VERSION ""

NS_ :

BS_:

BU_: ETH

BO_ 1339 VCBATT1_alertLog: 8 Vector__XXX
 SG_ VCBATT1_alertID M : 0|10@1+ (1,0) [0|0] "" Vector__XXX
 SG_ VCBATT1_alertState : 15|1@1+ (1,0) [0|0] "" Vector__XXX
 SG_ VCBATT1_a001_InternalWatchdog m1 : 16|1@1+ (1,0) [0|0] "" Vector__XXX
 SG_ VCBATT1_a002_CPUUndervoltage m2 : 16|1@1+ (1,0) [0|0] "" Vector__XXX
 SG_ VCBATT1_a003_AssertID m3 : 16|16@1+ (1,0) [0|0] "" Vector__XXX
 SG_ VCBATT1_a005_busID0 m5 : 16|4@1+ (1,0) [0|0] "" Vector__XXX
 SG_ VCBATT1_a006_busID m6 : 16|4@1+ (1,0) [0|0] "" Vector__XXX
 SG_ VCBATT1_a012_ClockError m12 : 16|1@1+ (1,0) [0|0] "" Vector__XXX
 SG_ VCBATT1_a013_LogQueueFull m13 : 16|1@1+ (1,0) [0|0] "" Vector__XXX
 SG_ VCBATT1_a015_NVMMMemOverflow m15 : 16|1@1+ (1,0) [0|0] "" Vector__XXX
 SG_ VCBATT1_a016_NVMMRecordID m16 : 16|16@1+ (1,0) [0|0] "" Vector__XXX
 SG_ VCBATT1_a017_NVMMLifetimeEraseCycles m17 : 16|32@1+ (1,0) [0|0] "" Vector__XXX
 SG_ VCBATT1_a018_DEBUGEVT m18 : 16|1@1+ (1,0) [0|0] "" Vector__XXX
 SG_ VCBATT1_a019_BFARVALID m19 : 16|1@1+ (1,0) [0|0] "" Vector__XXX
 SG_ VCBATT1_a021_Task1msLate m21 : 16|1@1+ (1,0) [0|0] "" Vector__XXX
 SG_ VCBATT1_a022_TaskInitErrorCount m22 : 16|8@1+ (1,0) [0|0] "" Vector__XXX
 SG_ VCBATT1_a028_DivideByZero m28 : 16|1@1+ (1,0) [0|0] "" Vector__XXX
 SG_ VCBATT1_a030_logId m30 : 16|4@1+ (1,0) [0|0] "" Vector__XXX
 SG_ VCBATT1_a031_uds_bytes_0 m31 : 16|8@1+ (1,0) [0|0] "" Vector__XXX
 SG_ VCBATT1_a036_ipsr m36 : 16|8@1+ (1,0) [0|0] "" Vector__XXX
 SG_ VCBATT1_a037_MMFARVALID m37 : 16|1@1+ (1,0) [0|0] "" Vector__XXX
 SG_ VCBATT1_a038_faultType m38 : 16|2@1+ (1,0) [0|0] "" Vector__XXX
 SG_ VCBATT1_a039_faultType m39 : 16|2@1+ (1,0) [0|0] "" Vector__XXX
 SG_ VCBATT1_a040_depth m40 : 16|4@1+ (1,0) [0|0] "" Vector__XXX
 SG_ VCBATT1_a041_CPULoadTotal m41 : 16|8@1+ (1,0) [0|0] "" Vector__XXX
 SG_ VCBATT1_a042_Usage1msTask m42 : 16|8@1+ (1,0) [0|0] "" Vector__XXX
 SG_ VCBATT1_a043_CallTrace0 m43 : 16|24@1+ (1,0) [0|0] "" Vector__XXX
 SG_ VCBATT1_a044_CallTrace0 m44 : 16|24@1+ (1,0) [0|0] "" Vector__XXX
 SG_ VCBATT1_a045_CallTrace0 m45 : 16|24@1+ (1,0) [0|0] "" Vector__XXX
 SG_ VCBATT1_a046_CallTrace0 m46 : 16|24@1+ (1,0) [0|0] "" Vector__XXX
 SG_ VCBATT1_a058_voltageDrop m58 : 16|12@1+ (0.005443676098,0) [0|0] "" Vector__XXX
 SG_ VCBATT1_a059_voltageDrop m59 : 16|12@1+ (0.005443676098,0) [0|0] "" Vector__XXX
 SG_ VCBATT1_a060_lockoutDisabled m60 : 16|1@1+ (1,0) [0|0] "" Vector__XXX
 SG_ VCBATT1_a063_switchChannel m63 : 16|8@1+ (1,0) [0|0] "" Vector__XXX
 SG_ VCBATT1_a064_busBitField m64 : 16|8@1+ (1,0) [0|0] "" Vector__XXX
 SG_ VCBATT1_a077_BATTIPC_battIpcData0 m77 : 16|1@1+ (1,0) [0|0] "" Vector__XXX
 SG_ VCBATT1_a078_FRONTIPC_frontprivData0 m78 : 16|1@1+ (1,0) [0|0] "" Vector__XXX
 SG_ VCBATT1_a079_FRONTIPC_frontprivData0 m79 : 16|1@1+ (1,0) [0|0] "" Vector__XXX
 SG_ VCBATT1_a080_FRONTIPC_frontIpcData0 m80 : 16|1@1+ (1,0) [0|0] "" Vector__XXX
 SG_ VCBATT1_a081_FRONTIPC_vehNm m81 : 16|1@1+ (1,0) [0|0] "" Vector__XXX
 SG_ VCBATT1_a082_FRONTIPC_frontprivData0 m82 : 16|1@1+ (1,0) [0|0] "" Vector__XXX
 SG_ VCBATT1_a086_FRONTIPC_vehNm m86 : 16|1@1+ (1,0) [0|0] "" Vector__XXX
 SG_ VCBATT1_a090_FRONTIPC_chNm m90 : 16|1@1+ (1,0) [0|0] "" Vector__XXX
 SG_ VCBATT1_a091_FRONTIPC_faultsAndExtras m91 : 16|1@1+ (1,0) [0|0] "" Vector__XXX
 SG_ VCBATT1_a096_FRONTIPC_status m96 : 16|1@1+ (1,0) [0|0] "" Vector__XXX
 SG_ VCBATT1_a098_FRONTIPC_temperature m98 : 16|1@1+ (1,0) [0|0] "" Vector__XXX
 SG_ VCBATT1_a100_BATTIPC m100 : 16|1@1+ (1,0) [0|0] "" Vector__XXX
 SG_ VCBATT1_a103_FRONTIPC_hvsNm m103 : 16|1@1+ (1,0) [0|0] "" Vector__XXX
 SG_ VCBATT1_a104_FRONTIPC_chNm m104 : 16|1@1+ (1,0) [0|0] "" Vector__XXX
 SG_ VCBATT1_a105_FRONTIPC_chNm m105 : 16|1@1+ (1,0) [0|0] "" Vector__XXX
 SG_ VCBATT1_a106_BATTIPC_dcdcRailStatus m106 : 16|1@1+ (1,0) [0|0] "" Vector__XXX
 SG_ VCBATT1_a107_FRONTIPC_vehNm m107 : 16|1@1+ (1,0) [0|0] "" Vector__XXX
 SG_ VCBATT1_a108_FRONTIPC_status m108 : 16|1@1+ (1,0) [0|0] "" Vector__XXX
 SG_ VCBATT1_a110_BATTIPC_carConfig m110 : 16|1@1+ (1,0) [0|0] "" Vector__XXX
 SG_ VCBATT1_a111_FRONTIPC_vehNm m111 : 16|1@1+ (1,0) [0|0] "" Vector__XXX
 SG_ VCBATT1_a112_FRONTIPC_vehNm m112 : 16|1@1+ (1,0) [0|0] "" Vector__XXX
 SG_ VCBATT1_a113_FRONTIPC_ethNm m113 : 16|1@1+ (1,0) [0|0] "" Vector__XXX
 SG_ VCBATT1_a114_BATTIPC_wheelRotation m114 : 16|1@1+ (1,0) [0|0] "" Vector__XXX
 SG_ VCBATT1_a115_FRONTIPC_vehNm m115 : 16|1@1+ (1,0) [0|0] "" Vector__XXX
 SG_ VCBATT1_a116_FRONTIPC_vehNm m116 : 16|1@1+ (1,0) [0|0] "" Vector__XXX
 SG_ VCBATT1_a117_FRONTIPC_vehNm m117 : 16|1@1+ (1,0) [0|0] "" Vector__XXX
 SG_ VCBATT1_a118_FRONTIPC_vehNm m118 : 16|1@1+ (1,0) [0|0] "" Vector__XXX
 SG_ VCBATT1_a119_FRONTIPC_leftStalk m119 : 16|1@1+ (1,0) [0|0] "" Vector__XXX
 SG_ VCBATT1_a120_BATTIPC_speed m120 : 16|1@1+ (1,0) [0|0] "" Vector__XXX
 SG_ VCBATT1_a122_FRONTIPC_status m122 : 16|1@1+ (1,0) [0|0] "" Vector__XXX
 SG_ VCBATT1_a124_FRONTIPC_status m124 : 16|1@1+ (1,0) [0|0] "" Vector__XXX
 SG_ VCBATT1_a125_FRONTIPC_leftStalk m125 : 16|1@1+ (1,0) [0|0] "" Vector__XXX
 SG_ VCBATT1_a126_FRONTIPC_sysStatus m126 : 16|1@1+ (1,0) [0|0] "" Vector__XXX
 SG_ VCBATT1_a127_vcleftEFuseCurrent m127 : 16|16@1+ (0.1,0) [0|0] "" Vector__XXX
 SG_ VCBATT1_a129_epas1EFuseCurrent m129 : 16|16@1+ (0.1,0) [0|0] "" Vector__XXX
 SG_ VCBATT1_a130_autopilot1EFuseCurrent m130 : 16|16@1+ (0.1,0) [0|0] "" Vector__XXX
 SG_ VCBATT1_a131_FRONTIPC_power m131 : 16|1@1+ (1,0) [0|0] "" Vector__XXX
 SG_ VCBATT1_a132_iBoosterCurrent m132 : 16|16@1+ (0.1,0) [0|0] "" Vector__XXX
 SG_ VCBATT1_a133_BATTIPC_primaryActuator m133 : 16|1@1+ (1,0) [0|0] "" Vector__XXX
 SG_ VCBATT1_a134_hvContactorsEFuseCurrent m134 : 16|16@1+ (0.1,0) [0|0] "" Vector__XXX
 SG_ VCBATT1_a144_FRONTIPC_status m144 : 16|1@1+ (1,0) [0|0] "" Vector__XXX
 SG_ VCBATT1_a164_lockoutVoltage m164 : 16|16@1+ (0.1,0) [0|0] "" Vector__XXX
 SG_ VCBATT1_a165_lockoutVoltage m165 : 16|16@1+ (0.1,0) [0|0] "" Vector__XXX
 SG_ VCBATT1_a180_vehiclePowerState m180 : 16|2@1+ (1,0) [0|0] "" Vector__XXX
 SG_ VCBATT1_a182_deadLV m182 : 16|1@1+ (1,0) [0|0] "" Vector__XXX
 SG_ VCBATT1_a183_deadLV m183 : 16|1@1+ (1,0) [0|0] "" Vector__XXX
 SG_ VCBATT1_a188_sleepBypassCurrent m188 : 16|8@1+ (0.2,0) [0|0] "" Vector__XXX
 SG_ VCBATT1_a191_vehiclePowerState m191 : 16|2@1+ (1,0) [0|0] "" Vector__XXX
 SG_ VCBATT1_a196_factoryMode m196 : 16|1@1+ (1,0) [0|0] "" Vector__XXX
 SG_ VCBATT1_a204_vbusVoltage m204 : 16|10@1+ (0.025,0) [0|0] "" Vector__XXX
 SG_ VCBATT1_a205_busVoltage m205 : 16|10@1+ (0.025,0) [0|0] "" Vector__XXX
 SG_ VCBATT1_a212_IBSTemp m212 : 16|16@1- (0.01,0) [0|0] "" Vector__XXX
 SG_ VCBATT1_a213_IBSVolts m213 : 16|12@1+ (0.005443676098,0) [0|0] "" Vector__XXX
 SG_ VCBATT1_a215_startReason m215 : 16|3@1+ (1,0) [0|0] "" Vector__XXX
 SG_ VCBATT1_a216_inDrive m216 : 16|1@1+ (1,0) [0|0] "" Vector__XXX
 SG_ VCBATT1_a217_startReason m217 : 16|3@1+ (1,0) [0|0] "" Vector__XXX
 SG_ VCBATT1_a219_IBSVolts m219 : 16|12@1+ (0.005443676098,0) [0|0] "" Vector__XXX
 SG_ VCBATT1_a220_DI_gear m220 : 16|3@1+ (1,0) [0|0] "" Vector__XXX
 SG_ VCBATT1_a221_IBSCurrent m221 : 16|16@1- (0.005,0) [0|0] "" Vector__XXX
 SG_ VCBATT1_a223_failedArmingSetup m223 : 16|1@1+ (1,0) [0|0] "" Vector__XXX
 SG_ VCBATT1_a224_ocSenseAmpCurrent m224 : 16|12@1+ (0.1,0) [0|0] "" Vector__XXX
 SG_ VCBATT1_a225_ocSelfTestFailureReason m225 : 16|7@1+ (1,0) [0|0] "" Vector__XXX
 SG_ VCBATT1_a226_channelFailureReason m226 : 16|7@1+ (1,0) [0|0] "" Vector__XXX
 SG_ VCBATT1_a227_channelFailureReason m227 : 16|7@1+ (1,0) [0|0] "" Vector__XXX
 SG_ VCBATT1_a228_channelFailureReason m228 : 16|7@1+ (1,0) [0|0] "" Vector__XXX
 SG_ VCBATT1_a229_bridgeOpened m229 : 16|1@1+ (1,0) [0|0] "" Vector__XXX
 SG_ VCBATT1_a230_channelFailureReason m230 : 16|7@1+ (1,0) [0|0] "" Vector__XXX
 SG_ VCBATT1_a235_hvcRightDomainFailureReason m235 : 16|3@1+ (1,0) [0|0] "" Vector__XXX
 SG_ VCBATT1_a236_checkPowerFromRightDomain m236 : 16|1@1+ (1,0) [0|0] "" Vector__XXX
 SG_ VCBATT1_a243_IBSVolts m243 : 16|12@1+ (0.005443676098,0) [0|0] "" Vector__XXX
 SG_ VCBATT1_a244_brakeValveECUEFuseCurrent m244 : 16|16@1+ (0.1,0) [0|0] "" Vector__XXX
 SG_ VCBATT1_a245_current m245 : 16|16@1+ (0.1,0) [0|0] "" Vector__XXX
 SG_ VCBATT1_a252_IBSVoltage m252 : 16|12@1+ (0.005443676098,0) [0|0] "" Vector__XXX
 SG_ VCBATT1_a253_currentNotTapered m253 : 16|1@1+ (1,0) [0|0] "" Vector__XXX
 SG_ VCBATT1_a258_minVoltageReached m258 : 16|12@1+ (0.005443676098,0) [0|0] "" Vector__XXX
 SG_ VCBATT1_a259_serviceMode m259 : 16|1@1+ (1,0) [0|0] "" Vector__XXX
 SG_ VCBATT1_a260_IBSVolts m260 : 16|12@1+ (0.005443676098,0) [0|0] "" Vector__XXX
 SG_ VCBATT1_a275_breakLocationA m275 : 16|5@1+ (1,0) [0|0] "" Vector__XXX
 SG_ VCBATT1_a276_breakLocationA m276 : 16|5@1+ (1,0) [0|0] "" Vector__XXX
 SG_ VCBATT1_a277_bmbDeviceMask m277 : 16|16@1+ (1,0) [0|0] "" Vector__XXX
 SG_ VCBATT1_a297_bmbDeviceId m297 : 16|4@1+ (1,1) [0|0] "" Vector__XXX
 SG_ VCBATT1_a359_IBSVolts m359 : 16|12@1+ (0.005443676098,0) [0|0] "" Vector__XXX
 SG_ VCBATT1_a363_minBleedCharge m363 : 16|15@1+ (0.001,0) [0|0] "" Vector__XXX
 SG_ VCBATT1_a370_IBSVolts m370 : 16|12@1+ (0.005443676098,0) [0|0] "" Vector__XXX
 SG_ VCBATT1_a371_shortedCellTestTrigger m371 : 16|1@1+ (1,0) [0|0] "" Vector__XXX
 SG_ VCBATT1_a372_bmbDeviceId m372 : 16|4@1+ (1,1) [0|0] "" Vector__XXX
 SG_ VCBATT1_a376_IBSCurrentSampleCount m376 : 16|16@1+ (1,0) [0|0] "" Vector__XXX
 SG_ VCBATT1_a379_minVoltageReached m379 : 16|12@1+ (0.005443676098,0) [0|0] "" Vector__XXX
 SG_ VCBATT1_a387_shortedCellFaultCounter m387 : 16|3@1+ (1,0) [0|0] "" Vector__XXX
 SG_ VCBATT1_a388_shortedCellFaultCounter m388 : 16|3@1+ (1,0) [0|0] "" Vector__XXX
 SG_ VCBATT1_a392_bmbDeviceId m392 : 16|4@1+ (1,1) [0|0] "" Vector__XXX
 SG_ VCBATT1_a400_VrefSample m400 : 16|16@1+ (0.0001,0) [0|0] "" Vector__XXX
 SG_ VCBATT1_a401_LVBatteryTemp m401 : 16|7@1+ (1,-40) [0|0] "" Vector__XXX
 SG_ VCBATT1_a402_LVBatteryTemp m402 : 16|7@1+ (1,-40) [0|0] "" Vector__XXX
 SG_ VCBATT1_a403_IBSCurrent m403 : 16|15@1- (0.005,0) [0|0] "" Vector__XXX
 SG_ VCBATT1_a404_minVoltageReached m404 : 16|12@1+ (0.005443676098,0) [0|0] "" Vector__XXX
 SG_ VCBATT1_a405_dcrMilliOhms m405 : 16|8@1+ (0.2,0) [0|0] "" Vector__XXX
 SG_ VCBATT1_a406_pulseVoltage1 m406 : 16|8@1+ (0.02,9) [0|0] "" Vector__XXX
 SG_ VCBATT1_a407_dcrMilliOhms m407 : 16|8@1+ (0.2,0) [0|0] "" Vector__XXX
 SG_ VCBATT1_a408_IBSCurrent m408 : 16|16@1- (0.005,0) [0|0] "" Vector__XXX
 SG_ VCBATT1_a410_LVBatteryTemp m410 : 16|7@1+ (1,-40) [0|0] "" Vector__XXX
 SG_ VCBATT1_a411_LVBatteryTemp m411 : 16|7@1+ (1,-40) [0|0] "" Vector__XXX
 SG_ VCBATT1_a412_dcrMilliOhmsShifted m412 : 16|8@1+ (0.2,0) [0|0] "" Vector__XXX
 SG_ VCBATT1_a413_VrefSample m413 : 16|16@1+ (0.0001,0) [0|0] "" Vector__XXX
 SG_ VCBATT1_a414_failureReason m414 : 16|6@1+ (1,0) [0|0] "" Vector__XXX
 SG_ VCBATT1_a415_upstreamEFuseStuckOff m415 : 16|1@1+ (1,0) [0|0] "" Vector__XXX
 SG_ VCBATT1_a416_brickVoltageMin m416 : 16|10@1+ (0.005,0) [0|0] "" Vector__XXX
 SG_ VCBATT1_a417_brickVoltageMin m417 : 16|10@1+ (0.005,0) [0|0] "" Vector__XXX
 SG_ VCBATT1_a418_brickVoltageMin m418 : 16|10@1+ (0.005,0) [0|0] "" Vector__XXX
 SG_ VCBATT1_a419_brickVoltageMin m419 : 16|10@1+ (0.005,0) [0|0] "" Vector__XXX
 SG_ VCBATT1_a420_retryResult m420 : 16|3@1+ (1,0) [0|0] "" Vector__XXX
 SG_ VCBATT1_a422_allBusesSleeping m422 : 16|1@1+ (1,0) [0|0] "" Vector__XXX
 SG_ VCBATT1_a423_brickVoltageMin m423 : 16|10@1+ (0.005,0) [0|0] "" Vector__XXX
 SG_ VCBATT1_a424_brickVoltageMin m424 : 16|10@1+ (0.005,0) [0|0] "" Vector__XXX
 SG_ VCBATT1_a425_busVoltage m425 : 16|16@1+ (0.002,0) [0|0] "" Vector__XXX
 SG_ VCBATT1_a426_busVoltage m426 : 16|16@1+ (0.002,0) [0|0] "" Vector__XXX
 SG_ VCBATT1_a427_initialSoc m427 : 16|9@1+ (0.2,0) [0|0] "" Vector__XXX
 SG_ VCBATT1_a428_minBrickCacId m428 : 16|7@1+ (1,1) [0|0] "" Vector__XXX
 SG_ VCBATT1_a429_sohTestEndMode m429 : 16|4@1+ (1,0) [0|0] "" Vector__XXX
 SG_ VCBATT1_a430_netPackCurrent m430 : 16|16@1- (0.1,0) [0|0] "" Vector__XXX
 SG_ VCBATT1_a431_netPackCurrent m431 : 16|16@1- (0.1,0) [0|0] "" Vector__XXX
 SG_ VCBATT1_a432_targetCurrent m432 : 16|16@1- (0.1,0) [0|0] "" Vector__XXX
 SG_ VCBATT1_a433_bmbModuleId m433 : 16|16@1+ (1,0) [0|0] "" Vector__XXX
 SG_ VCBATT1_a434_bmbModuleId m434 : 16|16@1+ (1,0) [0|0] "" Vector__XXX
 SG_ VCBATT1_a435_netPackCurrent m435 : 16|16@1- (0.1,0) [0|0] "" Vector__XXX
 SG_ VCBATT1_a436_netPackCurrent m436 : 16|16@1- (0.1,0) [0|0] "" Vector__XXX
 SG_ VCBATT1_a437_nvmDataMissingA m437 : 16|1@1+ (1,0) [0|0] "" Vector__XXX
 SG_ VCBATT1_a438_temperature m438 : 16|16@1+ (0.01,0) [0|0] "" Vector__XXX
 SG_ VCBATT1_a439_temperature m439 : 16|16@1+ (0.01,0) [0|0] "" Vector__XXX
 SG_ VCBATT1_a441_bmbModuleId m441 : 16|16@1+ (1,0) [0|0] "" Vector__XXX
 SG_ VCBATT1_a442_maxSocChange m442 : 16|11@1- (0.1,0) [0|0] "" Vector__XXX
 SG_ VCBATT1_a443_bmbDeviceId m443 : 16|4@1+ (1,1) [0|0] "" Vector__XXX
 SG_ VCBATT1_a446_cell1Voltage m446 : 16|9@1+ (0.01,0) [0|0] "" Vector__XXX
 SG_ VCBATT1_a461_socByAhRaw m461 : 16|11@1+ (0.1,0) [0|0] "" Vector__XXX
 SG_ VCBATT1_a462_CellOVLevel1 m462 : 16|1@1+ (1,0) [0|0] "" Vector__XXX
 SG_ VCBATT1_a475_channel m475 : 16|3@1+ (1,0) [0|0] "" Vector__XXX
 SG_ VCBATT1_a476_FRM1_timedOut m476 : 16|1@1+ (1,0) [0|0] "" Vector__XXX
 SG_ VCBATT1_a477_cell1Voltage m477 : 16|9@1+ (0.01,0) [0|0] "" Vector__XXX
 SG_ VCBATT1_a478_battFaultPackOverVoltage m478 : 16|1@1+ (1,0) [0|0] "" Vector__XXX
 SG_ VCBATT1_a479_FRM3_timedOut m479 : 16|1@1+ (1,0) [0|0] "" Vector__XXX
 SG_ VCBATT1_a481_success m481 : 16|1@1+ (1,0) [0|0] "" Vector__XXX
 SG_ VCBATT1_a482_lvBridgeEFuseCurrent m482 : 16|16@1+ (0.1,0) [0|0] "" Vector__XXX
 SG_ VCBATT1_a484_upstreamEFuseStuckOn m484 : 16|1@1+ (1,0) [0|0] "" Vector__XXX
 SG_ VCBATT1_a485_upstreamEfuseUnattemptedOn m485 : 16|1@1+ (1,0) [0|0] "" Vector__XXX
 SG_ VCBATT1_a486_bridgeFailedArmingSetup m486 : 16|1@1+ (1,0) [0|0] "" Vector__XXX
 SG_ VCBATT1_a489_channel m489 : 16|3@1+ (1,0) [0|0] "" Vector__XXX
 SG_ VCBATT1_a490_channel m490 : 16|3@1+ (1,0) [0|0] "" Vector__XXX
 SG_ VCBATT1_a491_channel m491 : 16|3@1+ (1,0) [0|0] "" Vector__XXX
 SG_ VCBATT1_a492_minBrickSocId m492 : 16|7@1+ (1,1) [0|0] "" Vector__XXX
 SG_ VCBATT1_a493_minBrickSocId m493 : 16|7@1+ (1,1) [0|0] "" Vector__XXX
 SG_ VCBATT1_a495_SoCUnrecoverable m495 : 16|1@1+ (1,0) [0|0] "" Vector__XXX
 SG_ VCBATT1_a496_reverseBatteryEFuseFault m496 : 16|1@1+ (1,0) [0|0] "" Vector__XXX
 SG_ VCBATT1_a497_serviceMode m497 : 16|1@1+ (1,0) [0|0] "" Vector__XXX
 SG_ VCBATT1_a498_packTemp m498 : 16|8@1+ (0.5,-20) [0|0] "" Vector__XXX
 SG_ VCBATT1_a502_worstBrickId m502 : 16|7@1+ (1,1) [0|0] "" Vector__XXX
 SG_ VCBATT1_a503_brickVoltageMin m503 : 16|10@1+ (0.005,0) [0|0] "" Vector__XXX
 SG_ VCBATT1_a508_brickImpedance m508 : 16|14@1+ (2.5e-05,0) [0|0] "" Vector__XXX
 SG_ VCBATT1_a509_channel m509 : 16|3@1+ (1,0) [0|0] "" Vector__XXX
 SG_ VCBATT1_a510_sumCellVoltage m510 : 16|8@1+ (0.1,0) [0|0] "" Vector__XXX
 SG_ VCBATT1_a512_packVoltageIntervalMin m512 : 16|8@1+ (0.1,0) [0|0] "" Vector__XXX
 SG_ VCBATT1_a513_packCurrent m513 : 16|12@1+ (0.2,-600) [0|0] "" Vector__XXX
 SG_ VCBATT1_a514_cell1Voltage m514 : 16|7@1+ (0.08,0) [0|0] "" Vector__XXX
 SG_ VCBATT1_a515_cell1Voltage m515 : 16|7@1+ (0.08,0) [0|0] "" Vector__XXX
 SG_ VCBATT1_a518_packVoltage m518 : 16|8@1+ (0.1,0) [0|0] "" Vector__XXX
 SG_ VCBATT1_a521_vcleftEFuseCurrent m521 : 16|16@1- (0.1,0) [0|0] "" Vector__XXX
 SG_ VCBATT1_a525_GTW_twelveVBatteryType m525 : 16|3@1+ (1,0) [0|0] "" Vector__XXX
 SG_ VCBATT1_a527_cell1Voltage m527 : 16|10@1+ (0.01,0) [0|0] "" Vector__XXX
 SG_ VCBATT1_a528_ECPAStateSNA m528 : 16|1@1+ (1,0) [0|0] "" Vector__XXX
 SG_ VCBATT1_a529_sumCellVoltage m529 : 16|8@1+ (0.1,0) [0|0] "" Vector__XXX
 SG_ VCBATT1_a533_temperature m533 : 16|16@1+ (0.01,0) [0|0] "" Vector__XXX
 SG_ VCBATT1_a541_PackTemperature m541 : 16|9@1+ (0.5,-50) [0|0] "" Vector__XXX
 SG_ VCBATT1_a544_serviceMode m544 : 16|1@1+ (1,0) [0|0] "" Vector__XXX
 SG_ VCBATT1_a545_GTW_twelveVBatteryType m545 : 16|3@1+ (1,0) [0|0] "" Vector__XXX
 SG_ VCBATT1_a548_vehiclePowerState m548 : 16|2@1+ (1,0) [0|0] "" Vector__XXX
 SG_ VCBATT1_a555_cell1Voltage m555 : 16|10@1+ (0.01,0) [0|0] "" Vector__XXX
 SG_ VCBATT1_a556_factoryMode m556 : 16|1@1+ (1,0) [0|0] "" Vector__XXX
 SG_ VCBATT1_a559_SOC m559 : 16|7@1+ (1,0) [0|0] "" Vector__XXX
 SG_ VCBATT1_a561_efuseTemperature m561 : 16|5@1+ (4,0) [0|0] "" Vector__XXX
 SG_ VCBATT1_a562_efuseTemperature m562 : 16|5@1+ (4,0) [0|0] "" Vector__XXX
 SG_ VCBATT1_a573_radarCurrent m573 : 16|16@1+ (0.1,0) [0|0] "" Vector__XXX
 SG_ VCBATT1_a575_vbatFusedLoadShedCurrent m575 : 16|16@1+ (0.1,0) [0|0] "" Vector__XXX
 SG_ VCBATT1_a576_mcuLogicCurrent m576 : 16|16@1+ (0.1,0) [0|0] "" Vector__XXX
 SG_ VCBATT1_a580_rightHeadlightCurrent m580 : 16|16@1+ (0.1,0) [0|0] "" Vector__XXX
 SG_ VCBATT1_a581_channel m581 : 16|3@1+ (1,0) [0|0] "" Vector__XXX
 SG_ VCBATT1_a582_batterySMState m582 : 16|4@1+ (1,0) [0|0] "" Vector__XXX
 SG_ VCBATT1_a587_factoryMode m587 : 16|1@1+ (1,0) [0|0] "" Vector__XXX
 SG_ VCBATT1_a588_vcleftEFuseCurveType m588 : 16|1@1+ (1,0) [0|0] "" Vector__XXX
 SG_ VCBATT1_a589_vcleftEFuseFastBlowType m589 : 16|1@1+ (1,0) [0|0] "" Vector__XXX
 SG_ VCBATT1_a592_vcleftCutoffEFuseCurveType m592 : 16|1@1+ (1,0) [0|0] "" Vector__XXX
 SG_ VCBATT1_a593_vcleftCutoffEFuseFastBlowType m593 : 16|1@1+ (1,0) [0|0] "" Vector__XXX
 SG_ VCBATT1_a595_factoryMode m595 : 16|1@1+ (1,0) [0|0] "" Vector__XXX
 SG_ VCBATT1_a599_GTW_twelveVBatteryType m599 : 16|3@1+ (1,0) [0|0] "" Vector__XXX
 SG_ VCBATT1_a600_factoryMode m600 : 16|1@1+ (1,0) [0|0] "" Vector__XXX
 SG_ VCBATT1_a601_subUsageId m601 : 16|16@1+ (1,0) [0|0] "" Vector__XXX
 SG_ VCBATT1_a608_deltaV m608 : 16|16@1+ (0.0001,0) [0|0] "" Vector__XXX
 SG_ VCBATT1_a615_heaterCurrent m615 : 16|9@1- (0.25,0) [0|0] "" Vector__XXX
 SG_ VCBATT1_a617_FRONTIPC_APP_VC_infoMessage m617 : 16|1@1+ (1,0) [0|0] "" Vector__XXX
 SG_ VCBATT1_a628_thermistorId m628 : 16|3@1+ (1,1) [0|0] "" Vector__XXX
 SG_ VCBATT1_a670_packVoltage m670 : 16|10@1+ (0.05,0) [0|0] "" Vector__XXX
 SG_ VCBATT1_a002_PowerOnReset m2 : 17|1@1+ (1,0) [0|0] "" Vector__XXX
 SG_ VCBATT1_a012_FlashError m12 : 17|1@1+ (1,0) [0|0] "" Vector__XXX
 SG_ VCBATT1_a013_ClearQueueFull m13 : 17|1@1+ (1,0) [0|0] "" Vector__XXX
 SG_ VCBATT1_a015_NVMMFilesystemError m15 : 17|1@1+ (1,0) [0|0] "" Vector__XXX
 SG_ VCBATT1_a018_FORCED m18 : 17|1@1+ (1,0) [0|0] "" Vector__XXX
 SG_ VCBATT1_a019_LazyFPStateError m19 : 17|1@1+ (1,0) [0|0] "" Vector__XXX
 SG_ VCBATT1_a021_Task1msStarved m21 : 17|1@1+ (1,0) [0|0] "" Vector__XXX
 SG_ VCBATT1_a028_UnalignedAccess m28 : 17|1@1+ (1,0) [0|0] "" Vector__XXX
 SG_ VCBATT1_a037_LazyFPStateError m37 : 17|1@1+ (1,0) [0|0] "" Vector__XXX
 SG_ VCBATT1_a060_resetUnlocked m60 : 17|1@1+ (1,0) [0|0] "" Vector__XXX
 SG_ VCBATT1_a077_FRONTIPC_frontprivData0 m77 : 17|1@1+ (1,0) [0|0] "" Vector__XXX
 SG_ VCBATT1_a078_BATTIPC_frontprivData0 m78 : 17|1@1+ (1,0) [0|0] "" Vector__XXX
 SG_ VCBATT1_a079_BATTIPC_battIpcData0 m79 : 17|1@1+ (1,0) [0|0] "" Vector__XXX
 SG_ VCBATT1_a081_FRONTIPC_frontprivData0 m81 : 17|1@1+ (1,0) [0|0] "" Vector__XXX
 SG_ VCBATT1_a082_FRONTIPC_frontIpcData0 m82 : 17|1@1+ (1,0) [0|0] "" Vector__XXX
 SG_ VCBATT1_a086_BATTIPC_vehNm m86 : 17|1@1+ (1,0) [0|0] "" Vector__XXX
 SG_ VCBATT1_a090_FRONTIPC_state m90 : 17|1@1+ (1,0) [0|0] "" Vector__XXX
 SG_ VCBATT1_a091_FRONTIPC_state m91 : 17|1@1+ (1,0) [0|0] "" Vector__XXX
 SG_ VCBATT1_a098_FRONTIPC_thermalControl m98 : 17|1@1+ (1,0) [0|0] "" Vector__XXX
 SG_ VCBATT1_a100_FRONTIPC m100 : 17|1@1+ (1,0) [0|0] "" Vector__XXX
 SG_ VCBATT1_a103_FRONTIPC_status m103 : 17|1@1+ (1,0) [0|0] "" Vector__XXX
 SG_ VCBATT1_a104_FRONTIPC_autonomyControl m104 : 17|1@1+ (1,0) [0|0] "" Vector__XXX
 SG_ VCBATT1_a106_BATTIPC_dcdcStatus m106 : 17|1@1+ (1,0) [0|0] "" Vector__XXX
 SG_ VCBATT1_a107_FRONTIPC_status m107 : 17|1@1+ (1,0) [0|0] "" Vector__XXX
 SG_ VCBATT1_a108_FRONTIPC_temperature m108 : 17|1@1+ (1,0) [0|0] "" Vector__XXX
 SG_ VCBATT1_a110_BATTIPC_carState m110 : 17|1@1+ (1,0) [0|0] "" Vector__XXX
 SG_ VCBATT1_a111_FRONTIPC_status m111 : 17|1@1+ (1,0) [0|0] "" Vector__XXX
 SG_ VCBATT1_a112_FRONTIPC_status m112 : 17|1@1+ (1,0) [0|0] "" Vector__XXX
 SG_ VCBATT1_a113_FRONTIPC_powerRationalityConfig m113 : 17|1@1+ (1,0) [0|0] "" Vector__XXX
 SG_ VCBATT1_a114_FRONTIPC_wheelRotation m114 : 17|1@1+ (1,0) [0|0] "" Vector__XXX
 SG_ VCBATT1_a115_BATTIPC_requests m115 : 17|1@1+ (1,0) [0|0] "" Vector__XXX
 SG_ VCBATT1_a116_FRONTIPC_hvacRequest m116 : 17|1@1+ (1,0) [0|0] "" Vector__XXX
 SG_ VCBATT1_a117_FRONTIPC_switchStatus m117 : 17|1@1+ (1,0) [0|0] "" Vector__XXX
 SG_ VCBATT1_a118_BATTIPC_vehNm m118 : 17|1@1+ (1,0) [0|0] "" Vector__XXX
 SG_ VCBATT1_a120_FRONTIPC_speed m120 : 17|1@1+ (1,0) [0|0] "" Vector__XXX
 SG_ VCBATT1_a122_FRONTIPC_nonLocalizedOccupancy m122 : 17|1@1+ (1,0) [0|0] "" Vector__XXX
 SG_ VCBATT1_a124_BATTIPC_status m124 : 17|1@1+ (1,0) [0|0] "" Vector__XXX
 SG_ VCBATT1_a125_FRONTIPC_steerAngle m125 : 17|1@1+ (1,0) [0|0] "" Vector__XXX
 SG_ VCBATT1_a126_BATTIPC_sysStatus m126 : 17|1@1+ (1,0) [0|0] "" Vector__XXX
 SG_ VCBATT1_a131_BATTIPC_power m131 : 17|1@1+ (1,0) [0|0] "" Vector__XXX
 SG_ VCBATT1_a133_FRONTIPC_secondaryActuator m133 : 17|1@1+ (1,0) [0|0] "" Vector__XXX
 SG_ VCBATT1_a144_BATTIPC_status m144 : 17|1@1+ (1,0) [0|0] "" Vector__XXX
 SG_ VCBATT1_a182_voltageDrop m182 : 17|1@1+ (1,0) [0|0] "" Vector__XXX
 SG_ VCBATT1_a183_voltageDrop m183 : 17|1@1+ (1,0) [0|0] "" Vector__XXX
 SG_ VCBATT1_a196_serviceMode m196 : 17|1@1+ (1,0) [0|0] "" Vector__XXX
 SG_ VCBATT1_a216_hvState m216 : 17|3@1+ (1,0) [0|0] "" Vector__XXX
 SG_ VCBATT1_a223_failedFaultInject m223 : 17|1@1+ (1,0) [0|0] "" Vector__XXX
 SG_ VCBATT1_a229_lvBatteryElecDisc m229 : 17|1@1+ (1,0) [0|0] "" Vector__XXX
 SG_ VCBATT1_a236_checkPowerFromLeftDomain m236 : 17|1@1+ (1,0) [0|0] "" Vector__XXX
 SG_ VCBATT1_a253_ampHourTargetNotReached m253 : 17|1@1+ (1,0) [0|0] "" Vector__XXX
 SG_ VCBATT1_a259_voltageDropCounter m259 : 17|3@1+ (2,0) [0|0] "" Vector__XXX
 SG_ VCBATT1_a371_voltDropOnHighCurrentTrigger m371 : 17|1@1+ (1,0) [0|0] "" Vector__XXX
 SG_ VCBATT1_a422_vehBusAwake m422 : 17|1@1+ (1,0) [0|0] "" Vector__XXX
 SG_ VCBATT1_a437_nvmDataMissingB m437 : 17|1@1+ (1,0) [0|0] "" Vector__XXX
 SG_ VCBATT1_a462_CellOVLevel2 m462 : 17|1@1+ (1,0) [0|0] "" Vector__XXX
 SG_ VCBATT1_a476_FRM2_timedOut m476 : 17|1@1+ (1,0) [0|0] "" Vector__XXX
 SG_ VCBATT1_a478_battFaultHardwareOverCurrent m478 : 17|1@1+ (1,0) [0|0] "" Vector__XXX
 SG_ VCBATT1_a479_ECPAState m479 : 17|2@1+ (1,0) [0|0] "" Vector__XXX
 SG_ VCBATT1_a481_timeToCloseMs m481 : 17|7@1+ (20,0) [0|0] "" Vector__XXX
 SG_ VCBATT1_a484_upstreamEFuseVoltage m484 : 17|6@1+ (1,0) [0|0] "" Vector__XXX
 SG_ VCBATT1_a486_bridgeFailedSyncCheck m486 : 17|1@1+ (1,0) [0|0] "" Vector__XXX
 SG_ VCBATT1_a495_SocTooLow m495 : 17|1@1+ (1,0) [0|0] "" Vector__XXX
 SG_ VCBATT1_a496_vehicleLoadShedActive m496 : 17|1@1+ (1,0) [0|0] "" Vector__XXX
 SG_ VCBATT1_a497_FactoryMode m497 : 17|1@1+ (1,0) [0|0] "" Vector__XXX
 SG_ VCBATT1_a528_ECPAFrameTimeout m528 : 17|1@1+ (1,0) [0|0] "" Vector__XXX
 SG_ VCBATT1_a544_frunkOpen m544 : 17|1@1+ (1,0) [0|0] "" Vector__XXX
 SG_ VCBATT1_a556_serviceMode m556 : 17|1@1+ (1,0) [0|0] "" Vector__XXX
 SG_ VCBATT1_a587_serviceMode m587 : 17|1@1+ (1,0) [0|0] "" Vector__XXX
 SG_ VCBATT1_a588_vcleftCurveOffsetChannel m588 : 17|3@1+ (1,0) [0|0] "" Vector__XXX
 SG_ VCBATT1_a589_vcleftCurrentThreshold m589 : 17|12@1+ (0.1,0) [0|0] "" Vector__XXX
 SG_ VCBATT1_a592_vcleftCutoffCurveOffsetChannel m592 : 17|3@1+ (1,0) [0|0] "" Vector__XXX
 SG_ VCBATT1_a593_vcleftCutoffCurrentThreshold m593 : 17|12@1+ (0.1,0) [0|0] "" Vector__XXX
 SG_ VCBATT1_a595_serviceMode m595 : 17|1@1+ (1,0) [0|0] "" Vector__XXX
 SG_ VCBATT1_a600_serviceMode m600 : 17|1@1+ (1,0) [0|0] "" Vector__XXX
 SG_ VCBATT1_a617_FRONTIPC_VC_infoMessage m617 : 17|1@1+ (1,0) [0|0] "" Vector__XXX
 SG_ VCBATT1_a012_SoftwareReset m12 : 18|1@1+ (1,0) [0|0] "" Vector__XXX
 SG_ VCBATT1_a015_NVMMRecordIDError m15 : 18|1@1+ (1,0) [0|0] "" Vector__XXX
 SG_ VCBATT1_a018_VECTTBL m18 : 18|1@1+ (1,0) [0|0] "" Vector__XXX
 SG_ VCBATT1_a019_ImpreciseBusErr m19 : 18|1@1+ (1,0) [0|0] "" Vector__XXX
 SG_ VCBATT1_a021_Task1msMissed m21 : 18|1@1+ (1,0) [0|0] "" Vector__XXX
 SG_ VCBATT1_a028_NoCoprocessor m28 : 18|1@1+ (1,0) [0|0] "" Vector__XXX
 SG_ VCBATT1_a037_InstrAccessViolation m37 : 18|1@1+ (1,0) [0|0] "" Vector__XXX
 SG_ VCBATT1_a038_userRead m38 : 18|1@1+ (1,0) [0|0] "" Vector__XXX
 SG_ VCBATT1_a078_BATTIPC_battIpcData0 m78 : 18|1@1+ (1,0) [0|0] "" Vector__XXX
 SG_ VCBATT1_a079_BATTIPC_frontprivData0 m79 : 18|1@1+ (1,0) [0|0] "" Vector__XXX
 SG_ VCBATT1_a081_FRONTIPC_frontIpcData0 m81 : 18|1@1+ (1,0) [0|0] "" Vector__XXX
 SG_ VCBATT1_a082_FRONTIPC_frontIpcData4 m82 : 18|1@1+ (1,0) [0|0] "" Vector__XXX
 SG_ VCBATT1_a086_BATTIPC_battIpcData0 m86 : 18|1@1+ (1,0) [0|0] "" Vector__XXX
 SG_ VCBATT1_a090_FRONTIPC_status m90 : 18|1@1+ (1,0) [0|0] "" Vector__XXX
 SG_ VCBATT1_a103_FRONTIPC_evseStatus m103 : 18|1@1+ (1,0) [0|0] "" Vector__XXX
 SG_ VCBATT1_a104_FRONTIPC_bodyControls m104 : 18|1@1+ (1,0) [0|0] "" Vector__XXX
 SG_ VCBATT1_a106_VEH_dcdcStatus m106 : 18|1@1+ (1,0) [0|0] "" Vector__XXX
 SG_ VCBATT1_a107_BATTIPC_socStatus m107 : 18|1@1+ (1,0) [0|0] "" Vector__XXX
 SG_ VCBATT1_a108_FRONTIPC_thermalControl m108 : 18|1@1+ (1,0) [0|0] "" Vector__XXX
 SG_ VCBATT1_a110_BATTIPC_mismatchFault m110 : 18|1@1+ (1,0) [0|0] "" Vector__XXX
 SG_ VCBATT1_a111_BATTIPC_status m111 : 18|1@1+ (1,0) [0|0] "" Vector__XXX
 SG_ VCBATT1_a112_BATTIPC_status m112 : 18|1@1+ (1,0) [0|0] "" Vector__XXX
 SG_ VCBATT1_a113_FRONTIPC_vehicleControl2 m113 : 18|1@1+ (1,0) [0|0] "" Vector__XXX
 SG_ VCBATT1_a115_BATTIPC_authentication m115 : 18|1@1+ (1,0) [0|0] "" Vector__XXX
 SG_ VCBATT1_a116_FRONTIPC_doorStatus m116 : 18|1@1+ (1,0) [0|0] "" Vector__XXX
 SG_ VCBATT1_a117_FRONTIPC_doorStatus m117 : 18|1@1+ (1,0) [0|0] "" Vector__XXX
 SG_ VCBATT1_a118_FRONTIPC_frontprivData0 m118 : 18|1@1+ (1,0) [0|0] "" Vector__XXX
 SG_ VCBATT1_a120_FRONTIPC_systemStatus m120 : 18|1@1+ (1,0) [0|0] "" Vector__XXX
 SG_ VCBATT1_a122_FRONTIPC_occupancy m122 : 18|1@1+ (1,0) [0|0] "" Vector__XXX
 SG_ VCBATT1_a125_FRONTIPC_info m125 : 18|1@1+ (1,0) [0|0] "" Vector__XXX
 SG_ VCBATT1_a126_FRONTIPC_status m126 : 18|1@1+ (1,0) [0|0] "" Vector__XXX
 SG_ VCBATT1_a180_hvState m180 : 18|3@1+ (1,0) [0|0] "" Vector__XXX
 SG_ VCBATT1_a182_overcharge m182 : 18|1@1+ (1,0) [0|0] "" Vector__XXX
 SG_ VCBATT1_a183_overcharge m183 : 18|1@1+ (1,0) [0|0] "" Vector__XXX
 SG_ VCBATT1_a191_hvState m191 : 18|3@1+ (1,0) [0|0] "" Vector__XXX
 SG_ VCBATT1_a196_transportMode m196 : 18|1@1+ (1,0) [0|0] "" Vector__XXX
 SG_ VCBATT1_a223_overvoltageFaultActive m223 : 18|1@1+ (1,0) [0|0] "" Vector__XXX
 SG_ VCBATT1_a229_lvBatteryEFuseOff m229 : 18|1@1+ (1,0) [0|0] "" Vector__XXX
 SG_ VCBATT1_a236_hvcLeftDomainPowerFeedVoltage m236 : 18|12@1+ (0.005443676098,0) [0|0] "" Vector__XXX
 SG_ VCBATT1_a253_IBSCurrent m253 : 18|16@1- (0.005,0) [0|0] "" Vector__XXX
 SG_ VCBATT1_a371_deadLVMinimalAhDischargedTrigger m371 : 18|1@1+ (1,0) [0|0] "" Vector__XXX
 SG_ VCBATT1_a422_frontPrivBusAwake m422 : 18|1@1+ (1,0) [0|0] "" Vector__XXX
 SG_ VCBATT1_a462_CellOVLevel3 m462 : 18|1@1+ (1,0) [0|0] "" Vector__XXX
 SG_ VCBATT1_a476_FRM3_timedOut m476 : 18|1@1+ (1,0) [0|0] "" Vector__XXX
 SG_ VCBATT1_a478_battFaultChargeOverCurrent m478 : 18|1@1+ (1,0) [0|0] "" Vector__XXX
 SG_ VCBATT1_a486_localBridgeOutputOn m486 : 18|1@1+ (1,0) [0|0] "" Vector__XXX
 SG_ VCBATT1_a495_retryExpended m495 : 18|1@1+ (1,0) [0|0] "" Vector__XXX
 SG_ VCBATT1_a496_MOSState m496 : 18|2@1+ (1,0) [0|0] "" Vector__XXX
 SG_ VCBATT1_a528_currentSenseFaulted m528 : 18|1@1+ (1,0) [0|0] "" Vector__XXX
 SG_ VCBATT1_a544_LVBMSSOC m544 : 18|5@1+ (3,0) [0|0] "" Vector__XXX
 SG_ VCBATT1_a548_notEnoughPowerForSupport m548 : 18|1@1+ (1,0) [0|0] "" Vector__XXX
 SG_ VCBATT1_a556_transportMode m556 : 18|1@1+ (1,0) [0|0] "" Vector__XXX
 SG_ VCBATT1_a587_transportMode m587 : 18|1@1+ (1,0) [0|0] "" Vector__XXX
 SG_ VCBATT1_a595_transportMode m595 : 18|1@1+ (1,0) [0|0] "" Vector__XXX
 SG_ VCBATT1_a600_transportMode m600 : 18|1@1+ (1,0) [0|0] "" Vector__XXX
 SG_ VCBATT1_a617_FRONTIPC_status m617 : 18|1@1+ (1,0) [0|0] "" Vector__XXX
 SG_ VCBATT1_a012_CheckstopReset m12 : 19|1@1+ (1,0) [0|0] "" Vector__XXX
 SG_ VCBATT1_a018_MMFARVALID m18 : 19|1@1+ (1,0) [0|0] "" Vector__XXX
 SG_ VCBATT1_a019_PreciseBusErr m19 : 19|1@1+ (1,0) [0|0] "" Vector__XXX
 SG_ VCBATT1_a021_Task10msLate m21 : 19|1@1+ (1,0) [0|0] "" Vector__XXX
 SG_ VCBATT1_a028_InvalidPCLoad m28 : 19|1@1+ (1,0) [0|0] "" Vector__XXX
 SG_ VCBATT1_a037_DataAccessViolation m37 : 19|1@1+ (1,0) [0|0] "" Vector__XXX
 SG_ VCBATT1_a038_userWrite m38 : 19|1@1+ (1,0) [0|0] "" Vector__XXX
 SG_ VCBATT1_a078_FRONTIPC_12VBatteryStatus m78 : 19|1@1+ (1,0) [0|0] "" Vector__XXX
 SG_ VCBATT1_a079_FRONTIPC_frontprivData1 m79 : 19|1@1+ (1,0) [0|0] "" Vector__XXX
 SG_ VCBATT1_a081_BATTIPC_frontprivData0 m81 : 19|1@1+ (1,0) [0|0] "" Vector__XXX
 SG_ VCBATT1_a082_FRONTIPC_frontIpcData1 m82 : 19|1@1+ (1,0) [0|0] "" Vector__XXX
 SG_ VCBATT1_a086_FRONTIPC_frontprivData0 m86 : 19|1@1+ (1,0) [0|0] "" Vector__XXX
 SG_ VCBATT1_a090_BATTIPC_state m90 : 19|1@1+ (1,0) [0|0] "" Vector__XXX
 SG_ VCBATT1_a104_FRONTIPC_evseStatus m104 : 19|1@1+ (1,0) [0|0] "" Vector__XXX
 SG_ VCBATT1_a106_VEH_thermalControl m106 : 19|1@1+ (1,0) [0|0] "" Vector__XXX
 SG_ VCBATT1_a107_BATTIPC_status m107 : 19|1@1+ (1,0) [0|0] "" Vector__XXX
 SG_ VCBATT1_a108_FRONTIPC_motorStatus m108 : 19|1@1+ (1,0) [0|0] "" Vector__XXX
 SG_ VCBATT1_a110_BATTIPC_time m110 : 19|1@1+ (1,0) [0|0] "" Vector__XXX
 SG_ VCBATT1_a113_BATTIPC_powerRationalityConfig m113 : 19|1@1+ (1,0) [0|0] "" Vector__XXX
 SG_ VCBATT1_a115_FRONTIPC_authentication m115 : 19|1@1+ (1,0) [0|0] "" Vector__XXX
 SG_ VCBATT1_a116_FRONTIPC_LVPowerState m116 : 19|1@1+ (1,0) [0|0] "" Vector__XXX
 SG_ VCBATT1_a117_FRONTIPC_LVPowerState m117 : 19|1@1+ (1,0) [0|0] "" Vector__XXX
 SG_ VCBATT1_a118_FRONTIPC_frontIpcData0 m118 : 19|1@1+ (1,0) [0|0] "" Vector__XXX
 SG_ VCBATT1_a120_BATTIPC_systemStatus m120 : 19|1@1+ (1,0) [0|0] "" Vector__XXX
 SG_ VCBATT1_a122_FRONTIPC_occupancy2 m122 : 19|1@1+ (1,0) [0|0] "" Vector__XXX
 SG_ VCBATT1_a126_BATTIPC_status m126 : 19|1@1+ (1,0) [0|0] "" Vector__XXX
 SG_ VCBATT1_a182_LVFloorReached m182 : 19|1@1+ (1,0) [0|0] "" Vector__XXX
 SG_ VCBATT1_a183_LVFloorReached m183 : 19|1@1+ (1,0) [0|0] "" Vector__XXX
 SG_ VCBATT1_a196_frunkOpen m196 : 19|1@1+ (1,0) [0|0] "" Vector__XXX
 SG_ VCBATT1_a215_timeToCompleteSeconds m215 : 19|13@1+ (0.01,0) [0|0] "" Vector__XXX
 SG_ VCBATT1_a217_factoryGated m217 : 19|1@1+ (1,0) [0|0] "" Vector__XXX
 SG_ VCBATT1_a220_inDriverlessMode m220 : 19|1@1+ (1,0) [0|0] "" Vector__XXX
 SG_ VCBATT1_a223_sharedBridgeShutdownActive m223 : 19|1@1+ (1,0) [0|0] "" Vector__XXX
 SG_ VCBATT1_a229_lvBatteryActiveDecelEnergy m229 : 19|1@1+ (1,0) [0|0] "" Vector__XXX
 SG_ VCBATT1_a235_hvcLeftDomainFailureReason m235 : 19|3@1+ (1,0) [0|0] "" Vector__XXX
 SG_ VCBATT1_a371_resistanceEstimationHardFailTrigger m371 : 19|1@1+ (1,0) [0|0] "" Vector__XXX
 SG_ VCBATT1_a387_minVoltageReached m387 : 19|12@1+ (0.005443676098,0) [0|0] "" Vector__XXX
 SG_ VCBATT1_a388_minVoltageReached m388 : 19|12@1+ (0.005443676098,0) [0|0] "" Vector__XXX
 SG_ VCBATT1_a422_sleepShutdownComplete m422 : 19|1@1+ (1,0) [0|0] "" Vector__XXX
 SG_ VCBATT1_a462_CellUVLevel1 m462 : 19|1@1+ (1,0) [0|0] "" Vector__XXX
 SG_ VCBATT1_a475_reset m475 : 19|1@1+ (1,0) [0|0] "" Vector__XXX
 SG_ VCBATT1_a476_FRM4_timedOut m476 : 19|1@1+ (1,0) [0|0] "" Vector__XXX
 SG_ VCBATT1_a478_battFaultCellUnderVoltage m478 : 19|1@1+ (1,0) [0|0] "" Vector__XXX
 SG_ VCBATT1_a479_factoryMode m479 : 19|1@1+ (1,0) [0|0] "" Vector__XXX
 SG_ VCBATT1_a486_localBridgeSyncArmed m486 : 19|1@1+ (1,0) [0|0] "" Vector__XXX
 SG_ VCBATT1_a490_timeout m490 : 19|1@1+ (1,0) [0|0] "" Vector__XXX
 SG_ VCBATT1_a491_lockedModeEnable m491 : 19|1@1+ (1,0) [0|0] "" Vector__XXX
 SG_ VCBATT1_a495_LVBMSMIA m495 : 19|1@1+ (1,0) [0|0] "" Vector__XXX
 SG_ VCBATT1_a509_state m509 : 19|3@1+ (1,0) [0|0] "" Vector__XXX
 SG_ VCBATT1_a525_newLVBatteryType m525 : 19|3@1+ (1,0) [0|0] "" Vector__XXX
 SG_ VCBATT1_a528_serviceMode m528 : 19|1@1+ (1,0) [0|0] "" Vector__XXX
 SG_ VCBATT1_a545_newLVBatteryType m545 : 19|3@1+ (1,0) [0|0] "" Vector__XXX
 SG_ VCBATT1_a548_HVBlockingMismatch m548 : 19|1@1+ (1,0) [0|0] "" Vector__XXX
 SG_ VCBATT1_a556_frunkOpen m556 : 19|1@1+ (1,0) [0|0] "" Vector__XXX
 SG_ VCBATT1_a581_resistance m581 : 19|10@1+ (0.0005,0) [0|0] "" Vector__XXX
 SG_ VCBATT1_a587_frunkOpen m587 : 19|1@1+ (1,0) [0|0] "" Vector__XXX
 SG_ VCBATT1_a595_frunkOpen m595 : 19|1@1+ (1,0) [0|0] "" Vector__XXX
 SG_ VCBATT1_a599_newLVBatteryType m599 : 19|3@1+ (1,0) [0|0] "" Vector__XXX
 SG_ VCBATT1_a600_frunkOpen m600 : 19|1@1+ (1,0) [0|0] "" Vector__XXX
 SG_ VCBATT1_a617_BATTIPC_status m617 : 19|1@1+ (1,0) [0|0] "" Vector__XXX
 SG_ VCBATT1_a628_thermistorFailureReason m628 : 19|3@1+ (1,0) [0|0] "" Vector__XXX
 SG_ VCBATT1_a005_faults0 m5 : 20|12@1+ (1,0) [0|0] "" Vector__XXX
 SG_ VCBATT1_a006_fault m6 : 20|4@1+ (1,0) [0|0] "" Vector__XXX
 SG_ VCBATT1_a012_DebugReset m12 : 20|1@1+ (1,0) [0|0] "" Vector__XXX
 SG_ VCBATT1_a018_BFARVALID m18 : 20|1@1+ (1,0) [0|0] "" Vector__XXX
 SG_ VCBATT1_a019_InstrBusErr m19 : 20|1@1+ (1,0) [0|0] "" Vector__XXX
 SG_ VCBATT1_a021_Task10msStarved m21 : 20|1@1+ (1,0) [0|0] "" Vector__XXX
 SG_ VCBATT1_a028_InvalidState m28 : 20|1@1+ (1,0) [0|0] "" Vector__XXX
 SG_ VCBATT1_a038_userExecute m38 : 20|1@1+ (1,0) [0|0] "" Vector__XXX
 SG_ VCBATT1_a078_FRONTIPC_LVHealth m78 : 20|1@1+ (1,0) [0|0] "" Vector__XXX
 SG_ VCBATT1_a079_BATTIPC_frontprivData2 m79 : 20|1@1+ (1,0) [0|0] "" Vector__XXX
 SG_ VCBATT1_a081_BATTIPC_LVHealth m81 : 20|1@1+ (1,0) [0|0] "" Vector__XXX
 SG_ VCBATT1_a082_BATTIPC_frontprivData0 m82 : 20|1@1+ (1,0) [0|0] "" Vector__XXX
 SG_ VCBATT1_a090_BATTIPC_vbatVoltage m90 : 20|1@1+ (1,0) [0|0] "" Vector__XXX
 SG_ VCBATT1_a104_FRONTIPC_thermalStatus m104 : 20|1@1+ (1,0) [0|0] "" Vector__XXX
 SG_ VCBATT1_a106_VEH_dcdcRailStatus m106 : 20|1@1+ (1,0) [0|0] "" Vector__XXX
 SG_ VCBATT1_a107_BATTIPC_energyStatus m107 : 20|1@1+ (1,0) [0|0] "" Vector__XXX
 SG_ VCBATT1_a110_BATTIPC_updateStatus m110 : 20|1@1+ (1,0) [0|0] "" Vector__XXX
 SG_ VCBATT1_a113_BATTIPC_status m113 : 20|1@1+ (1,0) [0|0] "" Vector__XXX
 SG_ VCBATT1_a115_FRONTIPC_requests m115 : 20|1@1+ (1,0) [0|0] "" Vector__XXX
 SG_ VCBATT1_a116_FRONTIPC_thsStatus m116 : 20|1@1+ (1,0) [0|0] "" Vector__XXX
 SG_ VCBATT1_a117_FRONTIPC_bmbMinMax m117 : 20|1@1+ (1,0) [0|0] "" Vector__XXX
 SG_ VCBATT1_a118_BATTIPC_LVHealth m118 : 20|1@1+ (1,0) [0|0] "" Vector__XXX
 SG_ VCBATT1_a120_FRONTIPC_systemPower m120 : 20|1@1+ (1,0) [0|0] "" Vector__XXX
 SG_ VCBATT1_a182_shortedCell m182 : 20|1@1+ (1,0) [0|0] "" Vector__XXX
 SG_ VCBATT1_a183_shortedCell m183 : 20|1@1+ (1,0) [0|0] "" Vector__XXX
 SG_ VCBATT1_a196_vehiclePowerState m196 : 20|2@1+ (1,0) [0|0] "" Vector__XXX
 SG_ VCBATT1_a216_vcleftFastBlowImminent m216 : 20|1@1+ (1,0) [0|0] "" Vector__XXX
 SG_ VCBATT1_a217_battDomainOvercurrentResult m217 : 20|2@1+ (1,0) [0|0] "" Vector__XXX
 SG_ VCBATT1_a220_vehicleSpeed m220 : 20|12@1+ (0.08,-40) [0|0] "" Vector__XXX
 SG_ VCBATT1_a223_timedOut m223 : 20|1@1+ (1,0) [0|0] "" Vector__XXX
 SG_ VCBATT1_a229_lvBatteryRevEfuseOff m229 : 20|1@1+ (1,0) [0|0] "" Vector__XXX
 SG_ VCBATT1_a259_minVoltageReached m259 : 20|12@1+ (0.005443676098,0) [0|0] "" Vector__XXX
 SG_ VCBATT1_a371_dcrMilliOhmsAboveThresholdTrigger m371 : 20|1@1+ (1,0) [0|0] "" Vector__XXX
 SG_ VCBATT1_a422_sleepRequest m422 : 20|1@1+ (1,0) [0|0] "" Vector__XXX
 SG_ VCBATT1_a429_depthOfDischarge m429 : 20|10@1+ (0.1,-0.1) [0|0] "" Vector__XXX
 SG_ VCBATT1_a443_maxDieTemp m443 : 20|10@1+ (0.2,-20) [0|0] "" Vector__XXX
 SG_ VCBATT1_a462_CellUVLevel2 m462 : 20|1@1+ (1,0) [0|0] "" Vector__XXX
 SG_ VCBATT1_a475_spiError m475 : 20|1@1+ (1,0) [0|0] "" Vector__XXX
 SG_ VCBATT1_a476_FRM5_timedOut m476 : 20|1@1+ (1,0) [0|0] "" Vector__XXX
 SG_ VCBATT1_a478_battFaultCellOverVoltage m478 : 20|1@1+ (1,0) [0|0] "" Vector__XXX
 SG_ VCBATT1_a479_serviceMode m479 : 20|1@1+ (1,0) [0|0] "" Vector__XXX
 SG_ VCBATT1_a486_localBridgeDinState m486 : 20|1@1+ (1,0) [0|0] "" Vector__XXX
 SG_ VCBATT1_a490_outputOn m490 : 20|1@1+ (1,0) [0|0] "" Vector__XXX
 SG_ VCBATT1_a491_nvmDefCfgEn m491 : 20|1@1+ (1,0) [0|0] "" Vector__XXX
 SG_ VCBATT1_a495_reverseBatteryEFuseFault m495 : 20|1@1+ (1,0) [0|0] "" Vector__XXX
 SG_ VCBATT1_a496_serviceMode m496 : 20|1@1+ (1,0) [0|0] "" Vector__XXX
 SG_ VCBATT1_a528_frunkOpen m528 : 20|1@1+ (1,0) [0|0] "" Vector__XXX
 SG_ VCBATT1_a548_LVBatteryCannotSupportVehicle m548 : 20|1@1+ (1,0) [0|0] "" Vector__XXX
 SG_ VCBATT1_a556_vehiclePowerState m556 : 20|2@1+ (1,0) [0|0] "" Vector__XXX
 SG_ VCBATT1_a587_LVBMS_packCurrent_valid m587 : 20|1@1+ (1,0) [0|0] "" Vector__XXX
 SG_ VCBATT1_a595_vehiclePowerState m595 : 20|2@1+ (1,0) [0|0] "" Vector__XXX
 SG_ VCBATT1_a600_vehiclePowerState m600 : 20|2@1+ (1,0) [0|0] "" Vector__XXX
 SG_ VCBATT1_a617_FRONTIPC_defogInfoMessage m617 : 20|1@1+ (1,0) [0|0] "" Vector__XXX
 SG_ VCBATT1_a012_ExternalReset m12 : 21|1@1+ (1,0) [0|0] "" Vector__XXX
 SG_ VCBATT1_a021_Task10msMissed m21 : 21|1@1+ (1,0) [0|0] "" Vector__XXX
 SG_ VCBATT1_a028_UndefInstr m28 : 21|1@1+ (1,0) [0|0] "" Vector__XXX
 SG_ VCBATT1_a038_privilegedRead m38 : 21|1@1+ (1,0) [0|0] "" Vector__XXX
 SG_ VCBATT1_a078_FRONTIPC_LVSelfTests m78 : 21|1@1+ (1,0) [0|0] "" Vector__XXX
 SG_ VCBATT1_a079_FRONTIPC_frontprivData2 m79 : 21|1@1+ (1,0) [0|0] "" Vector__XXX
 SG_ VCBATT1_a081_BATTIPC_LVSelfTests m81 : 21|1@1+ (1,0) [0|0] "" Vector__XXX
 SG_ VCBATT1_a090_FRONTIPC_vbatVoltage m90 : 21|1@1+ (1,0) [0|0] "" Vector__XXX
 SG_ VCBATT1_a104_FRONTIPC_status m104 : 21|1@1+ (1,0) [0|0] "" Vector__XXX
 SG_ VCBATT1_a106_CH_dcdcRailStatus m106 : 21|1@1+ (1,0) [0|0] "" Vector__XXX
 SG_ VCBATT1_a107_FRONTIPC_bmbMinMax m107 : 21|1@1+ (1,0) [0|0] "" Vector__XXX
 SG_ VCBATT1_a110_FRONTIPC_vehNm m110 : 21|1@1+ (1,0) [0|0] "" Vector__XXX
 SG_ VCBATT1_a113_BATTIPC_vehicleControl m113 : 21|1@1+ (1,0) [0|0] "" Vector__XXX
 SG_ VCBATT1_a115_FRONTIPC_thsStatus m115 : 21|1@1+ (1,0) [0|0] "" Vector__XXX
 SG_ VCBATT1_a116_FRONTIPC_status m116 : 21|1@1+ (1,0) [0|0] "" Vector__XXX
 SG_ VCBATT1_a117_FRONTIPC_chargeInfo m117 : 21|1@1+ (1,0) [0|0] "" Vector__XXX
 SG_ VCBATT1_a118_BATTIPC_LVPowerState m118 : 21|1@1+ (1,0) [0|0] "" Vector__XXX
 SG_ VCBATT1_a120_FRONTIPC_autonomyHealth m120 : 21|1@1+ (1,0) [0|0] "" Vector__XXX
 SG_ VCBATT1_a182_postPORExcessiveAh m182 : 21|1@1+ (1,0) [0|0] "" Vector__XXX
 SG_ VCBATT1_a183_postPORExcessiveAh m183 : 21|1@1+ (1,0) [0|0] "" Vector__XXX
 SG_ VCBATT1_a191_reverseBatteryEFuseFault m191 : 21|1@1+ (1,0) [0|0] "" Vector__XXX
 SG_ VCBATT1_a216_vcleftFastBlowDebounceImminent m216 : 21|1@1+ (1,0) [0|0] "" Vector__XXX
 SG_ VCBATT1_a229_lvBatteryComms m229 : 21|1@1+ (1,0) [0|0] "" Vector__XXX
 SG_ VCBATT1_a275_bmbCommStatusTypeA m275 : 21|2@1+ (1,0) [0|0] "" Vector__XXX
 SG_ VCBATT1_a276_bmbCommStatusTypeA m276 : 21|2@1+ (1,0) [0|0] "" Vector__XXX
 SG_ VCBATT1_a371_prechargeLVLoadReductionTrigger m371 : 21|1@1+ (1,0) [0|0] "" Vector__XXX
 SG_ VCBATT1_a422_readyToSleepFailed m422 : 21|1@1+ (1,0) [0|0] "" Vector__XXX
 SG_ VCBATT1_a462_ModuleOTLevel1 m462 : 21|1@1+ (1,0) [0|0] "" Vector__XXX
 SG_ VCBATT1_a475_autoOn m475 : 21|1@1+ (1,0) [0|0] "" Vector__XXX
 SG_ VCBATT1_a476_FRM6_timedOut m476 : 21|1@1+ (1,0) [0|0] "" Vector__XXX
 SG_ VCBATT1_a478_vehiclePowerState m478 : 21|2@1+ (1,0) [0|0] "" Vector__XXX
 SG_ VCBATT1_a479_transportMode m479 : 21|1@1+ (1,0) [0|0] "" Vector__XXX
 SG_ VCBATT1_a486_remoteBridgeOutputOn m486 : 21|1@1+ (1,0) [0|0] "" Vector__XXX
 SG_ VCBATT1_a491_fsMode m491 : 21|2@1+ (1,0) [0|0] "" Vector__XXX
 SG_ VCBATT1_a495_DCDCOff m495 : 21|1@1+ (1,0) [0|0] "" Vector__XXX
 SG_ VCBATT1_a496_frunkOpen m496 : 21|1@1+ (1,0) [0|0] "" Vector__XXX
 SG_ VCBATT1_a548_DI_gear m548 : 21|3@1+ (1,0) [0|0] "" Vector__XXX
 SG_ VCBATT1_a561_packTemperature m561 : 21|5@1+ (4,0) [0|0] "" Vector__XXX
 SG_ VCBATT1_a562_packTemperature m562 : 21|5@1+ (4,0) [0|0] "" Vector__XXX
 SG_ VCBATT1_a587_vehiclePowerState m587 : 21|2@1+ (1,0) [0|0] "" Vector__XXX
 SG_ VCBATT1_a021_Task100msLate m21 : 22|1@1+ (1,0) [0|0] "" Vector__XXX
 SG_ VCBATT1_a038_privilegedWrite m38 : 22|1@1+ (1,0) [0|0] "" Vector__XXX
 SG_ VCBATT1_a078_BATTIPC_12VBatteryStatus m78 : 22|1@1+ (1,0) [0|0] "" Vector__XXX
 SG_ VCBATT1_a079_BATTIPC_systemStatus m79 : 22|1@1+ (1,0) [0|0] "" Vector__XXX
 SG_ VCBATT1_a104_BATTIPC_bodyControls m104 : 22|1@1+ (1,0) [0|0] "" Vector__XXX
 SG_ VCBATT1_a106_CH_alertMatrix m106 : 22|1@1+ (1,0) [0|0] "" Vector__XXX
 SG_ VCBATT1_a107_FRONTIPC_chargeInfo m107 : 22|1@1+ (1,0) [0|0] "" Vector__XXX
 SG_ VCBATT1_a110_FRONTIPC_carConfig m110 : 22|1@1+ (1,0) [0|0] "" Vector__XXX
 SG_ VCBATT1_a113_BATTIPC_vehicleControl2 m113 : 22|1@1+ (1,0) [0|0] "" Vector__XXX
 SG_ VCBATT1_a115_FRONTIPC_ChildSeatStatus m115 : 22|1@1+ (1,0) [0|0] "" Vector__XXX
 SG_ VCBATT1_a116_FRONTIPC_hvacStatus m116 : 22|1@1+ (1,0) [0|0] "" Vector__XXX
 SG_ VCBATT1_a117_FRONTIPC_energyStatus m117 : 22|1@1+ (1,0) [0|0] "" Vector__XXX
 SG_ VCBATT1_a118_BATTIPC_coolant m118 : 22|1@1+ (1,0) [0|0] "" Vector__XXX
 SG_ VCBATT1_a120_FRONTIPC_odometerStatus m120 : 22|1@1+ (1,0) [0|0] "" Vector__XXX
 SG_ VCBATT1_a182_resistanceEstimationHardFailure m182 : 22|1@1+ (1,0) [0|0] "" Vector__XXX
 SG_ VCBATT1_a183_resistanceEstimationHardFailure m183 : 22|1@1+ (1,0) [0|0] "" Vector__XXX
 SG_ VCBATT1_a191_vehicleLoadShedActive m191 : 22|1@1+ (1,0) [0|0] "" Vector__XXX
 SG_ VCBATT1_a216_vcleftStaticImminent m216 : 22|1@1+ (1,0) [0|0] "" Vector__XXX
 SG_ VCBATT1_a217_battDomainOvervoltageResult m217 : 22|2@1+ (1,0) [0|0] "" Vector__XXX
 SG_ VCBATT1_a235_timedOut m235 : 22|1@1+ (1,0) [0|0] "" Vector__XXX
 SG_ VCBATT1_a371_instantPrechargeDCRTooHighTrigger m371 : 22|1@1+ (1,0) [0|0] "" Vector__XXX
 SG_ VCBATT1_a414_loadUnattemptedOnFailure m414 : 22|1@1+ (1,0) [0|0] "" Vector__XXX
 SG_ VCBATT1_a422_requestSleepFailed m422 : 22|1@1+ (1,0) [0|0] "" Vector__XXX
 SG_ VCBATT1_a462_PackOVLevel1 m462 : 22|1@1+ (1,0) [0|0] "" Vector__XXX
 SG_ VCBATT1_a475_diagnosticBit m475 : 22|1@1+ (1,0) [0|0] "" Vector__XXX
 SG_ VCBATT1_a476_FRM7_timedOut m476 : 22|1@1+ (1,0) [0|0] "" Vector__XXX
 SG_ VCBATT1_a486_remoteBridgeOutputOnValid m486 : 22|1@1+ (1,0) [0|0] "" Vector__XXX
 SG_ VCBATT1_a495_HVOff m495 : 22|1@1+ (1,0) [0|0] "" Vector__XXX
 SG_ VCBATT1_a496_PCS_MIA m496 : 22|1@1+ (1,0) [0|0] "" Vector__XXX
 SG_ VCBATT1_a545_serviceMode m545 : 22|1@1+ (1,0) [0|0] "" Vector__XXX
 SG_ VCBATT1_a021_Task100msStarved m21 : 23|1@1+ (1,0) [0|0] "" Vector__XXX
 SG_ VCBATT1_a038_privilegedExecute m38 : 23|1@1+ (1,0) [0|0] "" Vector__XXX
 SG_ VCBATT1_a078_BATTIPC_pcsInterface m78 : 23|1@1+ (1,0) [0|0] "" Vector__XXX
 SG_ VCBATT1_a079_FRONTIPC_systemStatus m79 : 23|1@1+ (1,0) [0|0] "" Vector__XXX
 SG_ VCBATT1_a104_FRONTIPC_matrixHighBeamRequest m104 : 23|1@1+ (1,0) [0|0] "" Vector__XXX
 SG_ VCBATT1_a106_FRONTIPC_thermalControl m106 : 23|1@1+ (1,0) [0|0] "" Vector__XXX
 SG_ VCBATT1_a107_FRONTIPC_energyStatus m107 : 23|1@1+ (1,0) [0|0] "" Vector__XXX
 SG_ VCBATT1_a110_FRONTIPC_carState m110 : 23|1@1+ (1,0) [0|0] "" Vector__XXX
 SG_ VCBATT1_a113_BATTIPC_vehicleControl3 m113 : 23|1@1+ (1,0) [0|0] "" Vector__XXX
 SG_ VCBATT1_a115_FRONTIPC_TPMSData m115 : 23|1@1+ (1,0) [0|0] "" Vector__XXX
 SG_ VCBATT1_a116_FRONTIPC_restraintStatus m116 : 23|1@1+ (1,0) [0|0] "" Vector__XXX
 SG_ VCBATT1_a117_FRONTIPC_packConfig m117 : 23|1@1+ (1,0) [0|0] "" Vector__XXX
 SG_ VCBATT1_a118_BATTIPC_lighting m118 : 23|1@1+ (1,0) [0|0] "" Vector__XXX
 SG_ VCBATT1_a182_dcrMilliOhmsAboveThreshold m182 : 23|1@1+ (1,0) [0|0] "" Vector__XXX
 SG_ VCBATT1_a183_dcrMilliOhmsAboveThreshold m183 : 23|1@1+ (1,0) [0|0] "" Vector__XXX
 SG_ VCBATT1_a191_vehicleLoadShedHvFaultActive m191 : 23|1@1+ (1,0) [0|0] "" Vector__XXX
 SG_ VCBATT1_a216_vcleftDynamicImminent m216 : 23|1@1+ (1,0) [0|0] "" Vector__XXX
 SG_ VCBATT1_a414_deviceStuckOnFailure m414 : 23|1@1+ (1,0) [0|0] "" Vector__XXX
 SG_ VCBATT1_a462_PackOVLevel2 m462 : 23|1@1+ (1,0) [0|0] "" Vector__XXX
 SG_ VCBATT1_a475_deviceError m475 : 23|1@1+ (1,0) [0|0] "" Vector__XXX
 SG_ VCBATT1_a476_FRM8_timedOut m476 : 23|1@1+ (1,0) [0|0] "" Vector__XXX
 SG_ VCBATT1_a486_remoteBridgeSyncArmed m486 : 23|1@1+ (1,0) [0|0] "" Vector__XXX
 SG_ VCBATT1_a491_dinCtrlOpt m491 : 23|1@1+ (1,0) [0|0] "" Vector__XXX
 SG_ VCBATT1_a495_externalInteraction m495 : 23|1@1+ (1,0) [0|0] "" Vector__XXX
 SG_ VCBATT1_a496_NotEnoughPowerForSupport m496 : 23|1@1+ (1,0) [0|0] "" Vector__XXX
 SG_ VCBATT1_a514_cell2Voltage m514 : 23|7@1+ (0.08,0) [0|0] "" Vector__XXX
 SG_ VCBATT1_a515_cell2Voltage m515 : 23|7@1+ (0.08,0) [0|0] "" Vector__XXX
 SG_ VCBATT1_a545_factoryGated m545 : 23|1@1+ (1,0) [0|0] "" Vector__XXX
 SG_ VCBATT1_a006_mailboxID m6 : 24|8@1+ (1,0) [0|0] "" Vector__XXX
 SG_ VCBATT1_a018_faultAddress m18 : 24|32@1+ (1,0) [0|0] "" Vector__XXX
 SG_ VCBATT1_a019_faultAddress m19 : 24|32@1+ (1,0) [0|0] "" Vector__XXX
 SG_ VCBATT1_a021_Task100msMissed m21 : 24|1@1+ (1,0) [0|0] "" Vector__XXX
 SG_ VCBATT1_a022_TaskInitError0 m22 : 24|8@1+ (1,0) [0|0] "" Vector__XXX
 SG_ VCBATT1_a031_uds_bytes_1 m31 : 24|8@1+ (1,0) [0|0] "" Vector__XXX
 SG_ VCBATT1_a036_intIdx m36 : 24|10@1+ (1,0) [0|0] "" Vector__XXX
 SG_ VCBATT1_a037_faultAddress m37 : 24|32@1+ (1,0) [0|0] "" Vector__XXX
 SG_ VCBATT1_a038_nonSecure m38 : 24|1@1+ (1,0) [0|0] "" Vector__XXX
 SG_ VCBATT1_a039_faultAddress m39 : 24|32@1+ (1,0) [0|0] "" Vector__XXX
 SG_ VCBATT1_a040_programCounter m40 : 24|32@1+ (1,0) [0|0] "" Vector__XXX
 SG_ VCBATT1_a041_CPULoad1msTask m41 : 24|8@1+ (1,0) [0|0] "" Vector__XXX
 SG_ VCBATT1_a042_Usage10msTask m42 : 24|8@1+ (1,0) [0|0] "" Vector__XXX
 SG_ VCBATT1_a063_switchType m63 : 24|8@1+ (1,0) [0|0] "" Vector__XXX
 SG_ VCBATT1_a078_BATTIPC_LVSelfTests m78 : 24|1@1+ (1,0) [0|0] "" Vector__XXX
 SG_ VCBATT1_a104_FRONTIPC_matrixBendAngleRequest m104 : 24|1@1+ (1,0) [0|0] "" Vector__XXX
 SG_ VCBATT1_a106_FRONTIPC_dcdcRailStatus m106 : 24|1@1+ (1,0) [0|0] "" Vector__XXX
 SG_ VCBATT1_a107_FRONTIPC_packConfig m107 : 24|1@1+ (1,0) [0|0] "" Vector__XXX
 SG_ VCBATT1_a110_FRONTIPC_updateStatus m110 : 24|1@1+ (1,0) [0|0] "" Vector__XXX
 SG_ VCBATT1_a113_BATTIPC_vehicleModes m113 : 24|1@1+ (1,0) [0|0] "" Vector__XXX
 SG_ VCBATT1_a116_FRONTIPC_switchStatus m116 : 24|1@1+ (1,0) [0|0] "" Vector__XXX
 SG_ VCBATT1_a117_FRONTIPC_powerAvailable m117 : 24|1@1+ (1,0) [0|0] "" Vector__XXX
 SG_ VCBATT1_a118_BATTIPC_sensors m118 : 24|1@1+ (1,0) [0|0] "" Vector__XXX
 SG_ VCBATT1_a180_bmsState m180 : 24|4@1+ (1,0) [0|0] "" Vector__XXX
 SG_ VCBATT1_a182_prechargeLVLoadReduction m182 : 24|1@1+ (1,0) [0|0] "" Vector__XXX
 SG_ VCBATT1_a183_prechargeLVLoadReduction m183 : 24|1@1+ (1,0) [0|0] "" Vector__XXX
 SG_ VCBATT1_a188_IBSCurrent m188 : 24|10@1- (0.08,0) [0|0] "" Vector__XXX
 SG_ VCBATT1_a191_vehicleLoadShedPostCrashActive m191 : 24|1@1+ (1,0) [0|0] "" Vector__XXX
 SG_ VCBATT1_a196_batterySMState m196 : 24|4@1+ (1,0) [0|0] "" Vector__XXX
 SG_ VCBATT1_a217_battDomainUndervoltageResult m217 : 24|2@1+ (1,0) [0|0] "" Vector__XXX
 SG_ VCBATT1_a226_channelSelfTestState m226 : 24|3@1+ (1,0) [0|0] "" Vector__XXX
 SG_ VCBATT1_a227_channelSelfTestState m227 : 24|3@1+ (1,0) [0|0] "" Vector__XXX
 SG_ VCBATT1_a228_channelSelfTestState m228 : 24|3@1+ (1,0) [0|0] "" Vector__XXX
 SG_ VCBATT1_a230_channelSelfTestState m230 : 24|3@1+ (1,0) [0|0] "" Vector__XXX
 SG_ VCBATT1_a275_breakLocationB m275 : 24|5@1+ (1,0) [0|0] "" Vector__XXX
 SG_ VCBATT1_a276_breakLocationB m276 : 24|5@1+ (1,0) [0|0] "" Vector__XXX
 SG_ VCBATT1_a297_bmbDeviceFaultTempMask m297 : 24|8@1+ (1,0) [0|0] "" Vector__XXX
 SG_ VCBATT1_a372_bmbDeviceFaultBrickMask m372 : 24|16@1+ (1,0) [0|0] "" Vector__XXX
 SG_ VCBATT1_a392_bmbDeviceFaultBrickMask m392 : 24|16@1+ (1,0) [0|0] "" Vector__XXX
 SG_ VCBATT1_a401_IBSCurrent m401 : 24|12@1- (0.1,0) [0|0] "" Vector__XXX
 SG_ VCBATT1_a402_batterySMState m402 : 24|4@1+ (1,0) [0|0] "" Vector__XXX
 SG_ VCBATT1_a405_intervalVoltage1 m405 : 24|8@1+ (0.02,9) [0|0] "" Vector__XXX
 SG_ VCBATT1_a406_pulseVoltage2 m406 : 24|8@1+ (0.02,9) [0|0] "" Vector__XXX
 SG_ VCBATT1_a407_dcr12VThreshold m407 : 24|4@1+ (1,0) [0|0] "" Vector__XXX
 SG_ VCBATT1_a410_IBSCurrent m410 : 24|12@1- (0.1,0) [0|0] "" Vector__XXX
 SG_ VCBATT1_a411_IBSCurrent m411 : 24|12@1- (0.1,0) [0|0] "" Vector__XXX
 SG_ VCBATT1_a412_pulseVoltage1Shifted m412 : 24|8@1+ (0.02,9) [0|0] "" Vector__XXX
 SG_ VCBATT1_a414_followerVCLeftSelfTestFailure m414 : 24|1@1+ (1,0) [0|0] "" Vector__XXX
 SG_ VCBATT1_a420_retryDurationMs m420 : 24|16@1+ (1,0) [0|0] "" Vector__XXX
 SG_ VCBATT1_a422_requestSleepFailedBitmask m422 : 24|16@1+ (1,0) [0|0] "" Vector__XXX
 SG_ VCBATT1_a428_minBrickCac m428 : 24|13@1+ (0.1,0) [0|0] "" Vector__XXX
 SG_ VCBATT1_a462_DischrgOCLevel1 m462 : 24|1@1+ (1,0) [0|0] "" Vector__XXX
 SG_ VCBATT1_a475_unexpectedLock m475 : 24|1@1+ (1,0) [0|0] "" Vector__XXX
 SG_ VCBATT1_a476_FRM9_timedOut m476 : 24|1@1+ (1,0) [0|0] "" Vector__XXX
 SG_ VCBATT1_a478_batterySMState m478 : 24|4@1+ (1,0) [0|0] "" Vector__XXX
 SG_ VCBATT1_a479_frunkLatchStatus m479 : 24|4@1+ (1,0) [0|0] "" Vector__XXX
 SG_ VCBATT1_a481_bridgeState1 m481 : 24|4@1+ (1,0) [0|0] "" Vector__XXX
 SG_ VCBATT1_a484_vbusVoltage m484 : 24|6@1+ (1,0) [0|0] "" Vector__XXX
 SG_ VCBATT1_a486_remoteBridgeSyncArmedValid m486 : 24|1@1+ (1,0) [0|0] "" Vector__XXX
 SG_ VCBATT1_a489_VDSDiff m489 : 24|8@1+ (1,0) [0|0] "" Vector__XXX
 SG_ VCBATT1_a490_VDSDiff m490 : 24|8@1+ (1,0) [0|0] "" Vector__XXX
 SG_ VCBATT1_a491_dinCtrlEn m491 : 24|1@1+ (1,0) [0|0] "" Vector__XXX
 SG_ VCBATT1_a492_minBrickSoc m492 : 24|8@1+ (0.5,0) [0|0] "" Vector__XXX
 SG_ VCBATT1_a493_minBrickSocByOcvMax m493 : 24|8@1+ (0.5,0) [0|0] "" Vector__XXX
 SG_ VCBATT1_a495_serviceMode m495 : 24|1@1+ (1,0) [0|0] "" Vector__XXX
 SG_ VCBATT1_a496_bmsState m496 : 24|4@1+ (1,0) [0|0] "" Vector__XXX
 SG_ VCBATT1_a497_SOC m497 : 24|7@1+ (1,0) [0|0] "" Vector__XXX
 SG_ VCBATT1_a498_brickImpedanceNormalized m498 : 24|7@1+ (0.01,0.5) [0|0] "" Vector__XXX
 SG_ VCBATT1_a502_minBrickVDelta m502 : 24|15@1- (0.0005,0) [0|0] "" Vector__XXX
 SG_ VCBATT1_a509_expectedState m509 : 24|3@1+ (1,0) [0|0] "" Vector__XXX
 SG_ VCBATT1_a510_packVoltage m510 : 24|8@1+ (0.1,0) [0|0] "" Vector__XXX
 SG_ VCBATT1_a512_packVoltageIntervalMax m512 : 24|8@1+ (0.1,0) [0|0] "" Vector__XXX
 SG_ VCBATT1_a518_IBSVoltage m518 : 24|9@1+ (0.05,0) [0|0] "" Vector__XXX
 SG_ VCBATT1_a525_initialLVBatteryType m525 : 24|3@1+ (1,0) [0|0] "" Vector__XXX
 SG_ VCBATT1_a529_rerunDisconnectedBattery m529 : 24|1@1+ (1,0) [0|0] "" Vector__XXX
 SG_ VCBATT1_a545_frunkOpen m545 : 24|1@1+ (1,0) [0|0] "" Vector__XXX
 SG_ VCBATT1_a548_backstopBucketCount m548 : 24|5@1+ (0.035,0) [0|0] "" Vector__XXX
 SG_ VCBATT1_a556_disconnectedBatteryTestCurrent m556 : 24|12@1+ (0.004884004884004884,-10) [0|0] "" Vector__XXX
 SG_ VCBATT1_a559_PackCurrent m559 : 24|12@1+ (0.2,-600) [0|0] "" Vector__XXX
 SG_ VCBATT1_a582_PCSCurrent m582 : 24|8@1+ (0.5,-127) [0|0] "" Vector__XXX
 SG_ VCBATT1_a587_batterySMState m587 : 24|4@1+ (1,0) [0|0] "" Vector__XXX
 SG_ VCBATT1_a588_vcleftATerm m588 : 24|16@1+ (50,0) [0|0] "" Vector__XXX
 SG_ VCBATT1_a592_vcleftCutoffATerm m592 : 24|16@1+ (50,0) [0|0] "" Vector__XXX
 SG_ VCBATT1_a595_batterySMState m595 : 24|4@1+ (1,0) [0|0] "" Vector__XXX
 SG_ VCBATT1_a599_initialLVBatteryType m599 : 24|3@1+ (1,0) [0|0] "" Vector__XXX
 SG_ VCBATT1_a600_batterySMState m600 : 24|4@1+ (1,0) [0|0] "" Vector__XXX
 SG_ VCBATT1_a628_lastNominalTemp m628 : 24|8@1+ (0.5,-20) [0|0] "" Vector__XXX
 SG_ VCBATT1_a021_Task1000msLate m21 : 25|1@1+ (1,0) [0|0] "" Vector__XXX
 SG_ VCBATT1_a038_busMaster m38 : 25|4@1+ (1,0) [0|0] "" Vector__XXX
 SG_ VCBATT1_a078_FRONTIPC_LVBMS_statusLow m78 : 25|1@1+ (1,0) [0|0] "" Vector__XXX
 SG_ VCBATT1_a104_BATTIPC_matrixBendAngleRequest m104 : 25|1@1+ (1,0) [0|0] "" Vector__XXX
 SG_ VCBATT1_a106_FRONTIPC_dcdcStatus m106 : 25|1@1+ (1,0) [0|0] "" Vector__XXX
 SG_ VCBATT1_a107_FRONTIPC_powerAvailable m107 : 25|1@1+ (1,0) [0|0] "" Vector__XXX
 SG_ VCBATT1_a110_FRONTIPC_time m110 : 25|1@1+ (1,0) [0|0] "" Vector__XXX
 SG_ VCBATT1_a113_FRONTIPC_vehicleControl m113 : 25|1@1+ (1,0) [0|0] "" Vector__XXX
 SG_ VCBATT1_a116_FRONTIPC_lightStatus m116 : 25|1@1+ (1,0) [0|0] "" Vector__XXX
 SG_ VCBATT1_a117_FRONTIPC_socStatus m117 : 25|1@1+ (1,0) [0|0] "" Vector__XXX
 SG_ VCBATT1_a118_BATTIPC_status m118 : 25|1@1+ (1,0) [0|0] "" Vector__XXX
 SG_ VCBATT1_a182_factoryMode m182 : 25|1@1+ (1,0) [0|0] "" Vector__XXX
 SG_ VCBATT1_a183_factoryMode m183 : 25|1@1+ (1,0) [0|0] "" Vector__XXX
 SG_ VCBATT1_a191_IBSVoltage m191 : 25|8@1+ (0.08741903380905883,0) [0|0] "" Vector__XXX
 SG_ VCBATT1_a414_bridgeFailedToOpen m414 : 25|1@1+ (1,0) [0|0] "" Vector__XXX
 SG_ VCBATT1_a427_endingSoc m427 : 25|9@1+ (0.2,0) [0|0] "" Vector__XXX
 SG_ VCBATT1_a446_cell2Voltage m446 : 25|9@1+ (0.01,0) [0|0] "" Vector__XXX
 SG_ VCBATT1_a462_HardwareOCLevel2 m462 : 25|1@1+ (1,0) [0|0] "" Vector__XXX
 SG_ VCBATT1_a475_unexpectedFailSafe m475 : 25|1@1+ (1,0) [0|0] "" Vector__XXX
 SG_ VCBATT1_a476_FRM10_timedOut m476 : 25|1@1+ (1,0) [0|0] "" Vector__XXX
 SG_ VCBATT1_a477_cell2Voltage m477 : 25|9@1+ (0.01,0) [0|0] "" Vector__XXX
 SG_ VCBATT1_a486_remoteBridgeDinState m486 : 25|1@1+ (1,0) [0|0] "" Vector__XXX
 SG_ VCBATT1_a491_tNom m491 : 25|8@1+ (1,0) [0|0] "" Vector__XXX
 SG_ VCBATT1_a495_frunkOpen m495 : 25|1@1+ (1,0) [0|0] "" Vector__XXX
 SG_ VCBATT1_a529_disconnectedBatteryRunExpended m529 : 25|1@1+ (1,0) [0|0] "" Vector__XXX
 SG_ VCBATT1_a541_ChargeCurrentLimit m541 : 25|10@1+ (0.05,0) [0|0] "" Vector__XXX
 SG_ VCBATT1_a021_Task1000msStarved m21 : 26|1@1+ (1,0) [0|0] "" Vector__XXX
 SG_ VCBATT1_a078_FRONTIPC_LVBMS_statusHigh m78 : 26|1@1+ (1,0) [0|0] "" Vector__XXX
 SG_ VCBATT1_a104_BATTIPC_matrixHighBeamRequest m104 : 26|1@1+ (1,0) [0|0] "" Vector__XXX
 SG_ VCBATT1_a107_FRONTIPC_socStatus m107 : 26|1@1+ (1,0) [0|0] "" Vector__XXX
 SG_ VCBATT1_a110_BATTIPC_canLogAvailability m110 : 26|1@1+ (1,0) [0|0] "" Vector__XXX
 SG_ VCBATT1_a113_FRONTIPC_chargeRequest m113 : 26|1@1+ (1,0) [0|0] "" Vector__XXX
 SG_ VCBATT1_a116_BATTIPC_hvacStatus m116 : 26|1@1+ (1,0) [0|0] "" Vector__XXX
 SG_ VCBATT1_a117_FRONTIPC_thermalStatus m117 : 26|1@1+ (1,0) [0|0] "" Vector__XXX
 SG_ VCBATT1_a118_FRONTIPC_systemStatus m118 : 26|1@1+ (1,0) [0|0] "" Vector__XXX
 SG_ VCBATT1_a182_serviceMode m182 : 26|1@1+ (1,0) [0|0] "" Vector__XXX
 SG_ VCBATT1_a183_serviceMode m183 : 26|1@1+ (1,0) [0|0] "" Vector__XXX
 SG_ VCBATT1_a204_ARailLocked m204 : 26|1@1+ (1,0) [0|0] "" Vector__XXX
 SG_ VCBATT1_a205_ARailLocked m205 : 26|1@1+ (1,0) [0|0] "" Vector__XXX
 SG_ VCBATT1_a217_battDomainOvercurrentVCLeftResult m217 : 26|2@1+ (1,0) [0|0] "" Vector__XXX
 SG_ VCBATT1_a414_uvLoadshedVsenseDigIn m414 : 26|1@1+ (1,0) [0|0] "" Vector__XXX
 SG_ VCBATT1_a416_brickVoltageMax m416 : 26|10@1+ (0.005,0) [0|0] "" Vector__XXX
 SG_ VCBATT1_a417_brickVoltageMax m417 : 26|10@1+ (0.005,0) [0|0] "" Vector__XXX
 SG_ VCBATT1_a418_brickVoltageMax m418 : 26|10@1+ (0.005,0) [0|0] "" Vector__XXX
 SG_ VCBATT1_a419_brickVoltageMax m419 : 26|10@1+ (0.005,0) [0|0] "" Vector__XXX
 SG_ VCBATT1_a423_brickVoltageMax m423 : 26|10@1+ (0.005,0) [0|0] "" Vector__XXX
 SG_ VCBATT1_a424_brickVoltageMax m424 : 26|10@1+ (0.005,0) [0|0] "" Vector__XXX
 SG_ VCBATT1_a462_ChrgOCLevel1 m462 : 26|1@1+ (1,0) [0|0] "" Vector__XXX
 SG_ VCBATT1_a475_disableOutputFault m475 : 26|1@1+ (1,0) [0|0] "" Vector__XXX
 SG_ VCBATT1_a476_FRM11_timedOut m476 : 26|1@1+ (1,0) [0|0] "" Vector__XXX
 SG_ VCBATT1_a486_remoteBridgeDinStateValid m486 : 26|1@1+ (1,0) [0|0] "" Vector__XXX
 SG_ VCBATT1_a495_externalPowerSupply m495 : 26|1@1+ (1,0) [0|0] "" Vector__XXX
 SG_ VCBATT1_a503_brickVoltageMax m503 : 26|10@1+ (0.005,0) [0|0] "" Vector__XXX
 SG_ VCBATT1_a527_cell2Voltage m527 : 26|10@1+ (0.01,0) [0|0] "" Vector__XXX
 SG_ VCBATT1_a555_cell2Voltage m555 : 26|10@1+ (0.01,0) [0|0] "" Vector__XXX
 SG_ VCBATT1_a561_ambientTemperature m561 : 26|6@1+ (4,0) [0|0] "" Vector__XXX
 SG_ VCBATT1_a562_ambientTemperature m562 : 26|6@1+ (4,0) [0|0] "" Vector__XXX
 SG_ VCBATT1_a670_mosfetFeedbackVoltage m670 : 26|10@1+ (0.05,0) [0|0] "" Vector__XXX
 SG_ VCBATT1_a021_Task1000msMissed m21 : 27|1@1+ (1,0) [0|0] "" Vector__XXX
 SG_ VCBATT1_a078_BATTIPC_LVBMS_statusLow m78 : 27|1@1+ (1,0) [0|0] "" Vector__XXX
 SG_ VCBATT1_a104_BATTIPC_status m104 : 27|1@1+ (1,0) [0|0] "" Vector__XXX
 SG_ VCBATT1_a107_FRONTIPC_vehicleNotifications m107 : 27|1@1+ (1,0) [0|0] "" Vector__XXX
 SG_ VCBATT1_a110_FRONTIPC_canLogAvailability m110 : 27|1@1+ (1,0) [0|0] "" Vector__XXX
 SG_ VCBATT1_a113_FRONTIPC_vehicleModes m113 : 27|1@1+ (1,0) [0|0] "" Vector__XXX
 SG_ VCBATT1_a116_BATTIPC_LVPowerState m116 : 27|1@1+ (1,0) [0|0] "" Vector__XXX
 SG_ VCBATT1_a117_FRONTIPC_thermalStatus2 m117 : 27|1@1+ (1,0) [0|0] "" Vector__XXX
 SG_ VCBATT1_a118_BATTIPC_systemStatus m118 : 27|1@1+ (1,0) [0|0] "" Vector__XXX
 SG_ VCBATT1_a182_transportMode m182 : 27|1@1+ (1,0) [0|0] "" Vector__XXX
 SG_ VCBATT1_a183_transportMode m183 : 27|1@1+ (1,0) [0|0] "" Vector__XXX
 SG_ VCBATT1_a204_uvLoadshedFaultInject m204 : 27|1@1+ (1,0) [0|0] "" Vector__XXX
 SG_ VCBATT1_a205_ovLoadshedFaultInject m205 : 27|1@1+ (1,0) [0|0] "" Vector__XXX
 SG_ VCBATT1_a226_channelTripped m226 : 27|1@1+ (1,0) [0|0] "" Vector__XXX
 SG_ VCBATT1_a227_channelTripped m227 : 27|1@1+ (1,0) [0|0] "" Vector__XXX
 SG_ VCBATT1_a228_channelTripped m228 : 27|1@1+ (1,0) [0|0] "" Vector__XXX
 SG_ VCBATT1_a230_ocLoadshedFaultActive m230 : 27|1@1+ (1,0) [0|0] "" Vector__XXX
 SG_ VCBATT1_a461_socByAhSaturated m461 : 27|10@1+ (0.1,0) [0|0] "" Vector__XXX
 SG_ VCBATT1_a462_ChrgOCLevel2 m462 : 27|1@1+ (1,0) [0|0] "" Vector__XXX
 SG_ VCBATT1_a475_vsUndervoltage m475 : 27|1@1+ (1,0) [0|0] "" Vector__XXX
 SG_ VCBATT1_a476_FRM12_timedOut m476 : 27|1@1+ (1,0) [0|0] "" Vector__XXX
 SG_ VCBATT1_a509_hardwareLockout m509 : 27|1@1+ (1,0) [0|0] "" Vector__XXX
 SG_ VCBATT1_a525_serviceMode m525 : 27|1@1+ (1,0) [0|0] "" Vector__XXX
 SG_ VCBATT1_a599_serviceMode m599 : 27|1@1+ (1,0) [0|0] "" Vector__XXX
 SG_ VCBATT1_a058_current m58 : 28|11@1+ (0.1,0) [0|0] "" Vector__XXX
 SG_ VCBATT1_a059_resistanceEstimate m59 : 28|12@1+ (0.00244,0) [0|0] "" Vector__XXX
 SG_ VCBATT1_a104_FRONTIPC_bodyControls2 m104 : 28|1@1+ (1,0) [0|0] "" Vector__XXX
 SG_ VCBATT1_a107_FRONTIPC_thermalStatus m107 : 28|1@1+ (1,0) [0|0] "" Vector__XXX
 SG_ VCBATT1_a110_FRONTIPC_mismatchFault m110 : 28|1@1+ (1,0) [0|0] "" Vector__XXX
 SG_ VCBATT1_a113_FRONTIPC_driverProfileRecall2 m113 : 28|1@1+ (1,0) [0|0] "" Vector__XXX
 SG_ VCBATT1_a116_BATTIPC_doorStatus m116 : 28|1@1+ (1,0) [0|0] "" Vector__XXX
 SG_ VCBATT1_a117_FRONTIPC_lightStatus m117 : 28|1@1+ (1,0) [0|0] "" Vector__XXX
 SG_ VCBATT1_a118_FRONTIPC_vehicleStatus m118 : 28|1@1+ (1,0) [0|0] "" Vector__XXX
 SG_ VCBATT1_a180_notEnoughPowerForSupport m180 : 28|1@1+ (1,0) [0|0] "" Vector__XXX
 SG_ VCBATT1_a182_frunkOpen m182 : 28|1@1+ (1,0) [0|0] "" Vector__XXX
 SG_ VCBATT1_a183_frunkOpen m183 : 28|1@1+ (1,0) [0|0] "" Vector__XXX
 SG_ VCBATT1_a196_disconnectedBatteryTestCurrent m196 : 28|12@1+ (0.004884004884004884,-10) [0|0] "" Vector__XXX
 SG_ VCBATT1_a217_battDomainUndervoltageVCLeftResult m217 : 28|2@1+ (1,0) [0|0] "" Vector__XXX
 SG_ VCBATT1_a224_hardwareLoadshedFaultActive m224 : 28|1@1+ (1,0) [0|0] "" Vector__XXX
 SG_ VCBATT1_a226_AdcUpdated m226 : 28|1@1+ (1,0) [0|0] "" Vector__XXX
 SG_ VCBATT1_a227_AdcUpdated m227 : 28|1@1+ (1,0) [0|0] "" Vector__XXX
 SG_ VCBATT1_a228_AdcUpdated m228 : 28|1@1+ (1,0) [0|0] "" Vector__XXX
 SG_ VCBATT1_a258_IBSTemp m258 : 28|16@1- (0.01,0) [0|0] "" Vector__XXX
 SG_ VCBATT1_a260_IBSAh m260 : 28|12@1- (0.1,0) [0|0] "" Vector__XXX
 SG_ VCBATT1_a359_IBSAh m359 : 28|12@1- (0.1,0) [0|0] "" Vector__XXX
 SG_ VCBATT1_a370_IBSAh m370 : 28|12@1- (0.1,0) [0|0] "" Vector__XXX
 SG_ VCBATT1_a379_IBSTemp m379 : 28|10@1+ (0.1,-10) [0|0] "" Vector__XXX
 SG_ VCBATT1_a402_failureToPrechargeRisk m402 : 28|1@1+ (1,0) [0|0] "" Vector__XXX
 SG_ VCBATT1_a407_avgIntervalCurrent m407 : 28|5@1+ (1,-31) [0|0] "" Vector__XXX
 SG_ VCBATT1_a462_MOSFETOTLevel1 m462 : 28|1@1+ (1,0) [0|0] "" Vector__XXX
 SG_ VCBATT1_a475_hardShort m475 : 28|1@1+ (1,0) [0|0] "" Vector__XXX
 SG_ VCBATT1_a476_factoryMode m476 : 28|1@1+ (1,0) [0|0] "" Vector__XXX
 SG_ VCBATT1_a478_bmsState m478 : 28|4@1+ (1,0) [0|0] "" Vector__XXX
 SG_ VCBATT1_a479_vehiclePowerState m479 : 28|2@1+ (1,0) [0|0] "" Vector__XXX
 SG_ VCBATT1_a481_managerState1 m481 : 28|4@1+ (1,0) [0|0] "" Vector__XXX
 SG_ VCBATT1_a525_factoryGated m525 : 28|1@1+ (1,0) [0|0] "" Vector__XXX
 SG_ VCBATT1_a587_LVBMS_packCurrent m587 : 28|12@1+ (0.2,-600) [0|0] "" Vector__XXX
 SG_ VCBATT1_a595_LVBMS_packVoltage m595 : 28|10@1+ (0.1,-1) [0|0] "" Vector__XXX
 SG_ VCBATT1_a599_factoryGated m599 : 28|1@1+ (1,0) [0|0] "" Vector__XXX
 SG_ VCBATT1_a600_LVBMS_packCurrent m600 : 28|12@1+ (0.2,-600) [0|0] "" Vector__XXX
 SG_ VCBATT1_a104_BATTIPC_bodyControls2 m104 : 29|1@1+ (1,0) [0|0] "" Vector__XXX
 SG_ VCBATT1_a107_FRONTIPC_thermalStatus2 m107 : 29|1@1+ (1,0) [0|0] "" Vector__XXX
 SG_ VCBATT1_a110_BATTIPC_status m110 : 29|1@1+ (1,0) [0|0] "" Vector__XXX
 SG_ VCBATT1_a113_FRONTIPC_debugECU m113 : 29|1@1+ (1,0) [0|0] "" Vector__XXX
 SG_ VCBATT1_a116_BATTIPC_thsStatus m116 : 29|1@1+ (1,0) [0|0] "" Vector__XXX
 SG_ VCBATT1_a117_FRONTIPC_pitchEstimation m117 : 29|1@1+ (1,0) [0|0] "" Vector__XXX
 SG_ VCBATT1_a118_BATTIPC_vehicleStatus m118 : 29|1@1+ (1,0) [0|0] "" Vector__XXX
 SG_ VCBATT1_a180_pcsEFuseStable m180 : 29|1@1+ (1,0) [0|0] "" Vector__XXX
 SG_ VCBATT1_a182_packOverDischarged m182 : 29|1@1+ (1,0) [0|0] "" Vector__XXX
 SG_ VCBATT1_a183_packOverDischarged m183 : 29|1@1+ (1,0) [0|0] "" Vector__XXX
 SG_ VCBATT1_a224_ocLoadshedFaultActive m224 : 29|1@1+ (1,0) [0|0] "" Vector__XXX
 SG_ VCBATT1_a226_ocLoadshedFaultActive m226 : 29|1@1+ (1,0) [0|0] "" Vector__XXX
 SG_ VCBATT1_a227_ocLoadshedFaultActive m227 : 29|1@1+ (1,0) [0|0] "" Vector__XXX
 SG_ VCBATT1_a228_ocLoadshedFaultActive m228 : 29|1@1+ (1,0) [0|0] "" Vector__XXX
 SG_ VCBATT1_a275_bmbCommStatusTypeB m275 : 29|2@1+ (1,0) [0|0] "" Vector__XXX
 SG_ VCBATT1_a276_bmbCommStatusTypeB m276 : 29|2@1+ (1,0) [0|0] "" Vector__XXX
 SG_ VCBATT1_a402_electricalDisconnectLVBattery m402 : 29|1@1+ (1,0) [0|0] "" Vector__XXX
 SG_ VCBATT1_a462_CPA_State m462 : 29|1@1+ (1,0) [0|0] "" Vector__XXX
 SG_ VCBATT1_a475_prechargeFailure m475 : 29|1@1+ (1,0) [0|0] "" Vector__XXX
 SG_ VCBATT1_a476_serviceMode m476 : 29|1@1+ (1,0) [0|0] "" Vector__XXX
 SG_ VCBATT1_a525_frunkOpen m525 : 29|1@1+ (1,0) [0|0] "" Vector__XXX
 SG_ VCBATT1_a548_hvState m548 : 29|3@1+ (1,0) [0|0] "" Vector__XXX
 SG_ VCBATT1_a581_criticalResistance m581 : 29|10@1+ (0.0005,0) [0|0] "" Vector__XXX
 SG_ VCBATT1_a599_frunkOpen m599 : 29|1@1+ (1,0) [0|0] "" Vector__XXX
 SG_ VCBATT1_a104_BATTIPC_cameraCleaningControl m104 : 30|1@1+ (1,0) [0|0] "" Vector__XXX
 SG_ VCBATT1_a110_BATTIPC_vehNm m110 : 30|1@1+ (1,0) [0|0] "" Vector__XXX
 SG_ VCBATT1_a113_FRONTIPC_gpsTime m113 : 30|1@1+ (1,0) [0|0] "" Vector__XXX
 SG_ VCBATT1_a116_FRONTIPC_windowStatus m116 : 30|1@1+ (1,0) [0|0] "" Vector__XXX
 SG_ VCBATT1_a117_BATTIPC_pitchEstimation m117 : 30|1@1+ (1,0) [0|0] "" Vector__XXX
 SG_ VCBATT1_a118_FRONTIPC_12VBatteryStatus m118 : 30|1@1+ (1,0) [0|0] "" Vector__XXX
 SG_ VCBATT1_a180_vcrightEFuseStable m180 : 30|1@1+ (1,0) [0|0] "" Vector__XXX
 SG_ VCBATT1_a182_cellImbalance m182 : 30|1@1+ (1,0) [0|0] "" Vector__XXX
 SG_ VCBATT1_a183_cellImbalance m183 : 30|1@1+ (1,0) [0|0] "" Vector__XXX
 SG_ VCBATT1_a217_VCBattBridgeEfuseAsicResult m217 : 30|2@1+ (1,0) [0|0] "" Vector__XXX
 SG_ VCBATT1_a224_faultChannelPinActiveSlow m224 : 30|1@1+ (1,0) [0|0] "" Vector__XXX
 SG_ VCBATT1_a226_faultChannelPinActiveSlow m226 : 30|1@1+ (1,0) [0|0] "" Vector__XXX
 SG_ VCBATT1_a227_faultChannelPinActiveSlow m227 : 30|1@1+ (1,0) [0|0] "" Vector__XXX
 SG_ VCBATT1_a228_faultChannelPinActiveSlow m228 : 30|1@1+ (1,0) [0|0] "" Vector__XXX
 SG_ VCBATT1_a402_communicationDisconnectLVBattery m402 : 30|1@1+ (1,0) [0|0] "" Vector__XXX
 SG_ VCBATT1_a429_usableCapacity m429 : 30|10@1+ (0.025,-0.025) [0|0] "" Vector__XXX
 SG_ VCBATT1_a462_NTCTempDiffWarnLevel1 m462 : 30|1@1+ (1,0) [0|0] "" Vector__XXX
 SG_ VCBATT1_a475_vdsMax m475 : 30|1@1+ (1,0) [0|0] "" Vector__XXX
 SG_ VCBATT1_a476_transportMode m476 : 30|1@1+ (1,0) [0|0] "" Vector__XXX
 SG_ VCBATT1_a508_brickImpedanceNormalized m508 : 30|10@1+ (0.002,0.5) [0|0] "" Vector__XXX
 SG_ VCBATT1_a514_cell3Voltage m514 : 30|7@1+ (0.08,0) [0|0] "" Vector__XXX
 SG_ VCBATT1_a515_cell3Voltage m515 : 30|7@1+ (0.08,0) [0|0] "" Vector__XXX
 SG_ VCBATT1_a104_BATTIPC_bodyControls3 m104 : 31|1@1+ (1,0) [0|0] "" Vector__XXX
 SG_ VCBATT1_a113_FRONTIPC_hvacRequest m113 : 31|1@1+ (1,0) [0|0] "" Vector__XXX
 SG_ VCBATT1_a116_BATTIPC_AP_hvacState10Hz m116 : 31|1@1+ (1,0) [0|0] "" Vector__XXX
 SG_ VCBATT1_a117_BATTIPC_switchStatus m117 : 31|1@1+ (1,0) [0|0] "" Vector__XXX
 SG_ VCBATT1_a118_BATTIPC_12VBatteryStatus m118 : 31|1@1+ (1,0) [0|0] "" Vector__XXX
 SG_ VCBATT1_a180_contactorEFuseStable m180 : 31|1@1+ (1,0) [0|0] "" Vector__XXX
 SG_ VCBATT1_a182_instantPrechargeDCRTooHigh m182 : 31|1@1+ (1,0) [0|0] "" Vector__XXX
 SG_ VCBATT1_a183_instantPrechargeDCRTooHigh m183 : 31|1@1+ (1,0) [0|0] "" Vector__XXX
 SG_ VCBATT1_a224_faultChannelPinActiveMedium m224 : 31|1@1+ (1,0) [0|0] "" Vector__XXX
 SG_ VCBATT1_a226_faultChannelPinActiveMedium m226 : 31|1@1+ (1,0) [0|0] "" Vector__XXX
 SG_ VCBATT1_a227_faultChannelPinActiveMedium m227 : 31|1@1+ (1,0) [0|0] "" Vector__XXX
 SG_ VCBATT1_a228_faultChannelPinActiveMedium m228 : 31|1@1+ (1,0) [0|0] "" Vector__XXX
 SG_ VCBATT1_a387_opportunisticTest m387 : 31|1@1+ (1,0) [0|0] "" Vector__XXX
 SG_ VCBATT1_a388_opportunisticTest m388 : 31|1@1+ (1,0) [0|0] "" Vector__XXX
 SG_ VCBATT1_a402_reverseBatteryFault m402 : 31|1@1+ (1,0) [0|0] "" Vector__XXX
 SG_ VCBATT1_a403_IBSAmpHours m403 : 31|14@1- (0.01,0) [0|0] "" Vector__XXX
 SG_ VCBATT1_a462_KBValueLostFault m462 : 31|1@1+ (1,0) [0|0] "" Vector__XXX
 SG_ VCBATT1_a475_bypassSaturation m475 : 31|1@1+ (1,0) [0|0] "" Vector__XXX
 SG_ VCBATT1_a476_frunkOpen m476 : 31|1@1+ (1,0) [0|0] "" Vector__XXX
 SG_ VCBATT1_a498_measuredCurrent m498 : 31|10@1- (0.25,0) [0|0] "" Vector__XXX
 SG_ VCBATT1_a003_LineNumber m3 : 32|16@1+ (1,0) [0|0] "" Vector__XXX
 SG_ VCBATT1_a005_busID1 m5 : 32|4@1+ (1,0) [0|0] "" Vector__XXX
 SG_ VCBATT1_a006_messageID m6 : 32|29@1+ (1,0) [0|0] "" Vector__XXX
 SG_ VCBATT1_a016_NVMMRecordNotFound m16 : 32|1@1+ (1,0) [0|0] "" Vector__XXX
 SG_ VCBATT1_a022_TaskInitError1 m22 : 32|8@1+ (1,0) [0|0] "" Vector__XXX
 SG_ VCBATT1_a031_uds_bytes_2 m31 : 32|8@1+ (1,0) [0|0] "" Vector__XXX
 SG_ VCBATT1_a038_protectionContext m38 : 32|4@1+ (1,0) [0|0] "" Vector__XXX
 SG_ VCBATT1_a041_CPULoad10msTask m41 : 32|8@1+ (1,0) [0|0] "" Vector__XXX
 SG_ VCBATT1_a042_Usage100msTask m42 : 32|8@1+ (1,0) [0|0] "" Vector__XXX
 SG_ VCBATT1_a063_ADCVoltage m63 : 32|8@1+ (0.025,0) [0|0] "" Vector__XXX
 SG_ VCBATT1_a113_FRONTIPC_hvacDebugControl m113 : 32|1@1+ (1,0) [0|0] "" Vector__XXX
 SG_ VCBATT1_a116_FRONTIPC_systemStatus m116 : 32|1@1+ (1,0) [0|0] "" Vector__XXX
 SG_ VCBATT1_a117_BATTIPC_lightStatus m117 : 32|1@1+ (1,0) [0|0] "" Vector__XXX
 SG_ VCBATT1_a118_FRONTIPC_LVPowerState m118 : 32|1@1+ (1,0) [0|0] "" Vector__XXX
 SG_ VCBATT1_a127_vcleftEFuseVoltage m127 : 32|16@1+ (0.1,0) [0|0] "" Vector__XXX
 SG_ VCBATT1_a129_epas1EFuseVoltage m129 : 32|16@1+ (0.1,0) [0|0] "" Vector__XXX
 SG_ VCBATT1_a130_autopilot1EFuseVoltage m130 : 32|16@1+ (0.1,0) [0|0] "" Vector__XXX
 SG_ VCBATT1_a132_iBoosterVoltage m132 : 32|16@1+ (0.1,0) [0|0] "" Vector__XXX
 SG_ VCBATT1_a134_hvContactorsEFuseVoltage m134 : 32|16@1+ (0.1,0) [0|0] "" Vector__XXX
 SG_ VCBATT1_a180_hvcEFuseStable m180 : 32|1@1+ (1,0) [0|0] "" Vector__XXX
 SG_ VCBATT1_a182_ambientTemp m182 : 32|7@1+ (1,-40) [0|0] "" Vector__XXX
 SG_ VCBATT1_a183_ambientTemp m183 : 32|7@1+ (1,-40) [0|0] "" Vector__XXX
 SG_ VCBATT1_a204_batBridgeCurrent m204 : 32|16@1- (0.0625,0) [0|0] "" Vector__XXX
 SG_ VCBATT1_a205_batBridgeCurrent m205 : 32|16@1- (0.0625,0) [0|0] "" Vector__XXX
 SG_ VCBATT1_a213_IBSAh m213 : 32|14@1- (0.01,0) [0|0] "" Vector__XXX
 SG_ VCBATT1_a215_lastCompletedStage m215 : 32|4@1+ (1,0) [0|0] "" Vector__XXX
 SG_ VCBATT1_a217_dualPowerLoadsResult m217 : 32|2@1+ (1,0) [0|0] "" Vector__XXX
 SG_ VCBATT1_a219_IBSAh m219 : 32|14@1- (0.01,0) [0|0] "" Vector__XXX
 SG_ VCBATT1_a220_lvHealthStatus m220 : 32|3@1+ (1,0) [0|0] "" Vector__XXX
 SG_ VCBATT1_a221_PCSCurrent m221 : 32|8@1+ (0.5,-127) [0|0] "" Vector__XXX
 SG_ VCBATT1_a224_faultChannelPinActiveFast m224 : 32|1@1+ (1,0) [0|0] "" Vector__XXX
 SG_ VCBATT1_a226_faultChannelPinActiveFast m226 : 32|1@1+ (1,0) [0|0] "" Vector__XXX
 SG_ VCBATT1_a227_faultChannelPinActiveFast m227 : 32|1@1+ (1,0) [0|0] "" Vector__XXX
 SG_ VCBATT1_a228_faultChannelPinActiveFast m228 : 32|1@1+ (1,0) [0|0] "" Vector__XXX
 SG_ VCBATT1_a236_hvcRightDomainPowerFeedVoltage m236 : 32|12@1+ (0.005443676098,0) [0|0] "" Vector__XXX
 SG_ VCBATT1_a243_IBSCurrent m243 : 32|16@1- (0.005,0) [0|0] "" Vector__XXX
 SG_ VCBATT1_a244_brakeValveECUEFuseVoltage m244 : 32|16@1+ (0.1,0) [0|0] "" Vector__XXX
 SG_ VCBATT1_a245_voltage m245 : 32|16@1+ (0.1,0) [0|0] "" Vector__XXX
 SG_ VCBATT1_a252_IBSAmpHours m252 : 32|14@1- (0.01,0) [0|0] "" Vector__XXX
 SG_ VCBATT1_a259_IBSTemp m259 : 32|16@1- (0.01,0) [0|0] "" Vector__XXX
 SG_ VCBATT1_a275_bmbChainBreakType m275 : 32|3@1+ (1,0) [0|0] "" Vector__XXX
 SG_ VCBATT1_a277_regErrorType m277 : 32|8@1+ (1,0) [0|0] "" Vector__XXX
 SG_ VCBATT1_a363_avgBleedCharge m363 : 32|15@1+ (0.001,0) [0|0] "" Vector__XXX
 SG_ VCBATT1_a376_IBSCurrentSampleAboveThresholdCount m376 : 32|16@1+ (1,0) [0|0] "" Vector__XXX
 SG_ VCBATT1_a387_IBSTemp m387 : 32|16@1- (0.01,0) [0|0] "" Vector__XXX
 SG_ VCBATT1_a388_IBSTemp m388 : 32|16@1- (0.01,0) [0|0] "" Vector__XXX
 SG_ VCBATT1_a400_bmbDeviceId m400 : 32|4@1+ (1,1) [0|0] "" Vector__XXX
 SG_ VCBATT1_a402_MOSOpen m402 : 32|1@1+ (1,0) [0|0] "" Vector__XXX
 SG_ VCBATT1_a404_IBSTemp m404 : 32|16@1- (0.01,0) [0|0] "" Vector__XXX
 SG_ VCBATT1_a405_intervalVoltage2 m405 : 32|8@1+ (0.02,9) [0|0] "" Vector__XXX
 SG_ VCBATT1_a406_pulseCompareV m406 : 32|8@1+ (0.02,9) [0|0] "" Vector__XXX
 SG_ VCBATT1_a408_IBSAmpHours m408 : 32|14@1- (0.01,0) [0|0] "" Vector__XXX
 SG_ VCBATT1_a412_pulseVoltage2Shifted m412 : 32|8@1+ (0.02,9) [0|0] "" Vector__XXX
 SG_ VCBATT1_a413_bmbDeviceId m413 : 32|4@1+ (1,1) [0|0] "" Vector__XXX
 SG_ VCBATT1_a425_maxBusVoltageLimit m425 : 32|16@1+ (0.002,0) [0|0] "" Vector__XXX
 SG_ VCBATT1_a426_minBusVoltageLimit m426 : 32|16@1+ (0.002,0) [0|0] "" Vector__XXX
 SG_ VCBATT1_a430_maxChargeCurrentLimit m430 : 32|16@1- (0.1,0) [0|0] "" Vector__XXX
 SG_ VCBATT1_a431_maxChargeCurrentLimit m431 : 32|16@1- (0.1,0) [0|0] "" Vector__XXX
 SG_ VCBATT1_a432_packCurrent m432 : 32|16@1- (0.1,0) [0|0] "" Vector__XXX
 SG_ VCBATT1_a433_packTypeData m433 : 32|8@1+ (1,0) [0|0] "" Vector__XXX
 SG_ VCBATT1_a434_packTypeData m434 : 32|8@1+ (1,0) [0|0] "" Vector__XXX
 SG_ VCBATT1_a435_maxDischargeCurrentLimit m435 : 32|16@1- (0.1,0) [0|0] "" Vector__XXX
 SG_ VCBATT1_a436_maxDischargeCurrentLimit m436 : 32|16@1- (0.1,0) [0|0] "" Vector__XXX
 SG_ VCBATT1_a438_sensorId m438 : 32|6@1+ (1,1) [0|0] "" Vector__XXX
 SG_ VCBATT1_a439_sensorId m439 : 32|6@1+ (1,1) [0|0] "" Vector__XXX
 SG_ VCBATT1_a441_bmbModuleIdPrev m441 : 32|16@1+ (1,0) [0|0] "" Vector__XXX
 SG_ VCBATT1_a442_maxSocChangeBrickId m442 : 32|7@1+ (1,1) [0|0] "" Vector__XXX
 SG_ VCBATT1_a462_BalanceCircuitFault m462 : 32|1@1+ (1,0) [0|0] "" Vector__XXX
 SG_ VCBATT1_a475_fuseLatch m475 : 32|1@1+ (1,0) [0|0] "" Vector__XXX
 SG_ VCBATT1_a476_vehiclePowerState m476 : 32|2@1+ (1,0) [0|0] "" Vector__XXX
 SG_ VCBATT1_a478_dcdcLVSupportStatus m478 : 32|2@1+ (1,0) [0|0] "" Vector__XXX
 SG_ VCBATT1_a479_batterySMState m479 : 32|4@1+ (1,0) [0|0] "" Vector__XXX
 SG_ VCBATT1_a481_bridgeState2 m481 : 32|4@1+ (1,0) [0|0] "" Vector__XXX
 SG_ VCBATT1_a482_lvBridgeEFuseVoltage m482 : 32|16@1+ (0.1,0) [0|0] "" Vector__XXX
 SG_ VCBATT1_a484_upstreamEFuseRatio m484 : 32|7@1+ (1,0) [0|0] "" Vector__XXX
 SG_ VCBATT1_a489_stuckOnVDS m489 : 32|10@1+ (1,0) [0|0] "" Vector__XXX
 SG_ VCBATT1_a490_VDSFinished m490 : 32|1@1+ (1,0) [0|0] "" Vector__XXX
 SG_ VCBATT1_a492_maxBrickSocId m492 : 32|7@1+ (1,1) [0|0] "" Vector__XXX
 SG_ VCBATT1_a493_maxBrickSocId m493 : 32|7@1+ (1,1) [0|0] "" Vector__XXX
 SG_ VCBATT1_a497_PackCurrent m497 : 32|12@1+ (0.2,-600) [0|0] "" Vector__XXX
 SG_ VCBATT1_a509_unlocksRemaining m509 : 32|8@1+ (1,0) [0|0] "" Vector__XXX
 SG_ VCBATT1_a510_targetPCSVoltage m510 : 32|8@1+ (0.1,0) [0|0] "" Vector__XXX
 SG_ VCBATT1_a512_packTemperature m512 : 32|8@1+ (1,-40) [0|0] "" Vector__XXX
 SG_ VCBATT1_a513_packTemperature m513 : 32|8@1+ (1,-40) [0|0] "" Vector__XXX
 SG_ VCBATT1_a521_vcleftEFuseTemp m521 : 32|8@1+ (0.75,0) [0|0] "" Vector__XXX
 SG_ VCBATT1_a529_LVBatteryTemp m529 : 32|16@1- (0.01,0) [0|0] "" Vector__XXX
 SG_ VCBATT1_a548_BMS_MIA m548 : 32|1@1+ (1,0) [0|0] "" Vector__XXX
 SG_ VCBATT1_a561_cell1Voltage m561 : 32|7@1+ (0.04,0) [0|0] "" Vector__XXX
 SG_ VCBATT1_a562_cell1Voltage m562 : 32|7@1+ (0.04,0) [0|0] "" Vector__XXX
 SG_ VCBATT1_a573_radarVoltage m573 : 32|16@1+ (0.1,0) [0|0] "" Vector__XXX
 SG_ VCBATT1_a575_vbatFusedLoadShedVoltage m575 : 32|16@1+ (0.1,0) [0|0] "" Vector__XXX
 SG_ VCBATT1_a576_mcuLogicVoltage m576 : 32|16@1+ (0.1,0) [0|0] "" Vector__XXX
 SG_ VCBATT1_a582_LVBusVoltage m582 : 32|8@1+ (0.1,0) [0|0] "" Vector__XXX
 SG_ VCBATT1_a589_vcleftTimingThresholdMs m589 : 32|16@1+ (1,0) [0|0] "" Vector__XXX
 SG_ VCBATT1_a593_vcleftCutoffTimingThresholdMs m593 : 32|16@1+ (1,0) [0|0] "" Vector__XXX
 SG_ VCBATT1_a608_bleedFetFailureBrickId m608 : 32|5@1+ (1,1) [0|0] "" Vector__XXX
 SG_ VCBATT1_a628_lastMeasuredTemp m628 : 32|8@1+ (0.5,-20) [0|0] "" Vector__XXX
 SG_ VCBATT1_a016_NVMMCRCMismatch m16 : 33|1@1+ (1,0) [0|0] "" Vector__XXX
 SG_ VCBATT1_a113_FRONTIPC_status m113 : 33|1@1+ (1,0) [0|0] "" Vector__XXX
 SG_ VCBATT1_a116_BATTIPC_systemStatus m116 : 33|1@1+ (1,0) [0|0] "" Vector__XXX
 SG_ VCBATT1_a117_BATTIPC_doorStatus m117 : 33|1@1+ (1,0) [0|0] "" Vector__XXX
 SG_ VCBATT1_a118_BATTIPC_pcsInterface m118 : 33|1@1+ (1,0) [0|0] "" Vector__XXX
 SG_ VCBATT1_a180_replaceLVBattery m180 : 33|1@1+ (1,0) [0|0] "" Vector__XXX
 SG_ VCBATT1_a191_a180_DCDCNotSupportingLVBus m191 : 33|1@1+ (1,0) [0|0] "" Vector__XXX
 SG_ VCBATT1_a224_faultChannelPinActiveIngoing m224 : 33|1@1+ (1,0) [0|0] "" Vector__XXX
 SG_ VCBATT1_a226_tripCurrent m226 : 33|12@1+ (0.1,0) [0|0] "" Vector__XXX
 SG_ VCBATT1_a227_tripCurrent m227 : 33|12@1+ (0.1,0) [0|0] "" Vector__XXX
 SG_ VCBATT1_a228_tripCurrent m228 : 33|12@1+ (0.1,0) [0|0] "" Vector__XXX
 SG_ VCBATT1_a402_serviceMode m402 : 33|1@1+ (1,0) [0|0] "" Vector__XXX
 SG_ VCBATT1_a407_intervalCurrentVariance m407 : 33|6@1+ (0.1,0) [0|0] "" Vector__XXX
 SG_ VCBATT1_a462_MOSOpenFault m462 : 33|1@1+ (1,0) [0|0] "" Vector__XXX
 SG_ VCBATT1_a475_deviceOvertemperature m475 : 33|1@1+ (1,0) [0|0] "" Vector__XXX
 SG_ VCBATT1_a490_VDSFailure m490 : 33|1@1+ (1,0) [0|0] "" Vector__XXX
 SG_ VCBATT1_a491_ovcThr m491 : 33|5@1+ (1,0) [0|0] "" Vector__XXX
 SG_ VCBATT1_a518_targetPCSVoltage m518 : 33|8@1+ (0.1,0) [0|0] "" Vector__XXX
 SG_ VCBATT1_a548_PCS_MIA m548 : 33|1@1+ (1,0) [0|0] "" Vector__XXX
 SG_ VCBATT1_a016_NVMMVersionMismatch m16 : 34|1@1+ (1,0) [0|0] "" Vector__XXX
 SG_ VCBATT1_a113_FRONTIPC_status2 m113 : 34|1@1+ (1,0) [0|0] "" Vector__XXX
 SG_ VCBATT1_a117_BATTIPC_status m117 : 34|1@1+ (1,0) [0|0] "" Vector__XXX
 SG_ VCBATT1_a118_FRONTIPC_LVBMS_statusLow m118 : 34|1@1+ (1,0) [0|0] "" Vector__XXX
 SG_ VCBATT1_a180_BMS_MIA m180 : 34|1@1+ (1,0) [0|0] "" Vector__XXX
 SG_ VCBATT1_a188_LVSupport m188 : 34|1@1+ (1,0) [0|0] "" Vector__XXX
 SG_ VCBATT1_a191_MOSState m191 : 34|2@1+ (1,0) [0|0] "" Vector__XXX
 SG_ VCBATT1_a217_pcsOvShutdownResult m217 : 34|2@1+ (1,0) [0|0] "" Vector__XXX
 SG_ VCBATT1_a224_hardwareLoadshedFaultActiveIngoing m224 : 34|1@1+ (1,0) [0|0] "" Vector__XXX
 SG_ VCBATT1_a253_IBSAmpHours m253 : 34|14@1- (0.01,0) [0|0] "" Vector__XXX
 SG_ VCBATT1_a402_frunkOpen m402 : 34|1@1+ (1,0) [0|0] "" Vector__XXX
 SG_ VCBATT1_a427_deltaAh m427 : 34|9@1+ (0.5,0) [0|0] "" Vector__XXX
 SG_ VCBATT1_a446_cell3Voltage m446 : 34|9@1+ (0.01,0) [0|0] "" Vector__XXX
 SG_ VCBATT1_a462_DeepDischarge m462 : 34|1@1+ (1,0) [0|0] "" Vector__XXX
 SG_ VCBATT1_a475_ntcOvertemperature m475 : 34|1@1+ (1,0) [0|0] "" Vector__XXX
 SG_ VCBATT1_a476_batterySMState m476 : 34|4@1+ (1,0) [0|0] "" Vector__XXX
 SG_ VCBATT1_a477_cell3Voltage m477 : 34|9@1+ (0.01,0) [0|0] "" Vector__XXX
 SG_ VCBATT1_a478_factoryMode m478 : 34|1@1+ (1,0) [0|0] "" Vector__XXX
 SG_ VCBATT1_a490_stuckOnVDS m490 : 34|10@1+ (1,0) [0|0] "" Vector__XXX
 SG_ VCBATT1_a548_ampHourBucketCount m548 : 34|6@1+ (0.01,0) [0|0] "" Vector__XXX
 SG_ VCBATT1_a016_NVMMRecordUpgraded m16 : 35|1@1+ (1,0) [0|0] "" Vector__XXX
 SG_ VCBATT1_a113_FRONTIPC_trackModeSettings m113 : 35|1@1+ (1,0) [0|0] "" Vector__XXX
 SG_ VCBATT1_a117_BATTIPC_LVPowerState m117 : 35|1@1+ (1,0) [0|0] "" Vector__XXX
 SG_ VCBATT1_a118_FRONTIPC_LVBMS_statusHigh m118 : 35|1@1+ (1,0) [0|0] "" Vector__XXX
 SG_ VCBATT1_a180_PCS_MIA m180 : 35|1@1+ (1,0) [0|0] "" Vector__XXX
 SG_ VCBATT1_a188_bridgeEFuseState m188 : 35|3@1+ (1,0) [0|0] "" Vector__XXX
 SG_ VCBATT1_a220_factoryMode m220 : 35|1@1+ (1,0) [0|0] "" Vector__XXX
 SG_ VCBATT1_a462_SamplingError m462 : 35|1@1+ (1,0) [0|0] "" Vector__XXX
 SG_ VCBATT1_a475_vgsLow m475 : 35|1@1+ (1,0) [0|0] "" Vector__XXX
 SG_ VCBATT1_a478_serviceMode m478 : 35|1@1+ (1,0) [0|0] "" Vector__XXX
 SG_ VCBATT1_a541_PeakCurrent m541 : 35|10@1+ (0.05,0) [0|0] "" Vector__XXX
 SG_ VCBATT1_a005_faults1 m5 : 36|12@1+ (1,0) [0|0] "" Vector__XXX
 SG_ VCBATT1_a016_NVMMMemOverflow m16 : 36|1@1+ (1,0) [0|0] "" Vector__XXX
 SG_ VCBATT1_a038_violationType m38 : 36|3@1+ (1,0) [0|0] "" Vector__XXX
 SG_ VCBATT1_a113_FRONTIPC_tripPlanning m113 : 36|1@1+ (1,0) [0|0] "" Vector__XXX
 SG_ VCBATT1_a117_FRONTIPC_lightingSecondary m117 : 36|1@1+ (1,0) [0|0] "" Vector__XXX
 SG_ VCBATT1_a118_BATTIPC_LVBMS_statusLow m118 : 36|1@1+ (1,0) [0|0] "" Vector__XXX
 SG_ VCBATT1_a180_HVBlockingMismatch m180 : 36|1@1+ (1,0) [0|0] "" Vector__XXX
 SG_ VCBATT1_a191_LVBMSVoltage m191 : 36|8@1+ (0.08741903380905883,0) [0|0] "" Vector__XXX
 SG_ VCBATT1_a215_timedOut m215 : 36|1@1+ (1,0) [0|0] "" Vector__XXX
 SG_ VCBATT1_a217_pcsDomainUndervoltageResult m217 : 36|2@1+ (1,0) [0|0] "" Vector__XXX
 SG_ VCBATT1_a220_serviceMode m220 : 36|1@1+ (1,0) [0|0] "" Vector__XXX
 SG_ VCBATT1_a400_VrefStatus m400 : 36|2@1+ (1,0) [0|0] "" Vector__XXX
 SG_ VCBATT1_a401_IBSVoltage m401 : 36|11@1+ (0.01088735219,0) [0|0] "" Vector__XXX
 SG_ VCBATT1_a410_IBSVoltage m410 : 36|11@1+ (0.01088735219,0) [0|0] "" Vector__XXX
 SG_ VCBATT1_a411_IBSVoltage m411 : 36|11@1+ (0.01088735219,0) [0|0] "" Vector__XXX
 SG_ VCBATT1_a413_VrefStatus m413 : 36|2@1+ (1,0) [0|0] "" Vector__XXX
 SG_ VCBATT1_a416_packCurrent m416 : 36|10@1- (5,0) [0|0] "" Vector__XXX
 SG_ VCBATT1_a417_packCurrent m417 : 36|10@1- (5,0) [0|0] "" Vector__XXX
 SG_ VCBATT1_a418_packCurrent m418 : 36|10@1- (5,0) [0|0] "" Vector__XXX
 SG_ VCBATT1_a419_packCurrent m419 : 36|10@1- (5,0) [0|0] "" Vector__XXX
 SG_ VCBATT1_a423_packCurrent m423 : 36|10@1- (5,0) [0|0] "" Vector__XXX
 SG_ VCBATT1_a424_packCurrent m424 : 36|10@1- (5,0) [0|0] "" Vector__XXX
 SG_ VCBATT1_a462_MOSFETStuckClose m462 : 36|1@1+ (1,0) [0|0] "" Vector__XXX
 SG_ VCBATT1_a475_chargePumpLow m475 : 36|1@1+ (1,0) [0|0] "" Vector__XXX
 SG_ VCBATT1_a478_transportMode m478 : 36|1@1+ (1,0) [0|0] "" Vector__XXX
 SG_ VCBATT1_a481_managerState2 m481 : 36|4@1+ (1,0) [0|0] "" Vector__XXX
 SG_ VCBATT1_a503_packCurrent m503 : 36|10@1- (5,0) [0|0] "" Vector__XXX
 SG_ VCBATT1_a527_cell3Voltage m527 : 36|10@1+ (0.01,0) [0|0] "" Vector__XXX
 SG_ VCBATT1_a555_cell3Voltage m555 : 36|10@1+ (0.01,0) [0|0] "" Vector__XXX
 SG_ VCBATT1_a559_vehiclePowerState m559 : 36|2@1+ (1,0) [0|0] "" Vector__XXX
 SG_ VCBATT1_a670_mosfetFeedbackVoltageState m670 : 36|1@1+ (1,0) [0|0] "" Vector__XXX
 SG_ VCBATT1_a016_NVMMWriteFailed m16 : 37|1@1+ (1,0) [0|0] "" Vector__XXX
 SG_ VCBATT1_a113_FRONTIPC_vehicleControlThermal m113 : 37|1@1+ (1,0) [0|0] "" Vector__XXX
 SG_ VCBATT1_a117_BATTIPC_lightingSecondary m117 : 37|1@1+ (1,0) [0|0] "" Vector__XXX
 SG_ VCBATT1_a180_serviceMode m180 : 37|1@1+ (1,0) [0|0] "" Vector__XXX
 SG_ VCBATT1_a215_retriesUsed m215 : 37|2@1+ (1,0) [0|0] "" Vector__XXX
 SG_ VCBATT1_a462_MOSFETStuckOpen m462 : 37|1@1+ (1,0) [0|0] "" Vector__XXX
 SG_ VCBATT1_a475_watchdog m475 : 37|1@1+ (1,0) [0|0] "" Vector__XXX
 SG_ VCBATT1_a478_notEnoughPowerForSupport m478 : 37|1@1+ (1,0) [0|0] "" Vector__XXX
 SG_ VCBATT1_a514_cell4Voltage m514 : 37|7@1+ (0.08,0) [0|0] "" Vector__XXX
 SG_ VCBATT1_a515_cell4Voltage m515 : 37|7@1+ (0.08,0) [0|0] "" Vector__XXX
 SG_ VCBATT1_a670_gpioEfuseEn m670 : 37|1@1+ (1,0) [0|0] "" Vector__XXX
 SG_ VCBATT1_a113_FRONTIPC_tpmsRCPsetting m113 : 38|1@1+ (1,0) [0|0] "" Vector__XXX
 SG_ VCBATT1_a117_FRONTIPC_windowStatus m117 : 38|1@1+ (1,0) [0|0] "" Vector__XXX
 SG_ VCBATT1_a180_transportMode m180 : 38|1@1+ (1,0) [0|0] "" Vector__XXX
 SG_ VCBATT1_a217_pcsDomainUndervoltageVCRightResult m217 : 38|2@1+ (1,0) [0|0] "" Vector__XXX
 SG_ VCBATT1_a379_minUnfilteredVoltageReached m379 : 38|12@1+ (0.005443676098,0) [0|0] "" Vector__XXX
 SG_ VCBATT1_a400_VrefType m400 : 38|2@1+ (1,0) [0|0] "" Vector__XXX
 SG_ VCBATT1_a413_VrefType m413 : 38|2@1+ (1,0) [0|0] "" Vector__XXX
 SG_ VCBATT1_a462_Imbalance m462 : 38|1@1+ (1,0) [0|0] "" Vector__XXX
 SG_ VCBATT1_a475_spiNotDone m475 : 38|1@1+ (1,0) [0|0] "" Vector__XXX
 SG_ VCBATT1_a476_ECPAState m476 : 38|2@1+ (1,0) [0|0] "" Vector__XXX
 SG_ VCBATT1_a478_crashDetected m478 : 38|1@1+ (1,0) [0|0] "" Vector__XXX
 SG_ VCBATT1_a491_hshtThr m491 : 38|4@1+ (1,0) [0|0] "" Vector__XXX
 SG_ VCBATT1_a595_IBSVoltage m595 : 38|10@1+ (0.1,-1) [0|0] "" Vector__XXX
 SG_ VCBATT1_a058_prevREstimate m58 : 39|12@1+ (0.00061,0) [0|0] "" Vector__XXX
 SG_ VCBATT1_a113_FRONTIPC_autopilotControl m113 : 39|1@1+ (1,0) [0|0] "" Vector__XXX
 SG_ VCBATT1_a117_BATTIPC_systemStatus m117 : 39|1@1+ (1,0) [0|0] "" Vector__XXX
 SG_ VCBATT1_a180_frunkOpen m180 : 39|1@1+ (1,0) [0|0] "" Vector__XXX
 SG_ VCBATT1_a182_dischargedAmpHours m182 : 39|8@1+ (60,0) [0|0] "" Vector__XXX
 SG_ VCBATT1_a183_dischargedAmpHours m183 : 39|8@1+ (60,0) [0|0] "" Vector__XXX
 SG_ VCBATT1_a407_avgPulseCurrent m407 : 39|7@1+ (1,-127) [0|0] "" Vector__XXX
 SG_ VCBATT1_a462_serviceMode m462 : 39|1@1+ (1,0) [0|0] "" Vector__XXX
 SG_ VCBATT1_a475_csUndervoltage m475 : 39|1@1+ (1,0) [0|0] "" Vector__XXX
 SG_ VCBATT1_a478_BMS_MIA m478 : 39|1@1+ (1,0) [0|0] "" Vector__XXX
 SG_ VCBATT1_a561_cell2Voltage m561 : 39|7@1+ (0.04,0) [0|0] "" Vector__XXX
 SG_ VCBATT1_a562_cell2Voltage m562 : 39|7@1+ (0.04,0) [0|0] "" Vector__XXX
 SG_ VCBATT1_a022_TaskInitError2 m22 : 40|8@1+ (1,0) [0|0] "" Vector__XXX
 SG_ VCBATT1_a031_uds_bytes_3 m31 : 40|8@1+ (1,0) [0|0] "" Vector__XXX
 SG_ VCBATT1_a038_faultSource m38 : 40|7@1+ (1,0) [0|0] "" Vector__XXX
 SG_ VCBATT1_a041_CPULoad100msTask m41 : 40|8@1+ (1,0) [0|0] "" Vector__XXX
 SG_ VCBATT1_a042_Usage1000msTask m42 : 40|8@1+ (1,0) [0|0] "" Vector__XXX
 SG_ VCBATT1_a043_CallTrace1 m43 : 40|24@1+ (1,0) [0|0] "" Vector__XXX
 SG_ VCBATT1_a044_CallTrace1 m44 : 40|24@1+ (1,0) [0|0] "" Vector__XXX
 SG_ VCBATT1_a045_CallTrace1 m45 : 40|24@1+ (1,0) [0|0] "" Vector__XXX
 SG_ VCBATT1_a046_CallTrace1 m46 : 40|24@1+ (1,0) [0|0] "" Vector__XXX
 SG_ VCBATT1_a059_current m59 : 40|12@1+ (0.05,0) [0|0] "" Vector__XXX
 SG_ VCBATT1_a063_disconnected m63 : 40|1@1+ (1,0) [0|0] "" Vector__XXX
 SG_ VCBATT1_a113_FRONTIPC_vehicleControl3 m113 : 40|1@1+ (1,0) [0|0] "" Vector__XXX
 SG_ VCBATT1_a180_dcdcLVSupportStatus m180 : 40|2@1+ (1,0) [0|0] "" Vector__XXX
 SG_ VCBATT1_a188_bridgeState m188 : 40|4@1+ (1,0) [0|0] "" Vector__XXX
 SG_ VCBATT1_a196_disconnectedBatteryTestVoltage m196 : 40|8@1+ (0.0392156862745098,6) [0|0] "" Vector__XXX
 SG_ VCBATT1_a215_battDomainOvercurrentResult m215 : 40|2@1+ (1,0) [0|0] "" Vector__XXX
 SG_ VCBATT1_a217_pcsDomainOvervoltageResult m217 : 40|2@1+ (1,0) [0|0] "" Vector__XXX
 SG_ VCBATT1_a220_unhealthyReason m220 : 40|5@1+ (1,0) [0|0] "" Vector__XXX
 SG_ VCBATT1_a221_serviceMode m221 : 40|1@1+ (1,0) [0|0] "" Vector__XXX
 SG_ VCBATT1_a260_vehiclePowerState m260 : 40|2@1+ (1,0) [0|0] "" Vector__XXX
 SG_ VCBATT1_a359_vehiclePowerState m359 : 40|2@1+ (1,0) [0|0] "" Vector__XXX
 SG_ VCBATT1_a370_notEnoughPowerForSupport m370 : 40|1@1+ (1,0) [0|0] "" Vector__XXX
 SG_ VCBATT1_a405_intervalCompareV m405 : 40|8@1+ (0.02,9) [0|0] "" Vector__XXX
 SG_ VCBATT1_a406_avgPulseCurrent m406 : 40|7@1+ (1,-127) [0|0] "" Vector__XXX
 SG_ VCBATT1_a412_pulseCompareVShifted m412 : 40|8@1+ (0.02,9) [0|0] "" Vector__XXX
 SG_ VCBATT1_a420_ovResetAttempted m420 : 40|1@1+ (1,0) [0|0] "" Vector__XXX
 SG_ VCBATT1_a428_avgBrickCac m428 : 40|13@1+ (0.1,0) [0|0] "" Vector__XXX
 SG_ VCBATT1_a429_usableEnergy m429 : 40|10@1+ (0.2,-0.2) [0|0] "" Vector__XXX
 SG_ VCBATT1_a433_cellTypeData m433 : 40|8@1+ (1,0) [0|0] "" Vector__XXX
 SG_ VCBATT1_a434_cellTypeData m434 : 40|8@1+ (1,0) [0|0] "" Vector__XXX
 SG_ VCBATT1_a442_numBricksChanged m442 : 40|8@1+ (1,0) [0|0] "" Vector__XXX
 SG_ VCBATT1_a461_maxSocAhErrorBrickId m461 : 40|7@1+ (1,1) [0|0] "" Vector__XXX
 SG_ VCBATT1_a462_frunkOpen m462 : 40|1@1+ (1,0) [0|0] "" Vector__XXX
 SG_ VCBATT1_a475_configIncorrect m475 : 40|1@1+ (1,0) [0|0] "" Vector__XXX
 SG_ VCBATT1_a478_PCS_MIA m478 : 40|1@1+ (1,0) [0|0] "" Vector__XXX
 SG_ VCBATT1_a481_bridgeState3 m481 : 40|4@1+ (1,0) [0|0] "" Vector__XXX
 SG_ VCBATT1_a492_maxBrickSoc m492 : 40|8@1+ (0.5,0) [0|0] "" Vector__XXX
 SG_ VCBATT1_a493_maxBrickSocByOcvMin m493 : 40|8@1+ (0.5,0) [0|0] "" Vector__XXX
 SG_ VCBATT1_a502_worstBrickV m502 : 40|12@1+ (0.002,0) [0|0] "" Vector__XXX
 SG_ VCBATT1_a508_brickImpedanceId m508 : 40|5@1+ (1,1) [0|0] "" Vector__XXX
 SG_ VCBATT1_a510_serviceMode m510 : 40|1@1+ (1,0) [0|0] "" Vector__XXX
 SG_ VCBATT1_a512_sumCellVoltage m512 : 40|8@1+ (0.1,0) [0|0] "" Vector__XXX
 SG_ VCBATT1_a513_packVoltage m513 : 40|8@1+ (0.1,0) [0|0] "" Vector__XXX
 SG_ VCBATT1_a521_ambientTemp m521 : 40|8@1+ (0.5,-40) [0|0] "" Vector__XXX
 SG_ VCBATT1_a548_LVBMSSOC m548 : 40|5@1+ (3,0) [0|0] "" Vector__XXX
 SG_ VCBATT1_a556_disconnectedBatteryTestVoltage m556 : 40|8@1+ (0.0392156862745098,6) [0|0] "" Vector__XXX
 SG_ VCBATT1_a559_batterySMState m559 : 40|4@1+ (1,0) [0|0] "" Vector__XXX
 SG_ VCBATT1_a581_QF m581 : 40|10@1+ (0.0005,0) [0|0] "" Vector__XXX
 SG_ VCBATT1_a582_LVBusVoltageSource m582 : 40|2@1+ (1,0) [0|0] "" Vector__XXX
 SG_ VCBATT1_a587_IBSCurrent m587 : 40|12@1- (0.1,0) [0|0] "" Vector__XXX
 SG_ VCBATT1_a588_vcleftBTerm m588 : 40|8@1- (1,-78) [0|0] "" Vector__XXX
 SG_ VCBATT1_a592_vcleftCutoffBTerm m592 : 40|8@1- (1,-78) [0|0] "" Vector__XXX
 SG_ VCBATT1_a600_IBSCurrent m600 : 40|12@1- (0.1,0) [0|0] "" Vector__XXX
 SG_ VCBATT1_a608_retryCount m608 : 40|4@1+ (1,0) [0|0] "" Vector__XXX
 SG_ VCBATT1_a063_indeterminate m63 : 41|1@1+ (1,0) [0|0] "" Vector__XXX
 SG_ VCBATT1_a113_FRONTIPC_driverAssistMapData m113 : 41|1@1+ (1,0) [0|0] "" Vector__XXX
 SG_ VCBATT1_a221_frunkOpen m221 : 41|1@1+ (1,0) [0|0] "" Vector__XXX
 SG_ VCBATT1_a370_serviceMode m370 : 41|1@1+ (1,0) [0|0] "" Vector__XXX
 SG_ VCBATT1_a420_retriesUsed m420 : 41|4@1+ (1,0) [0|0] "" Vector__XXX
 SG_ VCBATT1_a475_bufferFull m475 : 41|1@1+ (1,0) [0|0] "" Vector__XXX
 SG_ VCBATT1_a478_HVBlockingMismatch m478 : 41|1@1+ (1,0) [0|0] "" Vector__XXX
 SG_ VCBATT1_a498_testAbortReason m498 : 41|3@1+ (1,0) [0|0] "" Vector__XXX
 SG_ VCBATT1_a510_frunkOpen m510 : 41|1@1+ (1,0) [0|0] "" Vector__XXX
 SG_ VCBATT1_a518_outputVoltageAtPCS m518 : 41|8@1+ (0.1,0) [0|0] "" Vector__XXX
 SG_ VCBATT1_a063_stuckActive m63 : 42|1@1+ (1,0) [0|0] "" Vector__XXX
 SG_ VCBATT1_a113_BATTIPC_driverAssistMapData m113 : 42|1@1+ (1,0) [0|0] "" Vector__XXX
 SG_ VCBATT1_a215_battDomainOvervoltageResult m215 : 42|2@1+ (1,0) [0|0] "" Vector__XXX
 SG_ VCBATT1_a217_VCFrontBridgeEfuseAsicResult m217 : 42|2@1+ (1,0) [0|0] "" Vector__XXX
 SG_ VCBATT1_a260_batterySMState m260 : 42|4@1+ (1,0) [0|0] "" Vector__XXX
 SG_ VCBATT1_a359_batterySMState m359 : 42|4@1+ (1,0) [0|0] "" Vector__XXX
 SG_ VCBATT1_a370_sleepCurrent m370 : 42|10@1+ (0.1,0) [0|0] "" Vector__XXX
 SG_ VCBATT1_a475_hitAlertRateLimit m475 : 42|1@1+ (1,0) [0|0] "" Vector__XXX
 SG_ VCBATT1_a478_HV_UP m478 : 42|1@1+ (1,0) [0|0] "" Vector__XXX
 SG_ VCBATT1_a491_vdsThr m491 : 42|5@1+ (1,0) [0|0] "" Vector__XXX
 SG_ VCBATT1_a582_batteryType m582 : 42|3@1+ (1,0) [0|0] "" Vector__XXX
 SG_ VCBATT1_a063_faulted m63 : 43|1@1+ (1,0) [0|0] "" Vector__XXX
 SG_ VCBATT1_a113_FRONTIPC_chassisControl m113 : 43|1@1+ (1,0) [0|0] "" Vector__XXX
 SG_ VCBATT1_a446_cell4Voltage m446 : 43|9@1+ (0.01,0) [0|0] "" Vector__XXX
 SG_ VCBATT1_a475_hwlo m475 : 43|1@1+ (1,0) [0|0] "" Vector__XXX
 SG_ VCBATT1_a477_cell4Voltage m477 : 43|9@1+ (0.01,0) [0|0] "" Vector__XXX
 SG_ VCBATT1_a478_pcsEFuseStable m478 : 43|1@1+ (1,0) [0|0] "" Vector__XXX
 SG_ VCBATT1_a113_BATTIPC_chassisControl m113 : 44|1@1+ (1,0) [0|0] "" Vector__XXX
 SG_ VCBATT1_a188_frontPrivBusAwake m188 : 44|1@1+ (1,0) [0|0] "" Vector__XXX
 SG_ VCBATT1_a191_ECPAState m191 : 44|2@1+ (1,0) [0|0] "" Vector__XXX
 SG_ VCBATT1_a215_battDomainUndervoltageResult m215 : 44|2@1+ (1,0) [0|0] "" Vector__XXX
 SG_ VCBATT1_a236_hvcDualPowerFeedVoltage m236 : 44|12@1+ (0.005443676098,0) [0|0] "" Vector__XXX
 SG_ VCBATT1_a258_maxCurrentReached m258 : 44|16@1- (0.005,0) [0|0] "" Vector__XXX
 SG_ VCBATT1_a475_dinState m475 : 44|1@1+ (1,0) [0|0] "" Vector__XXX
 SG_ VCBATT1_a478_vcrightEFuseStable m478 : 44|1@1+ (1,0) [0|0] "" Vector__XXX
 SG_ VCBATT1_a481_managerState3 m481 : 44|4@1+ (1,0) [0|0] "" Vector__XXX
 SG_ VCBATT1_a490_stuckOnFinished m490 : 44|1@1+ (1,0) [0|0] "" Vector__XXX
 SG_ VCBATT1_a498_targetVoltage m498 : 44|10@1+ (0.05,0) [0|0] "" Vector__XXX
 SG_ VCBATT1_a514_packVoltage m514 : 44|8@1+ (0.1,0) [0|0] "" Vector__XXX
 SG_ VCBATT1_a515_packVoltage m515 : 44|8@1+ (0.1,0) [0|0] "" Vector__XXX
 SG_ VCBATT1_a559_bmsState m559 : 44|4@1+ (1,0) [0|0] "" Vector__XXX
 SG_ VCBATT1_a608_setFromNvm m608 : 44|1@1+ (1,0) [0|0] "" Vector__XXX
 SG_ VCBATT1_a226_tripTimerCount m226 : 45|17@1+ (1,0) [0|0] "" Vector__XXX
 SG_ VCBATT1_a227_tripTimerCount m227 : 45|17@1+ (1,0) [0|0] "" Vector__XXX
 SG_ VCBATT1_a228_tripTimerCount m228 : 45|17@1+ (1,0) [0|0] "" Vector__XXX
 SG_ VCBATT1_a403_IBSTemp m403 : 45|7@1+ (1,-40) [0|0] "" Vector__XXX
 SG_ VCBATT1_a420_retriesRemaining m420 : 45|4@1+ (1,0) [0|0] "" Vector__XXX
 SG_ VCBATT1_a475_enable m475 : 45|1@1+ (1,0) [0|0] "" Vector__XXX
 SG_ VCBATT1_a478_contactorEFuseStable m478 : 45|1@1+ (1,0) [0|0] "" Vector__XXX
 SG_ VCBATT1_a490_stuckOnFailure m490 : 45|1@1+ (1,0) [0|0] "" Vector__XXX
 SG_ VCBATT1_a541_AverageCurrent m541 : 45|10@1+ (0.05,0) [0|0] "" Vector__XXX
 SG_ VCBATT1_a548_serviceMode m548 : 45|1@1+ (1,0) [0|0] "" Vector__XXX
 SG_ VCBATT1_a582_inFactoryMode m582 : 45|1@1+ (1,0) [0|0] "" Vector__XXX
 SG_ VCBATT1_a191_LVBMSCurrentTargetValid m191 : 46|1@1+ (1,0) [0|0] "" Vector__XXX
 SG_ VCBATT1_a215_battDomainOvercurrentVCLeftResult m215 : 46|2@1+ (1,0) [0|0] "" Vector__XXX
 SG_ VCBATT1_a260_HV_UP m260 : 46|1@1+ (1,0) [0|0] "" Vector__XXX
 SG_ VCBATT1_a407_pulseCurrentVarianceShifted m407 : 46|6@1+ (0.25,0) [0|0] "" Vector__XXX
 SG_ VCBATT1_a408_IBSTemp m408 : 46|7@1+ (1,-40) [0|0] "" Vector__XXX
 SG_ VCBATT1_a416_socMin m416 : 46|8@1+ (0.5,0) [0|0] "" Vector__XXX
 SG_ VCBATT1_a417_socMax m417 : 46|8@1+ (0.5,0) [0|0] "" Vector__XXX
 SG_ VCBATT1_a418_socMax m418 : 46|8@1+ (0.5,0) [0|0] "" Vector__XXX
 SG_ VCBATT1_a419_socMin m419 : 46|8@1+ (0.5,0) [0|0] "" Vector__XXX
 SG_ VCBATT1_a423_socMin m423 : 46|8@1+ (0.5,0) [0|0] "" Vector__XXX
 SG_ VCBATT1_a424_socMin m424 : 46|8@1+ (0.5,0) [0|0] "" Vector__XXX
 SG_ VCBATT1_a478_hvcEFuseStable m478 : 46|1@1+ (1,0) [0|0] "" Vector__XXX
 SG_ VCBATT1_a490_hardShortThresholdReached m490 : 46|1@1+ (1,0) [0|0] "" Vector__XXX
 SG_ VCBATT1_a503_socMax m503 : 46|8@1+ (0.5,0) [0|0] "" Vector__XXX
 SG_ VCBATT1_a527_cell4Voltage m527 : 46|10@1+ (0.01,0) [0|0] "" Vector__XXX
 SG_ VCBATT1_a548_frunkOpen m548 : 46|1@1+ (1,0) [0|0] "" Vector__XXX
 SG_ VCBATT1_a555_cell4Voltage m555 : 46|10@1+ (0.01,0) [0|0] "" Vector__XXX
 SG_ VCBATT1_a561_cell3Voltage m561 : 46|7@1+ (0.04,0) [0|0] "" Vector__XXX
 SG_ VCBATT1_a562_cell3Voltage m562 : 46|7@1+ (0.04,0) [0|0] "" Vector__XXX
 SG_ VCBATT1_a582_frunkOpen m582 : 46|1@1+ (1,0) [0|0] "" Vector__XXX
 SG_ VCBATT1_a182_chargedAmpHours m182 : 47|8@1+ (60,0) [0|0] "" Vector__XXX
 SG_ VCBATT1_a183_chargedAmpHours m183 : 47|8@1+ (60,0) [0|0] "" Vector__XXX
 SG_ VCBATT1_a191_LVBMSVoltageTargetValid m191 : 47|1@1+ (1,0) [0|0] "" Vector__XXX
 SG_ VCBATT1_a260_notEnoughPowerForSupport m260 : 47|1@1+ (1,0) [0|0] "" Vector__XXX
 SG_ VCBATT1_a406_pulseCurrentVariance m406 : 47|6@1+ (0.25,0) [0|0] "" Vector__XXX
 SG_ VCBATT1_a478_frunkOpen m478 : 47|1@1+ (1,0) [0|0] "" Vector__XXX
 SG_ VCBATT1_a490_softShortThresholdReached m490 : 47|1@1+ (1,0) [0|0] "" Vector__XXX
 SG_ VCBATT1_a491_ntcThr m491 : 47|4@1+ (1,0) [0|0] "" Vector__XXX
 SG_ VCBATT1_a003_Data m3 : 48|16@1+ (1,0) [0|0] "" Vector__XXX
 SG_ VCBATT1_a022_TaskInitError3 m22 : 48|8@1+ (1,0) [0|0] "" Vector__XXX
 SG_ VCBATT1_a031_uds_bytes_4 m31 : 48|8@1+ (1,0) [0|0] "" Vector__XXX
 SG_ VCBATT1_a041_CPULoad1000msTask m41 : 48|8@1+ (1,0) [0|0] "" Vector__XXX
 SG_ VCBATT1_a042_UsageUDSTask m42 : 48|8@1+ (1,0) [0|0] "" Vector__XXX
 SG_ VCBATT1_a127_vcleftEFuseTemp m127 : 48|11@1+ (0.125,-40) [0|0] "" Vector__XXX
 SG_ VCBATT1_a129_epas1EFuseTemp m129 : 48|11@1+ (0.125,-40) [0|0] "" Vector__XXX
 SG_ VCBATT1_a130_autopilot1EFuseTemp m130 : 48|11@1+ (0.125,-40) [0|0] "" Vector__XXX
 SG_ VCBATT1_a132_iBoosterEFuseTemp m132 : 48|11@1+ (0.125,-40) [0|0] "" Vector__XXX
 SG_ VCBATT1_a180_IBSVoltage m180 : 48|8@1+ (0.08741903380905883,0) [0|0] "" Vector__XXX
 SG_ VCBATT1_a188_vehiclePowerState m188 : 48|5@1+ (1,0) [0|0] "" Vector__XXX
 SG_ VCBATT1_a191_serviceMode m191 : 48|1@1+ (1,0) [0|0] "" Vector__XXX
 SG_ VCBATT1_a196_disconnectedBatteryTestPrevVoltage m196 : 48|8@1+ (0.0392156862745098,6) [0|0] "" Vector__XXX
 SG_ VCBATT1_a213_LVBatteryTemp m213 : 48|16@1- (0.01,0) [0|0] "" Vector__XXX
 SG_ VCBATT1_a215_battDomainUndervoltageVCLeftResult m215 : 48|2@1+ (1,0) [0|0] "" Vector__XXX
 SG_ VCBATT1_a219_IBSCurrent m219 : 48|16@1- (0.005,0) [0|0] "" Vector__XXX
 SG_ VCBATT1_a243_LVBatteryTemp m243 : 48|16@1- (0.01,0) [0|0] "" Vector__XXX
 SG_ VCBATT1_a245_vbatProtVoltage m245 : 48|16@1+ (0.1,0) [0|0] "" Vector__XXX
 SG_ VCBATT1_a252_IBSCurrent m252 : 48|16@1- (0.005,0) [0|0] "" Vector__XXX
 SG_ VCBATT1_a253_LVBatteryTemp m253 : 48|7@1+ (1,-40) [0|0] "" Vector__XXX
 SG_ VCBATT1_a259_maxCurrentReached m259 : 48|16@1- (0.005,0) [0|0] "" Vector__XXX
 SG_ VCBATT1_a260_coolantHasBeenFilled m260 : 48|1@1+ (1,0) [0|0] "" Vector__XXX
 SG_ VCBATT1_a359_hvState m359 : 48|3@1+ (1,0) [0|0] "" Vector__XXX
 SG_ VCBATT1_a363_checkIntervalDays m363 : 48|5@1+ (1,0) [0|0] "" Vector__XXX
 SG_ VCBATT1_a387_maxCurrentReached m387 : 48|16@1- (0.005,0) [0|0] "" Vector__XXX
 SG_ VCBATT1_a388_maxCurrentReached m388 : 48|16@1- (0.005,0) [0|0] "" Vector__XXX
 SG_ VCBATT1_a401_IBSAmpHours m401 : 48|8@1+ (0.01,-2.55) [0|0] "" Vector__XXX
 SG_ VCBATT1_a404_maxCurrentReached m404 : 48|16@1- (0.005,0) [0|0] "" Vector__XXX
 SG_ VCBATT1_a405_avgIntervalCurrent m405 : 48|5@1+ (1,-31) [0|0] "" Vector__XXX
 SG_ VCBATT1_a410_IBSAmpHours m410 : 48|8@1+ (0.01,-2.55) [0|0] "" Vector__XXX
 SG_ VCBATT1_a411_IBSAmpHours m411 : 48|8@1+ (0.01,-2.55) [0|0] "" Vector__XXX
 SG_ VCBATT1_a412_avgPulseCurrentShifted m412 : 48|7@1+ (1,-127) [0|0] "" Vector__XXX
 SG_ VCBATT1_a427_cacChangeBrickId m427 : 48|7@1+ (1,1) [0|0] "" Vector__XXX
 SG_ VCBATT1_a430_hvjbCurrentLimit m430 : 48|16@1- (0.1,0) [0|0] "" Vector__XXX
 SG_ VCBATT1_a431_hvjbCurrentLimit m431 : 48|16@1- (0.1,0) [0|0] "" Vector__XXX
 SG_ VCBATT1_a433_bmbModuleIdValid m433 : 48|1@1+ (1,0) [0|0] "" Vector__XXX
 SG_ VCBATT1_a434_bmbModuleIdValid m434 : 48|1@1+ (1,0) [0|0] "" Vector__XXX
 SG_ VCBATT1_a435_hvjbCurrentLimit m435 : 48|16@1- (0.1,0) [0|0] "" Vector__XXX
 SG_ VCBATT1_a436_hvjbCurrentLimit m436 : 48|16@1- (0.1,0) [0|0] "" Vector__XXX
 SG_ VCBATT1_a442_brickChangeHystRatio m442 : 48|10@1+ (0.001,0) [0|0] "" Vector__XXX
 SG_ VCBATT1_a461_numBricksHighSocAhError m461 : 48|8@1+ (1,0) [0|0] "" Vector__XXX
 SG_ VCBATT1_a481_bridgeState4 m481 : 48|4@1+ (1,0) [0|0] "" Vector__XXX
 SG_ VCBATT1_a482_lvBridgeEFuseTemp m482 : 48|11@1+ (0.125,-40) [0|0] "" Vector__XXX
 SG_ VCBATT1_a489_currentSenseVoltageDiff m489 : 48|8@1+ (1,0) [0|0] "" Vector__XXX
 SG_ VCBATT1_a490_currentSenseVoltageDiff m490 : 48|8@1+ (1,0) [0|0] "" Vector__XXX
 SG_ VCBATT1_a492_avgBrickSoc m492 : 48|8@1+ (0.5,0) [0|0] "" Vector__XXX
 SG_ VCBATT1_a493_maxBrickSoc m493 : 48|7@1+ (1,0) [0|0] "" Vector__XXX
 SG_ VCBATT1_a497_SumCellVoltage m497 : 48|8@1+ (0.1,0) [0|0] "" Vector__XXX
 SG_ VCBATT1_a512_overcurrentDirection m512 : 48|2@1+ (1,0) [0|0] "" Vector__XXX
 SG_ VCBATT1_a513_packSOC m513 : 48|10@1+ (0.1,0) [0|0] "" Vector__XXX
 SG_ VCBATT1_a521_serviceMode m521 : 48|1@1+ (1,0) [0|0] "" Vector__XXX
 SG_ VCBATT1_a529_externalPowerSupply m529 : 48|1@1+ (1,0) [0|0] "" Vector__XXX
 SG_ VCBATT1_a548_PCSTargetVoltage m548 : 48|8@1+ (0.1,0) [0|0] "" Vector__XXX
 SG_ VCBATT1_a556_disconnectedBatteryTestPrevVoltage m556 : 48|8@1+ (0.0392156862745098,6) [0|0] "" Vector__XXX
 SG_ VCBATT1_a559_dcdcLVSupportStatus m559 : 48|2@1+ (1,0) [0|0] "" Vector__XXX
 SG_ VCBATT1_a575_vbatFusedLoadShedTemp m575 : 48|11@1+ (0.125,-40) [0|0] "" Vector__XXX
 SG_ VCBATT1_a588_vcleftCTerm m588 : 48|16@1- (50,0) [0|0] "" Vector__XXX
 SG_ VCBATT1_a589_vcleftMaxCount m589 : 48|5@1+ (1,0) [0|0] "" Vector__XXX
 SG_ VCBATT1_a592_vcleftCutoffCTerm m592 : 48|16@1- (50,0) [0|0] "" Vector__XXX
 SG_ VCBATT1_a593_vcleftCutoffMaxCount m593 : 48|5@1+ (1,0) [0|0] "" Vector__XXX
 SG_ VCBATT1_a191_frunkOpen m191 : 49|1@1+ (1,0) [0|0] "" Vector__XXX
 SG_ VCBATT1_a260_ampHourTrigger m260 : 49|1@1+ (1,0) [0|0] "" Vector__XXX
 SG_ VCBATT1_a420_vehicleSpeed m420 : 49|12@1+ (0.08,-40) [0|0] "" Vector__XXX
 SG_ VCBATT1_a433_useBmbModuleId m433 : 49|1@1+ (1,0) [0|0] "" Vector__XXX
 SG_ VCBATT1_a434_useBmbModuleId m434 : 49|1@1+ (1,0) [0|0] "" Vector__XXX
 SG_ VCBATT1_a518_packSOC m518 : 49|10@1+ (0.1,0) [0|0] "" Vector__XXX
 SG_ VCBATT1_a521_frunkOpen m521 : 49|1@1+ (1,0) [0|0] "" Vector__XXX
 SG_ VCBATT1_a529_LVBusVoltageNotControllable m529 : 49|1@1+ (1,0) [0|0] "" Vector__XXX
 SG_ VCBATT1_a191_vehicleLoadShedStage m191 : 50|2@1+ (1,0) [0|0] "" Vector__XXX
 SG_ VCBATT1_a215_VCBattBridgeEfuseAsicResult m215 : 50|2@1+ (1,0) [0|0] "" Vector__XXX
 SG_ VCBATT1_a260_voltageTrigger m260 : 50|1@1+ (1,0) [0|0] "" Vector__XXX
 SG_ VCBATT1_a379_timeBelowVoltageThreshold m379 : 50|6@1+ (32,0) [0|0] "" Vector__XXX
 SG_ VCBATT1_a429_duration m429 : 50|6@1+ (1,-1) [0|0] "" Vector__XXX
 SG_ VCBATT1_a512_serviceMode m512 : 50|1@1+ (1,0) [0|0] "" Vector__XXX
 SG_ VCBATT1_a559_factoryMode m559 : 50|1@1+ (1,0) [0|0] "" Vector__XXX
 SG_ VCBATT1_a581_calibratedVoltageOffset m581 : 50|9@1- (0.004,0) [0|0] "" Vector__XXX
 SG_ VCBATT1_a058_newREstimate m58 : 51|12@1+ (0.00061,0) [0|0] "" Vector__XXX
 SG_ VCBATT1_a260_crashDetected m260 : 51|1@1+ (1,0) [0|0] "" Vector__XXX
 SG_ VCBATT1_a359_coolantHasBeenFilled m359 : 51|1@1+ (1,0) [0|0] "" Vector__XXX
 SG_ VCBATT1_a491_wdTime m491 : 51|2@1+ (1,0) [0|0] "" Vector__XXX
 SG_ VCBATT1_a512_frunkOpen m512 : 51|1@1+ (1,0) [0|0] "" Vector__XXX
 SG_ VCBATT1_a559_serviceMode m559 : 51|1@1+ (1,0) [0|0] "" Vector__XXX
 SG_ VCBATT1_a191_exitDriveWarningTimerExpired m191 : 52|1@1+ (1,0) [0|0] "" Vector__XXX
 SG_ VCBATT1_a215_dualPowerLoadsResult m215 : 52|2@1+ (1,0) [0|0] "" Vector__XXX
 SG_ VCBATT1_a260_BMS_MIA m260 : 52|1@1+ (1,0) [0|0] "" Vector__XXX
 SG_ VCBATT1_a359_crashDetected m359 : 52|1@1+ (1,0) [0|0] "" Vector__XXX
 SG_ VCBATT1_a370_SOC m370 : 52|3@1+ (2.5,5) [0|0] "" Vector__XXX
 SG_ VCBATT1_a403_chargeTime m403 : 52|10@1+ (1,0) [0|0] "" Vector__XXX
 SG_ VCBATT1_a407_IBSTemperature m407 : 52|8@1+ (0.5,-30) [0|0] "" Vector__XXX
 SG_ VCBATT1_a446_sumCellVoltage m446 : 52|8@1+ (0.1,0) [0|0] "" Vector__XXX
 SG_ VCBATT1_a477_sumCellVoltage m477 : 52|8@1+ (0.1,0) [0|0] "" Vector__XXX
 SG_ VCBATT1_a481_managerState4 m481 : 52|4@1+ (1,0) [0|0] "" Vector__XXX
 SG_ VCBATT1_a502_shortImpedance m502 : 52|10@1+ (1,0) [0|0] "" Vector__XXX
 SG_ VCBATT1_a512_vehiclePowerState m512 : 52|2@1+ (1,0) [0|0] "" Vector__XXX
 SG_ VCBATT1_a514_packSOC m514 : 52|8@1+ (0.4,0) [0|0] "" Vector__XXX
 SG_ VCBATT1_a515_packSOC m515 : 52|8@1+ (0.4,0) [0|0] "" Vector__XXX
 SG_ VCBATT1_a559_transportMode m559 : 52|1@1+ (1,0) [0|0] "" Vector__XXX
 SG_ VCBATT1_a600_version m600 : 52|4@1+ (1,0) [0|0] "" Vector__XXX
 SG_ VCBATT1_a191_LVBMSMIA m191 : 53|1@1+ (1,0) [0|0] "" Vector__XXX
 SG_ VCBATT1_a260_PCS_MIA m260 : 53|1@1+ (1,0) [0|0] "" Vector__XXX
 SG_ VCBATT1_a359_BMS_MIA m359 : 53|1@1+ (1,0) [0|0] "" Vector__XXX
 SG_ VCBATT1_a405_intervalCurrentVariance m405 : 53|6@1+ (0.1,0) [0|0] "" Vector__XXX
 SG_ VCBATT1_a406_IBSTemperature m406 : 53|6@1+ (1,-3) [0|0] "" Vector__XXX
 SG_ VCBATT1_a408_standbyChargeProfileTime m408 : 53|10@1+ (1,0) [0|0] "" Vector__XXX
 SG_ VCBATT1_a428_modCacImbalancePct m428 : 53|10@1+ (0.1,0) [0|0] "" Vector__XXX
 SG_ VCBATT1_a491_uvThr m491 : 53|2@1+ (1,0) [0|0] "" Vector__XXX
 SG_ VCBATT1_a559_notEnoughPowerForSupport m559 : 53|1@1+ (1,0) [0|0] "" Vector__XXX
 SG_ VCBATT1_a561_cell4Voltage m561 : 53|7@1+ (0.04,0) [0|0] "" Vector__XXX
 SG_ VCBATT1_a562_cell4Voltage m562 : 53|7@1+ (0.04,0) [0|0] "" Vector__XXX
 SG_ VCBATT1_a191_PCS_MIA m191 : 54|1@1+ (1,0) [0|0] "" Vector__XXX
 SG_ VCBATT1_a215_pcsOvShutdownResult m215 : 54|2@1+ (1,0) [0|0] "" Vector__XXX
 SG_ VCBATT1_a260_HVBlockingMismatch m260 : 54|1@1+ (1,0) [0|0] "" Vector__XXX
 SG_ VCBATT1_a359_PCS_MIA m359 : 54|1@1+ (1,0) [0|0] "" Vector__XXX
 SG_ VCBATT1_a416_brickId m416 : 54|8@1+ (1,1) [0|0] "" Vector__XXX
 SG_ VCBATT1_a417_brickId m417 : 54|8@1+ (1,1) [0|0] "" Vector__XXX
 SG_ VCBATT1_a418_brickId m418 : 54|8@1+ (1,1) [0|0] "" Vector__XXX
 SG_ VCBATT1_a419_brickId m419 : 54|8@1+ (1,1) [0|0] "" Vector__XXX
 SG_ VCBATT1_a423_brickId m423 : 54|8@1+ (1,1) [0|0] "" Vector__XXX
 SG_ VCBATT1_a424_brickId m424 : 54|8@1+ (1,1) [0|0] "" Vector__XXX
 SG_ VCBATT1_a498_measuredVoltage m498 : 54|10@1+ (0.05,0) [0|0] "" Vector__XXX
 SG_ VCBATT1_a503_brickId m503 : 54|8@1+ (1,1) [0|0] "" Vector__XXX
 SG_ VCBATT1_a559_crashDetected m559 : 54|1@1+ (1,0) [0|0] "" Vector__XXX
 SG_ VCBATT1_a182_calibrationLostFault m182 : 55|1@1+ (1,0) [0|0] "" Vector__XXX
 SG_ VCBATT1_a183_calibrationLostFault m183 : 55|1@1+ (1,0) [0|0] "" Vector__XXX
 SG_ VCBATT1_a191_NotEnoughPowerForSupport m191 : 55|1@1+ (1,0) [0|0] "" Vector__XXX
 SG_ VCBATT1_a253_firstChargeOTA m253 : 55|1@1+ (1,0) [0|0] "" Vector__XXX
 SG_ VCBATT1_a260_serviceMode m260 : 55|1@1+ (1,0) [0|0] "" Vector__XXX
 SG_ VCBATT1_a359_serviceMode m359 : 55|1@1+ (1,0) [0|0] "" Vector__XXX
 SG_ VCBATT1_a491_ccmVoutThr m491 : 55|3@1+ (1,0) [0|0] "" Vector__XXX
 SG_ VCBATT1_a559_BMS_MIA m559 : 55|1@1+ (1,0) [0|0] "" Vector__XXX
 SG_ VCBATT1_a022_TaskInitError4 m22 : 56|8@1+ (1,0) [0|0] "" Vector__XXX
 SG_ VCBATT1_a031_uds_bytes_5 m31 : 56|8@1+ (1,0) [0|0] "" Vector__XXX
 SG_ VCBATT1_a041_CPULoadNVMMTask m41 : 56|8@1+ (1,0) [0|0] "" Vector__XXX
 SG_ VCBATT1_a042_UsageNVMMTask m42 : 56|8@1+ (1,0) [0|0] "" Vector__XXX
 SG_ VCBATT1_a180_targetPCSVoltage m180 : 56|8@1+ (0.1,0) [0|0] "" Vector__XXX
 SG_ VCBATT1_a182_samplingHWError m182 : 56|1@1+ (1,0) [0|0] "" Vector__XXX
 SG_ VCBATT1_a183_samplingHWError m183 : 56|1@1+ (1,0) [0|0] "" Vector__XXX
 SG_ VCBATT1_a188_timeNotSleeping m188 : 56|6@1+ (1,0) [0|0] "" Vector__XXX
 SG_ VCBATT1_a191_bmsState m191 : 56|4@1+ (1,0) [0|0] "" Vector__XXX
 SG_ VCBATT1_a196_ECPAState m196 : 56|2@1+ (1,0) [0|0] "" Vector__XXX
 SG_ VCBATT1_a215_pcsDomainUndervoltageResult m215 : 56|2@1+ (1,0) [0|0] "" Vector__XXX
 SG_ VCBATT1_a253_firstChargePOR m253 : 56|1@1+ (1,0) [0|0] "" Vector__XXX
 SG_ VCBATT1_a260_dcdcLVSupportStatus m260 : 56|2@1+ (1,0) [0|0] "" Vector__XXX
 SG_ VCBATT1_a359_dcdcLVSupportStatus m359 : 56|2@1+ (1,0) [0|0] "" Vector__XXX
 SG_ VCBATT1_a363_minBleedChargeBrickId m363 : 56|5@1+ (1,1) [0|0] "" Vector__XXX
 SG_ VCBATT1_a379_testFailed m379 : 56|1@1+ (1,0) [0|0] "" Vector__XXX
 SG_ VCBATT1_a412_pulseCurrentVarianceShifted m412 : 56|6@1+ (0.25,0) [0|0] "" Vector__XXX
 SG_ VCBATT1_a427_cacUpdateError m427 : 56|8@1+ (0.1,0) [0|0] "" Vector__XXX
 SG_ VCBATT1_a429_testType m429 : 56|1@1+ (1,0) [0|0] "" Vector__XXX
 SG_ VCBATT1_a481_bridgeState5 m481 : 56|4@1+ (1,0) [0|0] "" Vector__XXX
 SG_ VCBATT1_a490_currentSenseFinished m490 : 56|1@1+ (1,0) [0|0] "" Vector__XXX
 SG_ VCBATT1_a493_avgBrickSoc m493 : 56|7@1+ (1,0) [0|0] "" Vector__XXX
 SG_ VCBATT1_a497_frunkOpen m497 : 56|1@1+ (1,0) [0|0] "" Vector__XXX
 SG_ VCBATT1_a527_serviceMode m527 : 56|1@1+ (1,0) [0|0] "" Vector__XXX
 SG_ VCBATT1_a541_SOC m541 : 56|7@1+ (1,0) [0|0] "" Vector__XXX
 SG_ VCBATT1_a548_ampHourBucketFilled m548 : 56|1@1+ (1,0) [0|0] "" Vector__XXX
 SG_ VCBATT1_a559_PCS_MIA m559 : 56|1@1+ (1,0) [0|0] "" Vector__XXX
 SG_ VCBATT1_a182_brickOverDischarged m182 : 57|1@1+ (1,0) [0|0] "" Vector__XXX
 SG_ VCBATT1_a183_brickOverDischarged m183 : 57|1@1+ (1,0) [0|0] "" Vector__XXX
 SG_ VCBATT1_a253_serviceMode m253 : 57|1@1+ (1,0) [0|0] "" Vector__XXX
 SG_ VCBATT1_a379_testCompleted m379 : 57|1@1+ (1,0) [0|0] "" Vector__XXX
 SG_ VCBATT1_a429_totalDuration m429 : 57|6@1+ (1,-1) [0|0] "" Vector__XXX
 SG_ VCBATT1_a490_currentSenseFailure m490 : 57|1@1+ (1,0) [0|0] "" Vector__XXX
 SG_ VCBATT1_a527_frunkOpen m527 : 57|1@1+ (1,0) [0|0] "" Vector__XXX
 SG_ VCBATT1_a548_HVNotConfirmedUpTrigger m548 : 57|1@1+ (1,0) [0|0] "" Vector__XXX
 SG_ VCBATT1_a559_HVBlockingMismatch m559 : 57|1@1+ (1,0) [0|0] "" Vector__XXX
 SG_ VCBATT1_a182_impedanceGrowth m182 : 58|1@1+ (1,0) [0|0] "" Vector__XXX
 SG_ VCBATT1_a183_impedanceGrowth m183 : 58|1@1+ (1,0) [0|0] "" Vector__XXX
 SG_ VCBATT1_a215_pcsDomainUndervoltageVCRightResult m215 : 58|2@1+ (1,0) [0|0] "" Vector__XXX
 SG_ VCBATT1_a253_frunkOpen m253 : 58|1@1+ (1,0) [0|0] "" Vector__XXX
 SG_ VCBATT1_a260_PCSAndVCREFuseStable m260 : 58|1@1+ (1,0) [0|0] "" Vector__XXX
 SG_ VCBATT1_a359_bmsState m359 : 58|4@1+ (1,0) [0|0] "" Vector__XXX
 SG_ VCBATT1_a379_maxCurrentReached m379 : 58|6@1+ (1,-63) [0|0] "" Vector__XXX
 SG_ VCBATT1_a491_csUvRetryT m491 : 58|2@1+ (1,0) [0|0] "" Vector__XXX
 SG_ VCBATT1_a513_serviceMode m513 : 58|1@1+ (1,0) [0|0] "" Vector__XXX
 SG_ VCBATT1_a548_PCSNotMeetingTargetTrigger m548 : 58|1@1+ (1,0) [0|0] "" Vector__XXX
 SG_ VCBATT1_a559_HV_UP m559 : 58|1@1+ (1,0) [0|0] "" Vector__XXX
 SG_ VCBATT1_a127_vcleftEFuseRemainingRetries m127 : 59|4@1+ (1,0) [0|0] "" Vector__XXX
 SG_ VCBATT1_a182_batteryType m182 : 59|3@1+ (1,0) [0|0] "" Vector__XXX
 SG_ VCBATT1_a183_batteryType m183 : 59|3@1+ (1,0) [0|0] "" Vector__XXX
 SG_ VCBATT1_a260_bmsState m260 : 59|4@1+ (1,0) [0|0] "" Vector__XXX
 SG_ VCBATT1_a405_testCounter m405 : 59|2@1+ (1,0) [0|0] "" Vector__XXX
 SG_ VCBATT1_a406_testValid m406 : 59|1@1+ (1,0) [0|0] "" Vector__XXX
 SG_ VCBATT1_a482_lvBridgeEFuseRemainingRetries m482 : 59|4@1+ (1,0) [0|0] "" Vector__XXX
 SG_ VCBATT1_a513_frunkOpen m513 : 59|1@1+ (1,0) [0|0] "" Vector__XXX
 SG_ VCBATT1_a518_serviceMode m518 : 59|1@1+ (1,0) [0|0] "" Vector__XXX
 SG_ VCBATT1_a548_PCSMIATrigger m548 : 59|1@1+ (1,0) [0|0] "" Vector__XXX
 SG_ VCBATT1_a559_pcsEFuseStable m559 : 59|1@1+ (1,0) [0|0] "" Vector__XXX
 SG_ VCBATT1_a575_vbatFusedLoadShedRemainingRetries m575 : 59|5@1+ (1,0) [0|0] "" Vector__XXX
 SG_ VCBATT1_a215_pcsDomainOvervoltageResult m215 : 60|2@1+ (1,0) [0|0] "" Vector__XXX
 SG_ VCBATT1_a258_lowCapacity m258 : 60|1@1+ (1,0) [0|0] "" Vector__XXX
 SG_ VCBATT1_a406_opportunisticTest m406 : 60|1@1+ (1,0) [0|0] "" Vector__XXX
 SG_ VCBATT1_a407_testCounter m407 : 60|2@1+ (1,0) [0|0] "" Vector__XXX
 SG_ VCBATT1_a446_deepDischargeFlag m446 : 60|1@1+ (1,0) [0|0] "" Vector__XXX
 SG_ VCBATT1_a477_deepDischargeFlag m477 : 60|1@1+ (1,0) [0|0] "" Vector__XXX
 SG_ VCBATT1_a481_managerState5 m481 : 60|4@1+ (1,0) [0|0] "" Vector__XXX
 SG_ VCBATT1_a513_vehiclePowerState m513 : 60|2@1+ (1,0) [0|0] "" Vector__XXX
 SG_ VCBATT1_a514_serviceMode m514 : 60|1@1+ (1,0) [0|0] "" Vector__XXX
 SG_ VCBATT1_a515_serviceMode m515 : 60|1@1+ (1,0) [0|0] "" Vector__XXX
 SG_ VCBATT1_a518_frunkOpen m518 : 60|1@1+ (1,0) [0|0] "" Vector__XXX
 SG_ VCBATT1_a548_PCSSaturatedTrigger m548 : 60|1@1+ (1,0) [0|0] "" Vector__XXX
 SG_ VCBATT1_a559_vcrightEFuseStable m559 : 60|1@1+ (1,0) [0|0] "" Vector__XXX
 SG_ VCBATT1_a561_factoryMode m561 : 60|1@1+ (1,0) [0|0] "" Vector__XXX
 SG_ VCBATT1_a562_factoryMode m562 : 60|1@1+ (1,0) [0|0] "" Vector__XXX
 SG_ VCBATT1_a258_completed m258 : 61|1@1+ (1,0) [0|0] "" Vector__XXX
 SG_ VCBATT1_a363_setFromNvm m363 : 61|1@1+ (1,0) [0|0] "" Vector__XXX
 SG_ VCBATT1_a405_overchargeTrigger m405 : 61|1@1+ (1,0) [0|0] "" Vector__XXX
 SG_ VCBATT1_a406_disconnectedBatteryTestTrigger m406 : 61|1@1+ (1,0) [0|0] "" Vector__XXX
 SG_ VCBATT1_a420_DI_gear m420 : 61|3@1+ (1,0) [0|0] "" Vector__XXX
 SG_ VCBATT1_a446_serviceMode m446 : 61|1@1+ (1,0) [0|0] "" Vector__XXX
 SG_ VCBATT1_a477_serviceMode m477 : 61|1@1+ (1,0) [0|0] "" Vector__XXX
 SG_ VCBATT1_a514_frunkOpen m514 : 61|1@1+ (1,0) [0|0] "" Vector__XXX
 SG_ VCBATT1_a515_frunkOpen m515 : 61|1@1+ (1,0) [0|0] "" Vector__XXX
 SG_ VCBATT1_a518_vehiclePowerState m518 : 61|2@1+ (1,0) [0|0] "" Vector__XXX
 SG_ VCBATT1_a548_backstopHit m548 : 61|1@1+ (1,0) [0|0] "" Vector__XXX
 SG_ VCBATT1_a559_contactorEFuseStable m559 : 61|1@1+ (1,0) [0|0] "" Vector__XXX
 SG_ VCBATT1_a561_serviceMode m561 : 61|1@1+ (1,0) [0|0] "" Vector__XXX
 SG_ VCBATT1_a562_serviceMode m562 : 61|1@1+ (1,0) [0|0] "" Vector__XXX
 SG_ VCBATT1_a182_bleedFetTestFailure m182 : 62|1@1+ (1,0) [0|0] "" Vector__XXX
 SG_ VCBATT1_a183_bleedFetTestFailure m183 : 62|1@1+ (1,0) [0|0] "" Vector__XXX
 SG_ VCBATT1_a188_CANAfterQuiet m188 : 62|1@1+ (1,0) [0|0] "" Vector__XXX
 SG_ VCBATT1_a215_VCFrontBridgeEfuseAsicResult m215 : 62|2@1+ (1,0) [0|0] "" Vector__XXX
 SG_ VCBATT1_a403_firstChargeOTA m403 : 62|1@1+ (1,0) [0|0] "" Vector__XXX
 SG_ VCBATT1_a405_voltDropOnHighCurrentTrigger m405 : 62|1@1+ (1,0) [0|0] "" Vector__XXX
 SG_ VCBATT1_a406_maxChargeTimeoutTrigger m406 : 62|1@1+ (1,0) [0|0] "" Vector__XXX
 SG_ VCBATT1_a407_testingExpended m407 : 62|1@1+ (1,0) [0|0] "" Vector__XXX
 SG_ VCBATT1_a412_serviceMode m412 : 62|1@1+ (1,0) [0|0] "" Vector__XXX
 SG_ VCBATT1_a446_frunkOpen m446 : 62|1@1+ (1,0) [0|0] "" Vector__XXX
 SG_ VCBATT1_a477_frunkOpen m477 : 62|1@1+ (1,0) [0|0] "" Vector__XXX
 SG_ VCBATT1_a514_vehiclePowerState m514 : 62|2@1+ (1,0) [0|0] "" Vector__XXX
 SG_ VCBATT1_a515_vehiclePowerState m515 : 62|2@1+ (1,0) [0|0] "" Vector__XXX
 SG_ VCBATT1_a559_hvcEFuseStable m559 : 62|1@1+ (1,0) [0|0] "" Vector__XXX
 SG_ VCBATT1_a561_frunkOpen m561 : 62|1@1+ (1,0) [0|0] "" Vector__XXX
 SG_ VCBATT1_a562_frunkOpen m562 : 62|1@1+ (1,0) [0|0] "" Vector__XXX
 SG_ VCBATT1_a058_faultReason m58 : 63|1@1+ (1,0) [0|0] "" Vector__XXX
 SG_ VCBATT1_a182_weakShort m182 : 63|1@1+ (1,0) [0|0] "" Vector__XXX
 SG_ VCBATT1_a183_weakShort m183 : 63|1@1+ (1,0) [0|0] "" Vector__XXX
 SG_ VCBATT1_a403_IBSTempShortOrOpen m403 : 63|1@1+ (1,0) [0|0] "" Vector__XXX
 SG_ VCBATT1_a405_voltageDipTrigger m405 : 63|1@1+ (1,0) [0|0] "" Vector__XXX
 SG_ VCBATT1_a406_voltageFloorReachedTrigger m406 : 63|1@1+ (1,0) [0|0] "" Vector__XXX
 SG_ VCBATT1_a407_opportunisticTest m407 : 63|1@1+ (1,0) [0|0] "" Vector__XXX
 SG_ VCBATT1_a408_IBSTempShortOrOpen m408 : 63|1@1+ (1,0) [0|0] "" Vector__XXX
 SG_ VCBATT1_a412_frunkOpen m412 : 63|1@1+ (1,0) [0|0] "" Vector__XXX
 SG_ VCBATT1_a559_frunkOpen m559 : 63|1@1+ (1,0) [0|0] "" Vector__XXX

BO_ 1340 TAS_alertCleared: 8 Vector__XXX
 SG_ TAS_alertClearedID : 0|9@1+ (1,0) [0|0] "" Vector__XXX

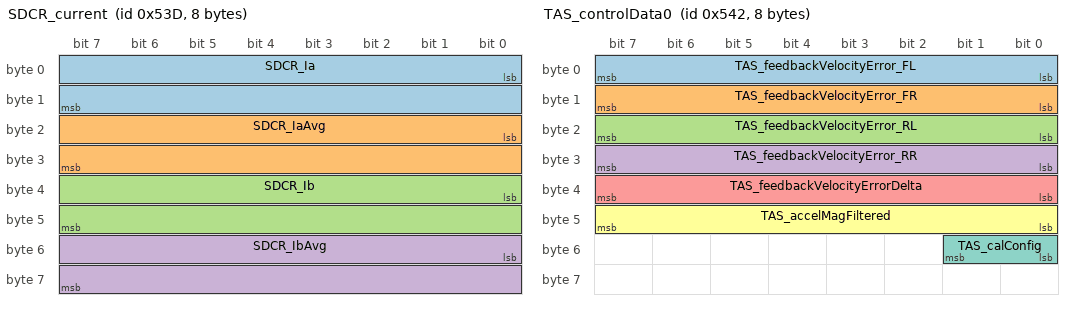
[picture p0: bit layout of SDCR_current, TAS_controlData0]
BO_ 1341 SDCR_current: 8 Vector__XXX
 SG_ SDCR_Ia : 0|16@1- (0.1,0) [0|0] "" Vector__XXX
 SG_ SDCR_IaAvg : 16|16@1- (0.1,0) [0|0] "" Vector__XXX
 SG_ SDCR_Ib : 32|16@1- (0.1,0) [0|0] "" Vector__XXX
 SG_ SDCR_IbAvg : 48|16@1- (0.1,0) [0|0] "" Vector__XXX

BO_ 1342 CP_info: 8 Vector__XXX
 SG_ CP_infoIndex M : 0|8@1+ (1,0) [0|0] "" Vector__XXX
 SG_ CP_appGitHash m17 : 8|56@1+ (1,0) [0|0] "" Vector__XXX
 SG_ CP_bootGitHash m18 : 8|56@1+ (1,0) [0|0] "" Vector__XXX
 SG_ CP_bootUdsProtoVersion m20 : 8|8@1+ (1,0) [0|0] "" Vector__XXX
 SG_ CP_buildType m10 : 8|3@1+ (1,0) [0|0] "" Vector__XXX
 SG_ CP_platformType m13 : 8|8@1+ (1,0) [0|0] "" Vector__XXX
 SG_ CP_buildConfigId m10 : 16|16@1+ (1,0) [0|0] "" Vector__XXX
 SG_ CP_pcbaId m11 : 16|8@1+ (1,0) [0|0] "" Vector__XXX
 SG_ CP_assemblyId m11 : 24|8@1+ (1,0) [0|0] "" Vector__XXX
 SG_ CP_appCrc m13 : 32|32@1+ (1,0) [0|0] "" Vector__XXX
 SG_ CP_bootCrc m20 : 32|32@1+ (1,0) [0|0] "" Vector__XXX
 SG_ CP_hardwareId m10 : 32|16@1+ (1,0) [0|0] "" Vector__XXX
 SG_ CP_usageId m11 : 32|16@1+ (1,0) [0|0] "" Vector__XXX
 SG_ CP_componentId m10 : 48|16@1+ (1,0) [0|0] "" Vector__XXX
 SG_ CP_subUsageId m11 : 48|16@1+ (1,0) [0|0] "" Vector__XXX

BO_ 1343 BMS_alertLog: 8 Vector__XXX
 SG_ BMS_alertID M : 0|9@1+ (1,0) [0|0] "" Vector__XXX
 SG_ BMS_alertSet : 15|1@1+ (1,0) [0|0] "" Vector__XXX
 SG_ BMS_a000_alertDataW0 m0 : 16|16@1+ (1,0) [0|0] "" Vector__XXX
 SG_ BMS_a001_gatewayPackEnergy m1 : 16|2@1+ (1,0) [0|0] "" Vector__XXX
 SG_ BMS_a002_gatewayPackPerformanceDeviation m2 : 16|3@1+ (1,0) [0|0] "" Vector__XXX
 SG_ BMS_a003_calBlockData_0 m3 : 16|32@1+ (1,0) [0|0] "" Vector__XXX
 SG_ BMS_a016_moduleCrcErrorMask m16 : 16|8@1+ (1,0) [0|0] "" Vector__XXX
 SG_ BMS_a017_packCurrent m17 : 16|8@1+ (8,-1500) [0|0] "" Vector__XXX
 SG_ BMS_a018_packCurrent m18 : 16|8@1+ (8,-1496) [0|0] "" Vector__XXX
 SG_ BMS_a019_coolantInletT m19 : 16|8@1+ (0.4,-20) [0|0] "" Vector__XXX
 SG_ BMS_a020_packCurrent m20 : 16|8@1+ (8,-1500) [0|0] "" Vector__XXX
 SG_ BMS_a021_chargeViolation m21 : 16|1@1+ (1,0) [0|0] "" Vector__XXX
 SG_ BMS_a022_chargeAccumulatorViolation m22 : 16|1@1+ (1,0) [0|0] "" Vector__XXX
 SG_ BMS_a023_ovStackDeviceID m23 : 16|5@1+ (1,1) [0|0] "" Vector__XXX
 SG_ BMS_a024_brickID m24 : 16|8@1+ (1,1) [0|0] "" Vector__XXX
 SG_ BMS_a025_diPower m25 : 16|9@1- (4.313725490196078,250.1960784313725) [0|0] "" Vector__XXX
 SG_ BMS_a026_packCurrent m26 : 16|13@1+ (1,0) [0|0] "" Vector__XXX
 SG_ BMS_a027_swIsolationCount m27 : 16|8@1+ (1,0) [0|0] "" Vector__XXX
 SG_ BMS_a028_CurrentOffset m28 : 16|16@1- (0.001,0) [0|0] "" Vector__XXX
 SG_ BMS_a030_worstBrickID m30 : 16|8@1+ (1,1) [0|0] "" Vector__XXX
 SG_ BMS_a032_uvBrickV m32 : 16|12@1+ (0.002,0) [0|0] "" Vector__XXX
 SG_ BMS_a033_uvBrickV m33 : 16|12@1+ (0.002,0) [0|0] "" Vector__XXX
 SG_ BMS_a034_packVoltage m34 : 16|10@1+ (1,0) [0|0] "" Vector__XXX
 SG_ BMS_a035_isoR m35 : 16|9@1+ (10,0) [0|0] "" Vector__XXX
 SG_ BMS_a037_floodPort1State m37 : 16|3@1+ (1,0) [0|0] "" Vector__XXX
 SG_ BMS_a039_dcLinkVoltage m39 : 16|10@1+ (1,0) [0|0] "" Vector__XXX
 SG_ BMS_a041_resetType m41 : 16|4@1+ (1,0) [0|0] "" Vector__XXX
 SG_ BMS_a042_accessAddress m42 : 16|32@1+ (1,0) [0|0] "" Vector__XXX
 SG_ BMS_a043_taskID m43 : 16|3@1+ (1,0) [0|0] "" Vector__XXX
 SG_ BMS_a044_assertFile m44 : 16|3@1+ (1,0) [0|0] "" Vector__XXX
 SG_ BMS_a045_ivorNumber m45 : 16|3@1+ (1,0) [0|0] "" Vector__XXX
 SG_ BMS_a046_taskID m46 : 16|3@1+ (1,0) [0|0] "" Vector__XXX
 SG_ BMS_a047_taskID m47 : 16|3@1+ (1,0) [0|0] "" Vector__XXX
 SG_ BMS_a048_starvedTaskID m48 : 16|3@1+ (1,0) [0|0] "" Vector__XXX
 SG_ BMS_a050_MIA_numBadReadings m50 : 16|8@1+ (1,0) [0|0] "" Vector__XXX
 SG_ BMS_a051_hvp1V5Ref m51 : 16|12@1+ (0.001,0) [0|0] "" Vector__XXX
 SG_ BMS_a054_verSupplyV m54 : 16|16@1+ (0.001,0) [0|0] "" Vector__XXX
 SG_ BMS_a055_vcfrontMia m55 : 16|1@1+ (1,0) [0|0] "" Vector__XXX
 SG_ BMS_a056_standbySupplyOutV m56 : 16|12@1+ (0.01,0) [0|0] "" Vector__XXX
 SG_ BMS_a057_bandoThmModelState m57 : 16|4@1+ (1,0) [0|0] "" Vector__XXX
 SG_ BMS_a058_bandoThmModelState m58 : 16|4@1+ (1,0) [0|0] "" Vector__XXX
 SG_ BMS_a059_sumBrickVoltages m59 : 16|16@1+ (0.01,0) [0|0] "" Vector__XXX
 SG_ BMS_a060_fcLinkDecayTime m60 : 16|10@1+ (2,0) [0|0] "" Vector__XXX
 SG_ BMS_a061_numBrickChanges m61 : 16|8@1+ (1,0) [0|0] "" Vector__XXX
 SG_ BMS_a062_state m62 : 16|4@1+ (1,0) [0|0] "" Vector__XXX
 SG_ BMS_a063_cpFaultInV m63 : 16|12@1+ (0.001,0) [0|0] "" Vector__XXX
 SG_ BMS_a064_minBrickSOCID m64 : 16|7@1+ (1,1) [0|0] "" Vector__XXX
 SG_ BMS_a065_minBrickCacId m65 : 16|7@1+ (1,1) [0|0] "" Vector__XXX
 SG_ BMS_a066_minBrickSocId m66 : 16|7@1+ (1,1) [0|0] "" Vector__XXX
 SG_ BMS_a067_minBrickCacId m67 : 16|7@1+ (1,1) [0|0] "" Vector__XXX
 SG_ BMS_a068_minBrickCacId m68 : 16|7@1+ (1,1) [0|0] "" Vector__XXX
 SG_ BMS_a069_dischargePowerPackVoltageFloor m69 : 16|8@1- (0.025,-3.15) [0|0] "" Vector__XXX
 SG_ BMS_a070_state m70 : 16|4@1+ (1,0) [0|0] "" Vector__XXX
 SG_ BMS_a071_stateRequest m71 : 16|4@1+ (1,0) [0|0] "" Vector__XXX
 SG_ BMS_a072_moduleId m72 : 16|4@1+ (1,1) [0|0] "" Vector__XXX
 SG_ BMS_a073_gtwTimeAtLossOfLv m73 : 16|32@1+ (1,0) [0|0] "" Vector__XXX
 SG_ BMS_a074_maxBrickVTarget m74 : 16|8@1+ (0.01,2) [0|0] "" Vector__XXX
 SG_ BMS_a075_chargeType m75 : 16|1@1+ (1,0) [0|0] "" Vector__XXX
 SG_ BMS_a076_netAh m76 : 16|21@1- (0.01,0) [0|0] "" Vector__XXX
 SG_ BMS_a077_chargeErrType m77 : 16|1@1+ (1,0) [0|0] "" Vector__XXX
 SG_ BMS_a078_peakDchInChg m78 : 16|16@1- (0.1,0) [0|0] "" Vector__XXX
 SG_ BMS_a079_maxBrickVTarget m79 : 16|8@1+ (0.01,2) [0|0] "" Vector__XXX
 SG_ BMS_a080_ctrResistance m80 : 16|13@1+ (0.002442598329,0) [0|0] "" Vector__XXX
 SG_ BMS_a081_stateRequest m81 : 16|4@1+ (1,0) [0|0] "" Vector__XXX
 SG_ BMS_a082_stateRequest m82 : 16|4@1+ (1,0) [0|0] "" Vector__XXX
 SG_ BMS_a083_packContactorRequest m83 : 16|3@1+ (1,0) [0|0] "" Vector__XXX
 SG_ BMS_a084_sleepState m84 : 16|3@1+ (1,0) [0|0] "" Vector__XXX
 SG_ BMS_a085_packContactorSetStatePrev m85 : 16|4@1+ (1,0) [0|0] "" Vector__XXX
 SG_ BMS_a086_fcContactorSetStatePrev m86 : 16|4@1+ (1,0) [0|0] "" Vector__XXX
 SG_ BMS_a087_blockingAlert m87 : 16|9@1+ (1,0) [0|0] "" Vector__XXX
 SG_ BMS_a090_GTWmessageTout m90 : 16|4@1+ (1,0) [0|0] "" Vector__XXX
 SG_ BMS_a097_missingFrame m97 : 16|1@1+ (1,0) [0|0] "" Vector__XXX
 SG_ BMS_a098_breakLocationA m98 : 16|5@1+ (1,0) [0|0] "" Vector__XXX
 SG_ BMS_a099_breakLocationA m99 : 16|5@1+ (1,0) [0|0] "" Vector__XXX
 SG_ BMS_a100_testTrigger m100 : 16|1@1+ (1,0) [0|0] "" Vector__XXX
 SG_ BMS_a105_tSenseFailedModule1 m105 : 16|1@1+ (1,0) [0|0] "" Vector__XXX
 SG_ BMS_a106_minBrickT m106 : 16|8@1+ (0.5,0) [0|0] "" Vector__XXX
 SG_ BMS_a107_MIA_numBadReadings m107 : 16|8@1+ (1,0) [0|0] "" Vector__XXX
 SG_ BMS_a108_allDieTempsValid m108 : 16|1@1+ (1,0) [0|0] "" Vector__XXX
 SG_ BMS_a109_muteMask m109 : 16|16@1+ (1,0) [0|0] "" Vector__XXX
 SG_ BMS_a110_filteredAverageOffset m110 : 16|10@1- (0.1,0) [0|0] "" Vector__XXX
 SG_ BMS_a111_maxSpreadChangeBrickId m111 : 16|7@1+ (1,1) [0|0] "" Vector__XXX
 SG_ BMS_a112_previousAverageOffset m112 : 16|10@1- (0.1,0) [0|0] "" Vector__XXX
 SG_ BMS_a115_actualNominalSoe m115 : 16|10@1+ (0.1,0) [0|0] "" Vector__XXX
 SG_ BMS_a117_brickID m117 : 16|7@1+ (1,1) [0|0] "" Vector__XXX
 SG_ BMS_a119_detectionSource m119 : 16|2@1+ (1,0) [0|0] "" Vector__XXX
 SG_ BMS_a121_nvramErrorType m121 : 16|2@1+ (1,0) [0|0] "" Vector__XXX
 SG_ BMS_a122_thermistorID m122 : 16|5@1+ (1,1) [0|0] "" Vector__XXX
 SG_ BMS_a126_thermistorFailureType m126 : 16|2@1+ (1,0) [0|0] "" Vector__XXX
 SG_ BMS_a129_brickID m129 : 16|8@1+ (1,1) [0|0] "" Vector__XXX
 SG_ BMS_a130_canBus m130 : 16|2@1+ (1,0) [0|0] "" Vector__XXX
 SG_ BMS_a131_brickID m131 : 16|8@1+ (1,1) [0|0] "" Vector__XXX
 SG_ BMS_a132_multiVendorErrorMask m132 : 16|16@1+ (1,0) [0|0] "" Vector__XXX
 SG_ BMS_a133_canBus m133 : 16|2@1+ (1,0) [0|0] "" Vector__XXX
 SG_ BMS_a134_packCurrent m134 : 16|8@1- (1,0) [0|0] "" Vector__XXX
 SG_ BMS_a135_bmbDiagnosticsType m135 : 16|2@1+ (1,0) [0|0] "" Vector__XXX
 SG_ BMS_a136_maxBrickTID m136 : 16|5@1+ (1,1) [0|0] "" Vector__XXX
 SG_ BMS_a137_SOC m137 : 16|8@1+ (1,0) [0|0] "" Vector__XXX
 SG_ BMS_a138_SOC m138 : 16|8@1+ (1,0) [0|0] "" Vector__XXX
 SG_ BMS_a139_packVoltage m139 : 16|16@1- (0.01,0) [0|0] "" Vector__XXX
 SG_ BMS_a140_bmbDeviceMask m140 : 16|16@1+ (1,0) [0|0] "" Vector__XXX
 SG_ BMS_a141_singleVendorErrorMask m141 : 16|16@1+ (1,0) [0|0] "" Vector__XXX
 SG_ BMS_a142_isolationResistance m142 : 16|10@1+ (10,0) [0|0] "" Vector__XXX
 SG_ BMS_a143_initialSoc m143 : 16|9@1+ (0.2,0) [0|0] "" Vector__XXX
 SG_ BMS_a144_HVP_major_version m144 : 16|16@1+ (1,0) [0|0] "" Vector__XXX
 SG_ BMS_a145_maxSocChange m145 : 16|11@1- (0.1,0) [0|0] "" Vector__XXX
 SG_ BMS_a146_maxBrickV m146 : 16|8@1+ (0.01,2) [0|0] "" Vector__XXX
 SG_ BMS_a147_socByAhRaw m147 : 16|11@1+ (0.1,0) [0|0] "" Vector__XXX
 SG_ BMS_a152_isoR m152 : 16|9@1+ (10,0) [0|0] "" Vector__XXX
 SG_ BMS_a154_packCurrent m154 : 16|8@1+ (4,0) [0|0] "" Vector__XXX
 SG_ BMS_a155_worstBrickId m155 : 16|7@1+ (1,1) [0|0] "" Vector__XXX
 SG_ BMS_a156_VrefSample m156 : 16|16@1+ (0.0001,0) [0|0] "" Vector__XXX
 SG_ BMS_a157_histogramIdMask m157 : 16|8@1+ (1,0) [0|0] "" Vector__XXX
 SG_ BMS_a158_shuntCurrentMia m158 : 16|1@1+ (1,0) [0|0] "" Vector__XXX
 SG_ BMS_a161_VrefSample m161 : 16|16@1+ (0.0001,0) [0|0] "" Vector__XXX
 SG_ BMS_a162_dischargePower_W m162 : 16|16@1- (1,0) [0|0] "" Vector__XXX
 SG_ BMS_a164_regenPower m164 : 16|32@1+ (1,0) [0|0] "" Vector__XXX
 SG_ BMS_a165_packPositiveV m165 : 16|12@1- (0.25,0) [0|0] "" Vector__XXX
 SG_ BMS_a166_packPositiveV m166 : 16|12@1- (0.25,0) [0|0] "" Vector__XXX
 SG_ BMS_a167_fcContPositiveAuxOpen m167 : 16|1@1+ (1,0) [0|0] "" Vector__XXX
 SG_ BMS_a168_fcContPositiveAuxOpen m168 : 16|1@1+ (1,0) [0|0] "" Vector__XXX
 SG_ BMS_a169_DCAndFCContactorsWelded m169 : 16|1@1+ (1,0) [0|0] "" Vector__XXX
 SG_ BMS_a170_limpModeActive m170 : 16|1@1+ (1,0) [0|0] "" Vector__XXX
 SG_ BMS_a171_stackVoltage m171 : 16|16@1+ (0.00128,0) [0|0] "" Vector__XXX
 SG_ BMS_a172_swIsolationCount m172 : 16|8@1+ (1,0) [0|0] "" Vector__XXX
 SG_ BMS_a177_energyAlertThreshold m177 : 16|10@1+ (0.1,0) [0|0] "" Vector__XXX
 SG_ BMS_a178_diPower m178 : 16|9@1- (4.313725490196078,250.1960784313725) [0|0] "" Vector__XXX
 SG_ BMS_a182_noCurrentCapacityLossDelta m182 : 16|9@1- (0.2,0) [0|0] "" Vector__XXX
 SG_ BMS_a183_storageDcrGrowthFracDelta m183 : 16|11@1- (0.1,0) [0|0] "" Vector__XXX
 SG_ BMS_a184_prevCyclingCapacityLoss m184 : 16|10@1+ (0.1,0) [0|0] "" Vector__XXX
 SG_ BMS_a185_prevDcrGrowthFrac m185 : 16|12@1+ (0.1,0) [0|0] "" Vector__XXX
 SG_ BMS_a186_prevRippleState m186 : 16|3@1+ (1,0) [0|0] "" Vector__XXX
 SG_ BMS_a187_actualCurrentAmplitudeIsNonZero m187 : 16|1@1+ (1,0) [0|0] "" Vector__XXX
 SG_ BMS_a188_currentTripThreshold m188 : 16|16@1+ (0.0025,0) [0|0] "" Vector__XXX
 SG_ BMS_a189_currentTripThreshold m189 : 16|16@1- (0.0025,-75) [0|0] "" Vector__XXX
 SG_ BMS_a190_voltageTripThreshold m190 : 16|16@1+ (0.025,0) [0|0] "" Vector__XXX
 SG_ BMS_a191_voltageTripThreshold m191 : 16|16@1+ (0.025,0) [0|0] "" Vector__XXX
 SG_ BMS_a192_detectedChargeCurrent m192 : 16|16@1+ (0.0025,0) [0|0] "" Vector__XXX
 SG_ BMS_a193_maxBrickVoltageLimit m193 : 16|12@1+ (0.001,1) [0|0] "" Vector__XXX
 SG_ BMS_a195_minThermistorID m195 : 16|5@1+ (1,1) [0|0] "" Vector__XXX
 SG_ BMS_a196_packVoltage m196 : 16|16@1- (0.01,0) [0|0] "" Vector__XXX
 SG_ BMS_a197_maxSoc m197 : 16|16@1+ (0.01,0) [0|0] "" Vector__XXX
 SG_ BMS_a198_maxSocAbruptChange m198 : 16|11@1- (0.1,0) [0|0] "" Vector__XXX
 SG_ BMS_a022_chargeAccumulatorValue m22 : 17|23@1+ (10,0) [0|0] "" Vector__XXX
 SG_ BMS_a055_invalidShuntData m55 : 17|1@1+ (1,0) [0|0] "" Vector__XXX
 SG_ BMS_a097_timeout m97 : 17|1@1+ (1,0) [0|0] "" Vector__XXX
 SG_ BMS_a100_setFromNvm m100 : 17|1@1+ (1,0) [0|0] "" Vector__XXX
 SG_ BMS_a105_avgBrickTModule1 m105 : 17|8@1+ (0.5,0) [0|0] "" Vector__XXX
 SG_ BMS_a108_deviceInBleed m108 : 17|1@1+ (1,0) [0|0] "" Vector__XXX
 SG_ BMS_a158_contactorStateMia m158 : 17|1@1+ (1,0) [0|0] "" Vector__XXX
 SG_ BMS_a167_fcContNegativeAuxOpen m167 : 17|1@1+ (1,0) [0|0] "" Vector__XXX
 SG_ BMS_a168_fcContNegativeAuxOpen m168 : 17|1@1+ (1,0) [0|0] "" Vector__XXX
 SG_ BMS_a187_actualVoltageAmplitudeIsNonZero m187 : 17|1@1+ (1,0) [0|0] "" Vector__XXX
 SG_ BMS_a001_expectedPackEnergy m1 : 18|2@1+ (1,0) [0|0] "" Vector__XXX
 SG_ BMS_a055_invalidBmbVoltageData m55 : 18|1@1+ (1,0) [0|0] "" Vector__XXX
 SG_ BMS_a100_voltageDeviation m100 : 18|1@1+ (1,0) [0|0] "" Vector__XXX
 SG_ BMS_a108_minDeviceId m108 : 18|4@1+ (1,1) [0|0] "" Vector__XXX
 SG_ BMS_a126_thermistorID m126 : 18|5@1+ (1,1) [0|0] "" Vector__XXX
 SG_ BMS_a130_errorType m130 : 18|5@1+ (1,0) [0|0] "" Vector__XXX
 SG_ BMS_a135_bmbDeviceId m135 : 18|4@1+ (1,1) [0|0] "" Vector__XXX
 SG_ BMS_a158_hvpFaultsMia m158 : 18|1@1+ (1,0) [0|0] "" Vector__XXX
 SG_ BMS_a167_dcLinkPositiveV m167 : 18|11@1- (0.5,0) [0|0] "" Vector__XXX
 SG_ BMS_a168_dcLinkPositiveV m168 : 18|11@1- (0.5,0) [0|0] "" Vector__XXX
 SG_ BMS_a002_expectedPackPerformanceDeviation m2 : 19|3@1+ (1,0) [0|0] "" Vector__XXX
 SG_ BMS_a037_floodPort1Voltage m37 : 19|12@1+ (0.001,0) [0|0] "" Vector__XXX
 SG_ BMS_a043_traceIndex m43 : 19|4@1+ (1,0) [0|0] "" Vector__XXX
 SG_ BMS_a045_exceptionRegisterType m45 : 19|3@1+ (1,0) [0|0] "" Vector__XXX
 SG_ BMS_a046_taskStackAllocated m46 : 19|12@1+ (1,0) [0|0] "" Vector__XXX
 SG_ BMS_a048_checkInCounter m48 : 19|4@1+ (1,0) [0|0] "" Vector__XXX
 SG_ BMS_a055_invalidPtInletTemperature m55 : 19|1@1+ (1,0) [0|0] "" Vector__XXX
 SG_ BMS_a084_hviBusResource m84 : 19|3@1+ (1,0) [0|0] "" Vector__XXX
 SG_ BMS_a100_voltageLoss m100 : 19|1@1+ (1,0) [0|0] "" Vector__XXX
 SG_ BMS_a186_dcChargeInFault m186 : 19|1@1+ (1,0) [0|0] "" Vector__XXX
 SG_ BMS_a055_invalidAmbientTemperature m55 : 20|1@1+ (1,0) [0|0] "" Vector__XXX
 SG_ BMS_a058_thermistorTempsInvalid m58 : 20|1@1+ (1,0) [0|0] "" Vector__XXX
 SG_ BMS_a071_state m71 : 20|4@1+ (1,0) [0|0] "" Vector__XXX
 SG_ BMS_a081_firstBlockingAlertId m81 : 20|9@1+ (1,0) [0|0] "" Vector__XXX
 SG_ BMS_a082_firstAlertId m82 : 20|9@1+ (1,0) [0|0] "" Vector__XXX
 SG_ BMS_a085_packContactorSetState m85 : 20|4@1+ (1,0) [0|0] "" Vector__XXX
 SG_ BMS_a086_fcContactorSetState m86 : 20|4@1+ (1,0) [0|0] "" Vector__XXX
 SG_ BMS_a186_evseAcRippleStatus m186 : 20|3@1+ (1,0) [0|0] "" Vector__XXX
 SG_ BMS_a055_invalidThermistorData m55 : 21|1@1+ (1,0) [0|0] "" Vector__XXX
 SG_ BMS_a058_inletCoolantTempInvalid m58 : 21|1@1+ (1,0) [0|0] "" Vector__XXX
 SG_ BMS_a098_bmbCommStatusTypeA m98 : 21|2@1+ (1,0) [0|0] "" Vector__XXX
 SG_ BMS_a099_bmbCommStatusTypeA m99 : 21|2@1+ (1,0) [0|0] "" Vector__XXX
 SG_ BMS_a119_brickId m119 : 21|7@1+ (1,1) [0|0] "" Vector__XXX
 SG_ BMS_a055_invalidPackVoltageData m55 : 22|1@1+ (1,0) [0|0] "" Vector__XXX
 SG_ BMS_a058_ambientTempInvalid m58 : 22|1@1+ (1,0) [0|0] "" Vector__XXX
 SG_ BMS_a084_hvsBusResource m84 : 22|3@1+ (1,0) [0|0] "" Vector__XXX
 SG_ BMS_a108_minDieTemp m108 : 22|10@1+ (0.2,-20) [0|0] "" Vector__XXX
 SG_ BMS_a135_readCVA m135 : 22|1@1+ (1,0) [0|0] "" Vector__XXX
 SG_ BMS_a055_diUnhealthy m55 : 23|1@1+ (1,0) [0|0] "" Vector__XXX
 SG_ BMS_a058_flowRateInvalid m58 : 23|1@1+ (1,0) [0|0] "" Vector__XXX
 SG_ BMS_a117_brickSoc2 m117 : 23|10@1+ (0.1,0) [0|0] "" Vector__XXX
 SG_ BMS_a135_readCVB m135 : 23|1@1+ (1,0) [0|0] "" Vector__XXX
 SG_ BMS_a186_peakMaxVoltageFault m186 : 23|1@1+ (1,0) [0|0] "" Vector__XXX
 SG_ BMS_a002_bmsPackMass m2 : 24|8@1+ (1,300) [0|0] "" Vector__XXX
 SG_ BMS_a016_moduleMismatchMask m16 : 24|8@1+ (1,0) [0|0] "" Vector__XXX
 SG_ BMS_a017_ovBrickVID m17 : 24|7@1+ (1,1) [0|0] "" Vector__XXX
 SG_ BMS_a018_uvBrickVID m18 : 24|7@1+ (1,1) [0|0] "" Vector__XXX
 SG_ BMS_a019_activeCoolingTarget m19 : 24|8@1+ (0.4,-20) [0|0] "" Vector__XXX
 SG_ BMS_a020_unstableBrickVID m20 : 24|7@1+ (1,1) [0|0] "" Vector__XXX
 SG_ BMS_a021_currentLimit m21 : 24|8@1+ (8,-1496) [0|0] "" Vector__XXX
 SG_ BMS_a023_ovStackV m23 : 24|16@1+ (0.00128,0) [0|0] "" Vector__XXX
 SG_ BMS_a024_deltaV m24 : 24|16@1- (0.0001,0) [0|0] "" Vector__XXX
 SG_ BMS_a030_maxBrickImpedance m30 : 24|10@1+ (0.1,0) [0|0] "" Vector__XXX
 SG_ BMS_a043_traceDump m43 : 24|32@1+ (1,0) [0|0] "" Vector__XXX
 SG_ BMS_a044_assertTag m44 : 24|8@1+ (1,0) [0|0] "" Vector__XXX
 SG_ BMS_a045_exceptionRegisterIndex m45 : 24|3@1+ (1,0) [0|0] "" Vector__XXX
 SG_ BMS_a050_MIA_numSnaReadings m50 : 24|8@1+ (1,0) [0|0] "" Vector__XXX
 SG_ BMS_a055_disUnhealthy m55 : 24|1@1+ (1,0) [0|0] "" Vector__XXX
 SG_ BMS_a057_tempDelta1 m57 : 24|7@1- (0.2,0) [0|0] "" Vector__XXX
 SG_ BMS_a058_brickDissipationInvalid m58 : 24|1@1+ (1,0) [0|0] "" Vector__XXX
 SG_ BMS_a061_maxChangeBrickId m61 : 24|7@1+ (1,1) [0|0] "" Vector__XXX
 SG_ BMS_a062_minBrickVId m62 : 24|7@1+ (1,1) [0|0] "" Vector__XXX
 SG_ BMS_a064_minBrickSOC m64 : 24|8@1+ (0.5,0) [0|0] "" Vector__XXX
 SG_ BMS_a065_minBrickCac m65 : 24|13@1+ (0.1,0) [0|0] "" Vector__XXX
 SG_ BMS_a066_minBrickSocByOcvMax m66 : 24|8@1+ (0.5,0) [0|0] "" Vector__XXX
 SG_ BMS_a067_minBrickCac m67 : 24|13@1+ (0.1,0) [0|0] "" Vector__XXX
 SG_ BMS_a068_minBrickCac m68 : 24|13@1+ (0.1,0) [0|0] "" Vector__XXX
 SG_ BMS_a069_dischargePowerBrickVoltageFloor m69 : 24|8@1- (0.005,-0.63) [0|0] "" Vector__XXX
 SG_ BMS_a070_minBrickVId m70 : 24|7@1+ (1,1) [0|0] "" Vector__XXX
 SG_ BMS_a071_transitionAlertId m71 : 24|10@1+ (1,0) [0|0] "" Vector__XXX
 SG_ BMS_a072_edgeBrickCac m72 : 24|13@1+ (0.1,0) [0|0] "" Vector__XXX
 SG_ BMS_a074_maxBrickV m74 : 24|8@1+ (0.01,2) [0|0] "" Vector__XXX
 SG_ BMS_a077_maxBrickVTarget m77 : 24|8@1+ (0.01,2) [0|0] "" Vector__XXX
 SG_ BMS_a079_maxBrickV m79 : 24|8@1+ (0.01,2) [0|0] "" Vector__XXX
 SG_ BMS_a085_packContactorSetRequestPrev m85 : 24|3@1+ (1,0) [0|0] "" Vector__XXX
 SG_ BMS_a086_fcContactorSetRequestPrev m86 : 24|3@1+ (1,0) [0|0] "" Vector__XXX
 SG_ BMS_a098_breakLocationB m98 : 24|5@1+ (1,0) [0|0] "" Vector__XXX
 SG_ BMS_a099_breakLocationB m99 : 24|5@1+ (1,0) [0|0] "" Vector__XXX
 SG_ BMS_a106_maxBrickT m106 : 24|8@1+ (0.5,0) [0|0] "" Vector__XXX
 SG_ BMS_a107_MIA_numSnaReadings m107 : 24|8@1+ (1,0) [0|0] "" Vector__XXX
 SG_ BMS_a111_brickCacRaw m111 : 24|12@1+ (0.1,0) [0|0] "" Vector__XXX
 SG_ BMS_a122_irrationalThermistorTemp m122 : 24|8@1+ (0.5,-40) [0|0] "" Vector__XXX
 SG_ BMS_a126_loadedTemperature m126 : 24|16@1- (0.01,0) [0|0] "" Vector__XXX
 SG_ BMS_a129_deltaV m129 : 24|16@1- (0.0002,0) [0|0] "" Vector__XXX
 SG_ BMS_a130_errorCount m130 : 24|8@1+ (1,0) [0|0] "" Vector__XXX
 SG_ BMS_a131_deltaV m131 : 24|16@1- (0.0002,0) [0|0] "" Vector__XXX
 SG_ BMS_a134_SOC m134 : 24|8@1+ (1,0) [0|0] "" Vector__XXX
 SG_ BMS_a135_readCVC m135 : 24|1@1+ (1,0) [0|0] "" Vector__XXX
 SG_ BMS_a136_coolantInletT m136 : 24|8@1+ (0.4,-20) [0|0] "" Vector__XXX
 SG_ BMS_a137_maxUvDeltaBrickV m137 : 24|8@1- (0.02,0) [0|0] "" Vector__XXX
 SG_ BMS_a138_ovMinDeltaBrickV m138 : 24|8@1- (0.02,0) [0|0] "" Vector__XXX
 SG_ BMS_a146_state m146 : 24|4@1+ (1,0) [0|0] "" Vector__XXX
 SG_ BMS_a154_ovBrickVID m154 : 24|7@1+ (1,1) [0|0] "" Vector__XXX
 SG_ BMS_a155_minBrickVDelta m155 : 24|15@1- (0.0005,0) [0|0] "" Vector__XXX
 SG_ BMS_a157_maxLostDataHistId m157 : 24|4@1+ (1,0) [0|0] "" Vector__XXX
 SG_ BMS_a186_peakMinVoltageFault m186 : 24|1@1+ (1,0) [0|0] "" Vector__XXX
 SG_ BMS_a195_maxThermistorID m195 : 24|5@1+ (1,1) [0|0] "" Vector__XXX
 SG_ BMS_a025_energyError m25 : 25|8@1- (2,0) [0|0] "" Vector__XXX
 SG_ BMS_a035_mode m35 : 25|3@1+ (1,0) [0|0] "" Vector__XXX
 SG_ BMS_a058_sanityCheckFailed m58 : 25|1@1+ (1,0) [0|0] "" Vector__XXX
 SG_ BMS_a084_vehBusResource m84 : 25|3@1+ (1,0) [0|0] "" Vector__XXX
 SG_ BMS_a105_tSenseFailedModule2 m105 : 25|1@1+ (1,0) [0|0] "" Vector__XXX
 SG_ BMS_a135_readCVD m135 : 25|1@1+ (1,0) [0|0] "" Vector__XXX
 SG_ BMS_a143_endingSoc m143 : 25|9@1+ (0.2,0) [0|0] "" Vector__XXX
 SG_ BMS_a152_mode m152 : 25|3@1+ (1,0) [0|0] "" Vector__XXX
 SG_ BMS_a178_energyError m178 : 25|8@1- (2,0) [0|0] "" Vector__XXX
 SG_ BMS_a182_packAgeInDaysBinned m182 : 25|13@1+ (1,0) [0|0] "" Vector__XXX
 SG_ BMS_a186_peakCurrentAmplitudeFault m186 : 25|1@1+ (1,0) [0|0] "" Vector__XXX
 SG_ BMS_a034_packContactorSetState m34 : 26|4@1+ (1,0) [0|0] "" Vector__XXX
 SG_ BMS_a039_packVoltage m39 : 26|10@1+ (1,0) [0|0] "" Vector__XXX
 SG_ BMS_a105_avgBrickTModule2 m105 : 26|8@1+ (0.5,0) [0|0] "" Vector__XXX
 SG_ BMS_a110_previousAverageOffset m110 : 26|10@1- (0.1,0) [0|0] "" Vector__XXX
 SG_ BMS_a112_newAverageOffset m112 : 26|10@1- (0.1,0) [0|0] "" Vector__XXX
 SG_ BMS_a115_actualIdealSoe m115 : 26|10@1+ (0.1,0) [0|0] "" Vector__XXX
 SG_ BMS_a135_readCVE m135 : 26|1@1+ (1,0) [0|0] "" Vector__XXX
 SG_ BMS_a177_energyBuffer m177 : 26|10@1+ (0.1,0) [0|0] "" Vector__XXX
 SG_ BMS_a184_cyclingCapacityLossDelta m184 : 26|9@1- (0.2,0) [0|0] "" Vector__XXX
 SG_ BMS_a186_actualVsRequestFrequencyInvalid m186 : 26|1@1+ (1,0) [0|0] "" Vector__XXX
 SG_ BMS_a085_packContactorSetRequest m85 : 27|3@1+ (1,0) [0|0] "" Vector__XXX
 SG_ BMS_a086_fcContactorSetRequest m86 : 27|3@1+ (1,0) [0|0] "" Vector__XXX
 SG_ BMS_a135_readCVF m135 : 27|1@1+ (1,0) [0|0] "" Vector__XXX
 SG_ BMS_a147_socByAhSaturated m147 : 27|10@1+ (0.1,0) [0|0] "" Vector__XXX
 SG_ BMS_a183_packAgeInDaysBinned m183 : 27|13@1+ (1,0) [0|0] "" Vector__XXX
 SG_ BMS_a186_amplitudeOverCurrent m186 : 27|1@1+ (1,0) [0|0] "" Vector__XXX
 SG_ BMS_a032_maxBrickV m32 : 28|12@1+ (0.002,0) [0|0] "" Vector__XXX
 SG_ BMS_a033_maxBrickV m33 : 28|12@1+ (0.002,0) [0|0] "" Vector__XXX
 SG_ BMS_a035_activeSideVNoR m35 : 28|9@1+ (1,0) [0|0] "" Vector__XXX
 SG_ BMS_a051_hvp3V0Ref m51 : 28|12@1+ (0.001,0) [0|0] "" Vector__XXX
 SG_ BMS_a056_packVoltage m56 : 28|16@1+ (0.01,0) [0|0] "" Vector__XXX
 SG_ BMS_a084_hvpResource m84 : 28|3@1+ (1,0) [0|0] "" Vector__XXX
 SG_ BMS_a135_readSNA m135 : 28|1@1+ (1,0) [0|0] "" Vector__XXX
 SG_ BMS_a152_activeSideVNoR m152 : 28|9@1+ (1,0) [0|0] "" Vector__XXX
 SG_ BMS_a165_packNegativeV m165 : 28|12@1- (0.25,0) [0|0] "" Vector__XXX
 SG_ BMS_a166_packNegativeV m166 : 28|12@1- (0.25,0) [0|0] "" Vector__XXX
 SG_ BMS_a185_dcrGrowthFracDelta m185 : 28|11@1- (0.1,0) [0|0] "" Vector__XXX
 SG_ BMS_a186_amplitudeOverVoltage m186 : 28|1@1+ (1,0) [0|0] "" Vector__XXX
 SG_ BMS_a193_detectedMaxBrickVoltage m193 : 28|12@1+ (0.001,1) [0|0] "" Vector__XXX
 SG_ BMS_a081_secondBlockingAlertId m81 : 29|9@1+ (1,0) [0|0] "" Vector__XXX
 SG_ BMS_a082_secondAlertId m82 : 29|9@1+ (1,0) [0|0] "" Vector__XXX
 SG_ BMS_a098_bmbCommStatusTypeB m98 : 29|2@1+ (1,0) [0|0] "" Vector__XXX
 SG_ BMS_a099_bmbCommStatusTypeB m99 : 29|2@1+ (1,0) [0|0] "" Vector__XXX
 SG_ BMS_a135_readSNB m135 : 29|1@1+ (1,0) [0|0] "" Vector__XXX
 SG_ BMS_a167_dcLinkNegativeV m167 : 29|11@1- (0.5,0) [0|0] "" Vector__XXX
 SG_ BMS_a168_dcLinkNegativeV m168 : 29|11@1- (0.5,0) [0|0] "" Vector__XXX
 SG_ BMS_a186_actualFrequencyIsNonZero m186 : 29|1@1+ (1,0) [0|0] "" Vector__XXX
 SG_ BMS_a135_readSNC m135 : 30|1@1+ (1,0) [0|0] "" Vector__XXX
 SG_ BMS_a186_evseAmplitudeOverVoltage m186 : 30|1@1+ (1,0) [0|0] "" Vector__XXX
 SG_ BMS_a084_bmsResource m84 : 31|3@1+ (1,0) [0|0] "" Vector__XXX
 SG_ BMS_a098_alertFromHvp m98 : 31|1@1+ (1,0) [0|0] "" Vector__XXX
 SG_ BMS_a135_readSND m135 : 31|1@1+ (1,0) [0|0] "" Vector__XXX
 SG_ BMS_a186_evseAmplitudeOverCurrent m186 : 31|1@1+ (1,0) [0|0] "" Vector__XXX
 SG_ BMS_a000_alertDataW1 m0 : 32|16@1+ (1,0) [0|0] "" Vector__XXX
 SG_ BMS_a016_mismatchModuleId m16 : 32|16@1+ (1,0) [0|0] "" Vector__XXX
 SG_ BMS_a017_ovBrickV m17 : 32|16@1+ (7.6293945313e-05,0) [0|0] "" Vector__XXX
 SG_ BMS_a018_uvBrickV m18 : 32|16@1+ (7.6293945313e-05,0) [0|0] "" Vector__XXX
 SG_ BMS_a019_maxBrickT m19 : 32|8@1+ (0.4,-20) [0|0] "" Vector__XXX
 SG_ BMS_a020_lastBrickVDelta m20 : 32|16@1- (0.00152590219,-0.49897001613) [0|0] "" Vector__XXX
 SG_ BMS_a021_packCurrent m21 : 32|8@1+ (8,-1496) [0|0] "" Vector__XXX
 SG_ BMS_a026_deltaPackCurrent m26 : 32|13@1+ (1,0) [0|0] "" Vector__XXX
 SG_ BMS_a028_AsicTemperature m28 : 32|10@1+ (0.1,0) [0|0] "" Vector__XXX
 SG_ BMS_a034_packPositiveRatio m34 : 32|8@1+ (0.1,0) [0|0] "" Vector__XXX
 SG_ BMS_a037_floodPort2State m37 : 32|3@1+ (1,0) [0|0] "" Vector__XXX
 SG_ BMS_a044_assertData1 m44 : 32|16@1+ (1,0) [0|0] "" Vector__XXX
 SG_ BMS_a045_exceptionRegisterData m45 : 32|32@1+ (1,0) [0|0] "" Vector__XXX
 SG_ BMS_a046_taskStackWatermark m46 : 32|12@1+ (1,0) [0|0] "" Vector__XXX
 SG_ BMS_a054_verSupplyVMax m54 : 32|16@1+ (0.001,0) [0|0] "" Vector__XXX
 SG_ BMS_a057_tempDelta2 m57 : 32|7@1- (0.2,0) [0|0] "" Vector__XXX
 SG_ BMS_a058_tempDelta1 m58 : 32|7@1- (0.2,0) [0|0] "" Vector__XXX
 SG_ BMS_a059_packVoltage m59 : 32|16@1+ (0.01,0) [0|0] "" Vector__XXX
 SG_ BMS_a061_maxChangeBrickStatus m61 : 32|2@1+ (1,0) [0|0] "" Vector__XXX
 SG_ BMS_a062_minBrickVoltage m62 : 32|12@1+ (0.002,0) [0|0] "" Vector__XXX
 SG_ BMS_a064_maxBrickSOCID m64 : 32|7@1+ (1,1) [0|0] "" Vector__XXX
 SG_ BMS_a066_maxBrickSocId m66 : 32|7@1+ (1,1) [0|0] "" Vector__XXX
 SG_ BMS_a069_SOC m69 : 32|8@1+ (0.05,0) [0|0] "" Vector__XXX
 SG_ BMS_a070_minBrickVoltage m70 : 32|12@1+ (0.002,0) [0|0] "" Vector__XXX
 SG_ BMS_a077_maxBrickV m77 : 32|8@1+ (0.01,2) [0|0] "" Vector__XXX
 SG_ BMS_a080_ctrResistanceConfidence m80 : 32|14@1+ (10,0) [0|0] "" Vector__XXX
 SG_ BMS_a099_bmbChainBreakType m99 : 32|3@1+ (1,0) [0|0] "" Vector__XXX
 SG_ BMS_a106_avgBrickT m106 : 32|8@1+ (0.5,0) [0|0] "" Vector__XXX
 SG_ BMS_a108_maxDeviceId m108 : 32|4@1+ (1,1) [0|0] "" Vector__XXX
 SG_ BMS_a109_packInBleed m109 : 32|1@1+ (1,0) [0|0] "" Vector__XXX
 SG_ BMS_a122_averageRawThermistorTemp m122 : 32|8@1+ (0.5,-40) [0|0] "" Vector__XXX
 SG_ BMS_a123_packPlus m123 : 32|8@1+ (4,0) [0|0] "" Vector__XXX
 SG_ BMS_a130_errorValue1 m130 : 32|16@1+ (1,0) [0|0] "" Vector__XXX
 SG_ BMS_a134_minBrickVLimit m134 : 32|8@1+ (0.01,2) [0|0] "" Vector__XXX
 SG_ BMS_a135_readSNE m135 : 32|1@1+ (1,0) [0|0] "" Vector__XXX
 SG_ BMS_a136_activeCoolingTarget m136 : 32|8@1+ (0.4,-20) [0|0] "" Vector__XXX
 SG_ BMS_a137_packCurrent m137 : 32|8@1+ (8,-1496) [0|0] "" Vector__XXX
 SG_ BMS_a138_packCurrent m138 : 32|8@1+ (8,-1496) [0|0] "" Vector__XXX
 SG_ BMS_a139_dcLinkVoltage m139 : 32|16@1+ (0.01,0) [0|0] "" Vector__XXX
 SG_ BMS_a140_faultType m140 : 32|8@1+ (1,0) [0|0] "" Vector__XXX
 SG_ BMS_a142_mode m142 : 32|3@1+ (1,0) [0|0] "" Vector__XXX
 SG_ BMS_a144_HVP_minor_version m144 : 32|16@1+ (1,0) [0|0] "" Vector__XXX
 SG_ BMS_a145_maxSocChangeBrickID m145 : 32|7@1+ (1,1) [0|0] "" Vector__XXX
 SG_ BMS_a146_packCurrent m146 : 32|8@1+ (8,-1496) [0|0] "" Vector__XXX
 SG_ BMS_a151_isoPositiveR m151 : 32|10@1+ (10,0) [0|0] "" Vector__XXX
 SG_ BMS_a154_ovBrickV m154 : 32|16@1+ (7.6293945313e-05,0) [0|0] "" Vector__XXX
 SG_ BMS_a156_bmbDeviceId m156 : 32|4@1+ (1,1) [0|0] "" Vector__XXX
 SG_ BMS_a157_publishedDataCounter m157 : 32|16@1+ (1,0) [0|0] "" Vector__XXX
 SG_ BMS_a161_bmbDeviceId m161 : 32|4@1+ (1,1) [0|0] "" Vector__XXX
 SG_ BMS_a162_minSoc m162 : 32|16@1+ (1,0) [0|0] "" Vector__XXX
 SG_ BMS_a171_sumBrickVoltage m171 : 32|16@1+ (0.00128,0) [0|0] "" Vector__XXX
 SG_ BMS_a186_filteredCurrentsNotValid m186 : 32|1@1+ (1,0) [0|0] "" Vector__XXX
 SG_ BMS_a188_dcLinkDetectedCurrent m188 : 32|16@1+ (0.0025,0) [0|0] "" Vector__XXX
 SG_ BMS_a189_dcLinkDetectedCurrent m189 : 32|16@1- (0.0025,-75) [0|0] "" Vector__XXX
 SG_ BMS_a190_dcLinkDetectedVoltage m190 : 32|16@1+ (0.025,0) [0|0] "" Vector__XXX
 SG_ BMS_a191_dcLinkDetectedVoltage m191 : 32|16@1+ (0.025,0) [0|0] "" Vector__XXX
 SG_ BMS_a195_temperatureMaxDelta m195 : 32|8@1+ (0.5,0) [0|0] "" Vector__XXX
 SG_ BMS_a196_minPackVoltageThreshold m196 : 32|16@1- (0.01,0) [0|0] "" Vector__XXX
 SG_ BMS_a197_maxSocIndex m197 : 32|7@1+ (1,1) [0|0] "" Vector__XXX
 SG_ BMS_a198_maxSocAbruptChangeBrickIndex m198 : 32|7@1+ (1,1) [0|0] "" Vector__XXX
 SG_ BMS_a025_powerError m25 : 33|9@1- (1,0) [0|0] "" Vector__XXX
 SG_ BMS_a117_dSocAlertThreshold m117 : 33|5@1+ (0.125,-4) [0|0] "" Vector__XXX
 SG_ BMS_a135_readSNF m135 : 33|1@1+ (1,0) [0|0] "" Vector__XXX
 SG_ BMS_a178_powerError m178 : 33|9@1- (1,0) [0|0] "" Vector__XXX
 SG_ BMS_a030_maxNormalizedImpedanceDev m30 : 34|7@1+ (0.04,0) [0|0] "" Vector__XXX
 SG_ BMS_a061_initialBrickV m61 : 34|12@1+ (0.002,0) [0|0] "" Vector__XXX
 SG_ BMS_a084_cpResource m84 : 34|3@1+ (1,0) [0|0] "" Vector__XXX
 SG_ BMS_a105_tSenseFailedModule3 m105 : 34|1@1+ (1,0) [0|0] "" Vector__XXX
 SG_ BMS_a135_readAUXA m135 : 34|1@1+ (1,0) [0|0] "" Vector__XXX
 SG_ BMS_a143_deltaAh m143 : 34|9@1+ (0.5,0) [0|0] "" Vector__XXX
 SG_ BMS_a037_floodPort2Voltage m37 : 35|12@1+ (0.001,0) [0|0] "" Vector__XXX
 SG_ BMS_a099_alertFromHvp m99 : 35|1@1+ (1,0) [0|0] "" Vector__XXX
 SG_ BMS_a105_avgBrickTModule3 m105 : 35|8@1+ (0.5,0) [0|0] "" Vector__XXX
 SG_ BMS_a135_readAUXB m135 : 35|1@1+ (1,0) [0|0] "" Vector__XXX
 SG_ BMS_a184_packCyclesCount m184 : 35|12@1+ (1,0) [0|0] "" Vector__XXX
 SG_ BMS_a039_packContactorState m39 : 36|4@1+ (1,0) [0|0] "" Vector__XXX
 SG_ BMS_a108_maxDieTemp m108 : 36|10@1+ (0.2,-20) [0|0] "" Vector__XXX
 SG_ BMS_a110_rawAverageOffset m110 : 36|10@1- (0.1,0) [0|0] "" Vector__XXX
 SG_ BMS_a111_prevBrickCacEstimate m111 : 36|12@1+ (0.1,0) [0|0] "" Vector__XXX
 SG_ BMS_a112_previousLifeModelBrickCapacity m112 : 36|12@1+ (0.1,0) [0|0] "" Vector__XXX
 SG_ BMS_a115_rbNominalSoe m115 : 36|10@1+ (0.1,0) [0|0] "" Vector__XXX
 SG_ BMS_a135_readSTAT m135 : 36|1@1+ (1,0) [0|0] "" Vector__XXX
 SG_ BMS_a156_VrefStatus m156 : 36|2@1+ (1,0) [0|0] "" Vector__XXX
 SG_ BMS_a161_VrefStatus m161 : 36|2@1+ (1,0) [0|0] "" Vector__XXX
 SG_ BMS_a035_activeSideVWithR m35 : 37|9@1+ (1,0) [0|0] "" Vector__XXX
 SG_ BMS_a076_tetheringActive m76 : 37|1@1+ (1,0) [0|0] "" Vector__XXX
 SG_ BMS_a084_pcsResource m84 : 37|3@1+ (1,0) [0|0] "" Vector__XXX
 SG_ BMS_a152_activeSideVWithR m152 : 37|9@1+ (1,0) [0|0] "" Vector__XXX
 SG_ BMS_a081_thirdBlockingAlertId m81 : 38|9@1+ (1,0) [0|0] "" Vector__XXX
 SG_ BMS_a082_thirdAlertId m82 : 38|9@1+ (1,0) [0|0] "" Vector__XXX
 SG_ BMS_a019_maxBrickTID m19 : 40|5@1+ (1,1) [0|0] "" Vector__XXX
 SG_ BMS_a022_chargeAccumulatorLimit m22 : 40|23@1+ (10,0) [0|0] "" Vector__XXX
 SG_ BMS_a024_avgDvPrev m24 : 40|16@1- (0.0001,0) [0|0] "" Vector__XXX
 SG_ BMS_a032_packCurrent m32 : 40|12@1- (1,0) [0|0] "" Vector__XXX
 SG_ BMS_a033_packCurrent m33 : 40|12@1- (1,0) [0|0] "" Vector__XXX
 SG_ BMS_a034_packNegativeRatio m34 : 40|8@1+ (0.1,0) [0|0] "" Vector__XXX
 SG_ BMS_a039_packCurrent m39 : 40|8@1+ (8,-1496) [0|0] "" Vector__XXX
 SG_ BMS_a051_bms3V0Ref m51 : 40|12@1+ (0.001,0) [0|0] "" Vector__XXX
 SG_ BMS_a057_tempDelta3 m57 : 40|7@1- (0.2,0) [0|0] "" Vector__XXX
 SG_ BMS_a058_tempDelta2 m58 : 40|7@1- (0.2,0) [0|0] "" Vector__XXX
 SG_ BMS_a064_maxBrickSOC m64 : 40|8@1+ (0.5,0) [0|0] "" Vector__XXX
 SG_ BMS_a065_avgBrickCac m65 : 40|13@1+ (0.1,0) [0|0] "" Vector__XXX
 SG_ BMS_a066_maxBrickSocByOcvMin m66 : 40|8@1+ (0.5,0) [0|0] "" Vector__XXX
 SG_ BMS_a067_avgBrickCac m67 : 40|13@1+ (0.1,0) [0|0] "" Vector__XXX
 SG_ BMS_a068_avgBrickCac m68 : 40|13@1+ (0.1,0) [0|0] "" Vector__XXX
 SG_ BMS_a069_minBrickT m69 : 40|8@1- (0.5,24) [0|0] "" Vector__XXX
 SG_ BMS_a072_moduleAvgBrickCac m72 : 40|13@1+ (0.1,0) [0|0] "" Vector__XXX
 SG_ BMS_a077_packTargetCurrent m77 : 40|8@1+ (8,-1496) [0|0] "" Vector__XXX
 SG_ BMS_a084_vcfResource m84 : 40|3@1+ (1,0) [0|0] "" Vector__XXX
 SG_ BMS_a106_inletTemp m106 : 40|8@1+ (0.5,0) [0|0] "" Vector__XXX
 SG_ BMS_a122_minRawThermistorTemp m122 : 40|8@1+ (0.5,-40) [0|0] "" Vector__XXX
 SG_ BMS_a123_isoR m123 : 40|10@1+ (10,0) [0|0] "" Vector__XXX
 SG_ BMS_a129_retryCount m129 : 40|4@1+ (1,0) [0|0] "" Vector__XXX
 SG_ BMS_a131_retryCount m131 : 40|4@1+ (1,0) [0|0] "" Vector__XXX
 SG_ BMS_a134_minBrickV m134 : 40|8@1+ (0.01,2) [0|0] "" Vector__XXX
 SG_ BMS_a136_maxBrickT m136 : 40|8@1+ (0.4,-20) [0|0] "" Vector__XXX
 SG_ BMS_a137_uvBrickVID m137 : 40|7@1+ (1,1) [0|0] "" Vector__XXX
 SG_ BMS_a138_ovBrickVID m138 : 40|7@1+ (1,1) [0|0] "" Vector__XXX
 SG_ BMS_a145_numBricksChanged m145 : 40|7@1+ (1,0) [0|0] "" Vector__XXX
 SG_ BMS_a146_uvBrickVID m146 : 40|7@1+ (1,1) [0|0] "" Vector__XXX
 SG_ BMS_a147_maxSocAhErrorBrickId m147 : 40|7@1+ (1,1) [0|0] "" Vector__XXX
 SG_ BMS_a155_worstBrickV m155 : 40|12@1+ (0.002,0) [0|0] "" Vector__XXX
 SG_ BMS_a165_dcLinkPositiveV m165 : 40|12@1- (0.25,0) [0|0] "" Vector__XXX
 SG_ BMS_a166_dcLinkPositiveV m166 : 40|12@1- (0.25,0) [0|0] "" Vector__XXX
 SG_ BMS_a167_fcLinkPositiveV m167 : 40|11@1- (0.5,0) [0|0] "" Vector__XXX
 SG_ BMS_a168_fcLinkPositiveV m168 : 40|11@1- (0.5,0) [0|0] "" Vector__XXX
 SG_ BMS_a182_socSensitivityMax m182 : 40|7@1+ (0.001,0) [0|0] "" Vector__XXX
 SG_ BMS_a183_accumulatedTimeSocBucketWeightMax m183 : 40|7@1+ (1,0) [0|0] "" Vector__XXX
 SG_ BMS_a185_cyclingDcrGrowthNumOfCycles m185 : 40|12@1+ (1,0) [0|0] "" Vector__XXX
 SG_ BMS_a197_ovBrickV m197 : 40|16@1+ (7.6293945313e-05,0) [0|0] "" Vector__XXX
 SG_ BMS_a198_numBricksAbruptChanged m198 : 40|7@1+ (1,0) [0|0] "" Vector__XXX
 SG_ BMS_a030_faultThreshold m30 : 41|7@1+ (0.04,0) [0|0] "" Vector__XXX
 SG_ BMS_a025_minPowerError m25 : 42|9@1- (1,0) [0|0] "" Vector__XXX
 SG_ BMS_a151_isoNegativeR m151 : 42|10@1+ (10,0) [0|0] "" Vector__XXX
 SG_ BMS_a178_minPowerError m178 : 42|9@1- (1,0) [0|0] "" Vector__XXX
 SG_ BMS_a084_adcModuleError m84 : 43|1@1+ (1,0) [0|0] "" Vector__XXX
 SG_ BMS_a105_tSenseFailedModule4 m105 : 43|1@1+ (1,0) [0|0] "" Vector__XXX
 SG_ BMS_a056_minBrickVoltage m56 : 44|12@1+ (0.002,0) [0|0] "" Vector__XXX
 SG_ BMS_a062_maxBrickVId m62 : 44|7@1+ (1,1) [0|0] "" Vector__XXX
 SG_ BMS_a070_maxBrickVId m70 : 44|7@1+ (1,1) [0|0] "" Vector__XXX
 SG_ BMS_a084_balanceModuleError m84 : 44|1@1+ (1,0) [0|0] "" Vector__XXX
 SG_ BMS_a105_avgBrickTModule4 m105 : 44|8@1+ (0.5,0) [0|0] "" Vector__XXX
 SG_ BMS_a084_bsmModuleError m84 : 45|1@1+ (1,0) [0|0] "" Vector__XXX
 SG_ BMS_a035_passiveSideVNoR m35 : 46|9@1+ (1,0) [0|0] "" Vector__XXX
 SG_ BMS_a080_ctrId m80 : 46|1@1+ (1,0) [0|0] "" Vector__XXX
 SG_ BMS_a084_bmbModuleError m84 : 46|1@1+ (1,0) [0|0] "" Vector__XXX
 SG_ BMS_a115_rbIdealSoe m115 : 46|10@1+ (0.1,0) [0|0] "" Vector__XXX
 SG_ BMS_a152_passiveSideVNoR m152 : 46|9@1+ (1,0) [0|0] "" Vector__XXX
 SG_ BMS_a081_fourthBlockingAlertId m81 : 47|9@1+ (1,0) [0|0] "" Vector__XXX
 SG_ BMS_a082_fourthAlertId m82 : 47|9@1+ (1,0) [0|0] "" Vector__XXX
 SG_ BMS_a084_brickModuleError m84 : 47|1@1+ (1,0) [0|0] "" Vector__XXX
 SG_ BMS_a000_alertDataW2 m0 : 48|16@1+ (1,0) [0|0] "" Vector__XXX
 SG_ BMS_a020_unstableBrickVFilteredCounts m20 : 48|8@1+ (1,1) [0|0] "" Vector__XXX
 SG_ BMS_a026_deltaPackCurrentPrev m26 : 48|13@1+ (1,0) [0|0] "" Vector__XXX
 SG_ BMS_a030_numBricks m30 : 48|8@1+ (1,0) [0|0] "" Vector__XXX
 SG_ BMS_a039_maxBrickV m39 : 48|8@1+ (0.01,2) [0|0] "" Vector__XXX
 SG_ BMS_a042_data m42 : 48|1@1+ (1,0) [0|0] "" Vector__XXX
 SG_ BMS_a044_assertData2 m44 : 48|16@1+ (1,0) [0|0] "" Vector__XXX
 SG_ BMS_a054_verSupplyVMin m54 : 48|16@1+ (0.001,0) [0|0] "" Vector__XXX
 SG_ BMS_a057_tempDelta4 m57 : 48|7@1- (0.2,0) [0|0] "" Vector__XXX
 SG_ BMS_a058_tempDelta3 m58 : 48|7@1- (0.2,0) [0|0] "" Vector__XXX
 SG_ BMS_a061_finalBrickV m61 : 48|12@1+ (0.002,0) [0|0] "" Vector__XXX
 SG_ BMS_a064_avgBrickSOC m64 : 48|8@1+ (0.5,0) [0|0] "" Vector__XXX
 SG_ BMS_a066_maxBrickSoc m66 : 48|8@1+ (0.5,0) [0|0] "" Vector__XXX
 SG_ BMS_a069_minBrickVLimit m69 : 48|8@1+ (0.01,2) [0|0] "" Vector__XXX
 SG_ BMS_a077_packCurrent m77 : 48|8@1+ (8,-1496) [0|0] "" Vector__XXX
 SG_ BMS_a084_chargeModuleError m84 : 48|1@1+ (1,0) [0|0] "" Vector__XXX
 SG_ BMS_a110_synchronizedCacAvg m110 : 48|12@1+ (0.1,0) [0|0] "" Vector__XXX
 SG_ BMS_a111_socByOcvStart m111 : 48|8@1+ (0.5,0) [0|0] "" Vector__XXX
 SG_ BMS_a112_newLifeModelBrickCapacity m112 : 48|12@1+ (0.1,0) [0|0] "" Vector__XXX
 SG_ BMS_a117_dSocAlpha m117 : 48|12@1+ (0.0030517578125,-12.4969482421875) [0|0] "" Vector__XXX
 SG_ BMS_a122_maxRawThermistorTemp m122 : 48|8@1+ (0.5,-40) [0|0] "" Vector__XXX
 SG_ BMS_a130_errorValue2 m130 : 48|16@1+ (1,0) [0|0] "" Vector__XXX
 SG_ BMS_a134_maxBrickT m134 : 48|5@1+ (3,-25) [0|0] "" Vector__XXX
 SG_ BMS_a137_uvBrickV m137 : 48|16@1+ (7.6293945313e-05,0) [0|0] "" Vector__XXX
 SG_ BMS_a138_ovBrickV m138 : 48|16@1+ (7.6293945313e-05,0) [0|0] "" Vector__XXX
 SG_ BMS_a143_cacChangeBrickID m143 : 48|7@1+ (1,1) [0|0] "" Vector__XXX
 SG_ BMS_a144_BMS_minor_version m144 : 48|16@1+ (1,0) [0|0] "" Vector__XXX
 SG_ BMS_a145_brickChangeHystRatio m145 : 48|10@1+ (0.001,0) [0|0] "" Vector__XXX
 SG_ BMS_a146_uvBrickV m146 : 48|16@1+ (7.6293945313e-05,0) [0|0] "" Vector__XXX
 SG_ BMS_a147_numBricksHighSocAhError m147 : 48|7@1+ (1,0) [0|0] "" Vector__XXX
 SG_ BMS_a157_nvramDataCounter m157 : 48|16@1+ (1,0) [0|0] "" Vector__XXX
 SG_ BMS_a162_socThreshold m162 : 48|16@1+ (1,0) [0|0] "" Vector__XXX
 SG_ BMS_a171_stackId m171 : 48|8@1+ (1,1) [0|0] "" Vector__XXX
 SG_ BMS_a182_accumulatedTimeSocBucketWeightMax m182 : 48|7@1+ (1,0) [0|0] "" Vector__XXX
 SG_ BMS_a183_socBucketWeightAboveThresholdCount m183 : 48|5@1+ (1,0) [0|0] "" Vector__XXX
 SG_ BMS_a184_accumulatedEnergyTempBucketWeightMax m184 : 48|7@1+ (1,0) [0|0] "" Vector__XXX
 SG_ BMS_a196_packUnderVoltageDelta m196 : 48|16@1- (0.01,0) [0|0] "" Vector__XXX
 SG_ BMS_a198_brickAbruptChangeHystRatio m198 : 48|10@1+ (0.001,0) [0|0] "" Vector__XXX
 SG_ BMS_a042_master m42 : 49|4@1+ (1,0) [0|0] "" Vector__XXX
 SG_ BMS_a084_chargeStateModuleError m84 : 49|1@1+ (1,0) [0|0] "" Vector__XXX
 SG_ BMS_a084_contactorsModuleError m84 : 50|1@1+ (1,0) [0|0] "" Vector__XXX
 SG_ BMS_a025_maxPowerError m25 : 51|9@1- (1,0) [0|0] "" Vector__XXX
 SG_ BMS_a062_maxBrickVoltage m62 : 51|12@1+ (0.002,0) [0|0] "" Vector__XXX
 SG_ BMS_a070_maxBrickVoltage m70 : 51|12@1+ (0.002,0) [0|0] "" Vector__XXX
 SG_ BMS_a084_driveLimitsModuleError m84 : 51|1@1+ (1,0) [0|0] "" Vector__XXX
 SG_ BMS_a167_fcLinkNegativeV m167 : 51|11@1- (0.5,0) [0|0] "" Vector__XXX
 SG_ BMS_a168_fcLinkNegativeV m168 : 51|11@1- (0.5,0) [0|0] "" Vector__XXX
 SG_ BMS_a178_maxPowerError m178 : 51|9@1- (1,0) [0|0] "" Vector__XXX
 SG_ BMS_a084_energyModuleError m84 : 52|1@1+ (1,0) [0|0] "" Vector__XXX
 SG_ BMS_a105_inletTemp m105 : 52|8@1+ (0.5,0) [0|0] "" Vector__XXX
 SG_ BMS_a155_shortImpedance m155 : 52|10@1+ (1,0) [0|0] "" Vector__XXX
 SG_ BMS_a165_dcLinkNegativeV m165 : 52|12@1- (0.25,0) [0|0] "" Vector__XXX
 SG_ BMS_a166_dcLinkNegativeV m166 : 52|12@1- (0.25,0) [0|0] "" Vector__XXX
 SG_ BMS_a185_accumulatedEnergyTempBucketWeightMax m185 : 52|7@1+ (1,0) [0|0] "" Vector__XXX
 SG_ BMS_a042_supervisor m42 : 53|1@1+ (1,0) [0|0] "" Vector__XXX
 SG_ BMS_a065_modCacImbalancePct m65 : 53|10@1+ (0.1,0) [0|0] "" Vector__XXX
 SG_ BMS_a067_modCacImbalancePct m67 : 53|10@1+ (0.1,0) [0|0] "" Vector__XXX
 SG_ BMS_a068_modCacImbalancePct m68 : 53|10@1+ (0.1,0) [0|0] "" Vector__XXX
 SG_ BMS_a072_moduleTerminal m72 : 53|2@1+ (1,0) [0|0] "" Vector__XXX
 SG_ BMS_a084_isolationModuleError m84 : 53|1@1+ (1,0) [0|0] "" Vector__XXX
 SG_ BMS_a042_write m42 : 54|1@1+ (1,0) [0|0] "" Vector__XXX
 SG_ BMS_a084_nvramModuleError m84 : 54|1@1+ (1,0) [0|0] "" Vector__XXX
 SG_ BMS_a035_passiveSideVWithR m35 : 55|9@1+ (1,0) [0|0] "" Vector__XXX
 SG_ BMS_a084_powerModuleError m84 : 55|1@1+ (1,0) [0|0] "" Vector__XXX
 SG_ BMS_a152_passiveSideVWithR m152 : 55|9@1+ (1,0) [0|0] "" Vector__XXX
 SG_ BMS_a024_packCurrent m24 : 56|8@1+ (8,-1500) [0|0] "" Vector__XXX
 SG_ BMS_a030_worstBrickSoc m30 : 56|8@1+ (0.5,0) [0|0] "" Vector__XXX
 SG_ BMS_a032_uvBrickId m32 : 56|7@1+ (1,1) [0|0] "" Vector__XXX
 SG_ BMS_a033_uvBrickId m33 : 56|7@1+ (1,1) [0|0] "" Vector__XXX
 SG_ BMS_a039_state m39 : 56|4@1+ (1,0) [0|0] "" Vector__XXX
 SG_ BMS_a043_vector m43 : 56|2@1+ (1,0) [0|0] "" Vector__XXX
 SG_ BMS_a056_standbyEnabled m56 : 56|1@1+ (1,0) [0|0] "" Vector__XXX
 SG_ BMS_a058_tempDelta4 m58 : 56|7@1- (0.2,0) [0|0] "" Vector__XXX
 SG_ BMS_a066_avgBrickSoc m66 : 56|8@1+ (0.5,0) [0|0] "" Vector__XXX
 SG_ BMS_a069_minBrickV m69 : 56|8@1+ (0.01,2) [0|0] "" Vector__XXX
 SG_ BMS_a081_totalAlertCount m81 : 56|8@1+ (1,0) [0|0] "" Vector__XXX
 SG_ BMS_a082_totalAlertCount m82 : 56|8@1+ (1,0) [0|0] "" Vector__XXX
 SG_ BMS_a084_selfTestModuleError m84 : 56|1@1+ (1,0) [0|0] "" Vector__XXX
 SG_ BMS_a111_socByOcvEnd m111 : 56|8@1+ (0.5,0) [0|0] "" Vector__XXX
 SG_ BMS_a115_resetReason m115 : 56|2@1+ (1,0) [0|0] "" Vector__XXX
 SG_ BMS_a122_numValidThermistors m122 : 56|5@1+ (1,0) [0|0] "" Vector__XXX
 SG_ BMS_a123_packMinus m123 : 56|8@1- (4,0) [0|0] "" Vector__XXX
 SG_ BMS_a143_cacUpdateError m143 : 56|8@1+ (0.1,0) [0|0] "" Vector__XXX
 SG_ BMS_a182_socBucketWeightAboveThresholdCount m182 : 56|4@1+ (1,0) [0|0] "" Vector__XXX
 SG_ BMS_a184_socBucketWeightAboveThresholdCount m184 : 56|4@1+ (1,0) [0|0] "" Vector__XXX
 SG_ BMS_a197_ovBrickVIndex m197 : 56|7@1+ (1,1) [0|0] "" Vector__XXX
 SG_ BMS_a056_standbySwGood m56 : 57|1@1+ (1,0) [0|0] "" Vector__XXX
 SG_ BMS_a084_sensorModuleError m84 : 57|1@1+ (1,0) [0|0] "" Vector__XXX
 SG_ BMS_a043_starvedTaskID m43 : 58|3@1+ (1,0) [0|0] "" Vector__XXX
 SG_ BMS_a056_ssOutTooHigh m56 : 58|1@1+ (1,0) [0|0] "" Vector__XXX
 SG_ BMS_a084_shuntModuleError m84 : 58|1@1+ (1,0) [0|0] "" Vector__XXX
 SG_ BMS_a056_ssOutTooLow m56 : 59|1@1+ (1,0) [0|0] "" Vector__XXX
 SG_ BMS_a084_sleepModuleError m84 : 59|1@1+ (1,0) [0|0] "" Vector__XXX
 SG_ BMS_a185_socBucketWeightAboveThresholdCount m185 : 59|4@1+ (1,0) [0|0] "" Vector__XXX
 SG_ BMS_a025_diMiaCount m25 : 60|2@1+ (1,0) [0|0] "" Vector__XXX
 SG_ BMS_a056_ssStuckOn m56 : 60|1@1+ (1,0) [0|0] "" Vector__XXX
 SG_ BMS_a061_transitionFromSleep m61 : 60|1@1+ (1,0) [0|0] "" Vector__XXX
 SG_ BMS_a084_thermalModuleError m84 : 60|1@1+ (1,0) [0|0] "" Vector__XXX
 SG_ BMS_a112_discontinuityOnInit m112 : 60|1@1+ (1,0) [0|0] "" Vector__XXX
 SG_ BMS_a178_diMiaCount m178 : 60|2@1+ (1,0) [0|0] "" Vector__XXX
 SG_ BMS_a056_ssStuckOff m56 : 61|1@1+ (1,0) [0|0] "" Vector__XXX
 SG_ BMS_a061_brickVsAreClean m61 : 61|1@1+ (1,0) [0|0] "" Vector__XXX
 SG_ BMS_a084_udsModuleError m84 : 61|1@1+ (1,0) [0|0] "" Vector__XXX
 SG_ BMS_a025_diSnaCount m25 : 62|2@1+ (1,0) [0|0] "" Vector__XXX
 SG_ BMS_a061_bmbTestModeActive m61 : 62|1@1+ (1,0) [0|0] "" Vector__XXX
 SG_ BMS_a084_vmModuleError m84 : 62|1@1+ (1,0) [0|0] "" Vector__XXX
 SG_ BMS_a178_diSnaCount m178 : 62|2@1+ (1,0) [0|0] "" Vector__XXX
 SG_ BMS_a061_brickVSubstitutionOccurred m61 : 63|1@1+ (1,0) [0|0] "" Vector__XXX

BO_ 1344 SCCM_alertLog: 8 Vector__XXX
 SG_ SCCM_alertID M : 0|15@1+ (1,0) [0|0] "" Vector__XXX
 SG_ SCCM_alertState : 15|1@1+ (1,0) [0|0] "" Vector__XXX
 SG_ SCCM_a003_debouncePosition m3 : 16|8@1+ (1,0) [0|0] "" Vector__XXX
 SG_ SCCM_a004_debouncePosition m4 : 16|8@1+ (1,0) [0|0] "" Vector__XXX
 SG_ SCCM_a005_debouncePosition m5 : 16|8@1+ (1,0) [0|0] "" Vector__XXX
 SG_ SCCM_a006_debouncePosition m6 : 16|8@1+ (1,0) [0|0] "" Vector__XXX
 SG_ SCCM_a007_debouncePosition m7 : 16|8@1+ (1,0) [0|0] "" Vector__XXX
 SG_ SCCM_a008_debouncePosition m8 : 16|8@1+ (1,0) [0|0] "" Vector__XXX
 SG_ SCCM_a009_debouncePosition m9 : 16|8@1+ (1,0) [0|0] "" Vector__XXX
 SG_ SCCM_a010_debouncePosition m10 : 16|8@1+ (1,0) [0|0] "" Vector__XXX
 SG_ SCCM_a011_debouncePosition m11 : 16|8@1+ (1,0) [0|0] "" Vector__XXX
 SG_ SCCM_a012_debouncePosition m12 : 16|8@1+ (1,0) [0|0] "" Vector__XXX
 SG_ SCCM_a013_voltage m13 : 16|8@1+ (1,0) [0|0] "" Vector__XXX
 SG_ SCCM_a014_voltage m14 : 16|8@1+ (1,0) [0|0] "" Vector__XXX
 SG_ SCCM_a015_intMainIndex m15 : 16|8@1+ (1,0) [0|0] "" Vector__XXX
 SG_ SCCM_a016_mainAdcTest m16 : 16|4@1+ (1,0) [0|0] "" Vector__XXX
 SG_ SCCM_a017_mainRamTest m17 : 16|4@1+ (1,0) [0|0] "" Vector__XXX
 SG_ SCCM_a018_internalSASState m18 : 16|8@1+ (1,0) [0|0] "" Vector__XXX
 SG_ SCCM_a019_internalSASState m19 : 16|8@1+ (1,0) [0|0] "" Vector__XXX
 SG_ SCCM_a020_internalSASState m20 : 16|8@1+ (1,0) [0|0] "" Vector__XXX
 SG_ SCCM_a021_adcValue1 m21 : 16|8@1+ (1,0) [0|0] "" Vector__XXX
 SG_ SCCM_a022_adcValue1 m22 : 16|8@1+ (1,0) [0|0] "" Vector__XXX
 SG_ SCCM_a023_adcValue1 m23 : 16|8@1+ (1,0) [0|0] "" Vector__XXX
 SG_ SCCM_a024_adcValue1 m24 : 16|8@1+ (1,0) [0|0] "" Vector__XXX
 SG_ SCCM_a025_taskState m25 : 16|16@1+ (1,0) [0|0] "" Vector__XXX
 SG_ SCCM_a026_debouncePosition m26 : 16|8@1+ (1,0) [0|0] "" Vector__XXX
 SG_ SCCM_a027_debouncePosition m27 : 16|8@1+ (1,0) [0|0] "" Vector__XXX
 SG_ SCCM_a028_debouncePosition m28 : 16|8@1+ (1,0) [0|0] "" Vector__XXX
 SG_ SCCM_a029_debouncePosition m29 : 16|8@1+ (1,0) [0|0] "" Vector__XXX
 SG_ SCCM_a016_mainCpuTest m16 : 20|4@1+ (1,0) [0|0] "" Vector__XXX
 SG_ SCCM_a017_mainRomTest m17 : 20|4@1+ (1,0) [0|0] "" Vector__XXX
 SG_ SCCM_a003_rawPosition m3 : 24|8@1+ (1,0) [0|0] "" Vector__XXX
 SG_ SCCM_a004_rawPosition m4 : 24|8@1+ (1,0) [0|0] "" Vector__XXX
 SG_ SCCM_a005_rawPosition m5 : 24|8@1+ (1,0) [0|0] "" Vector__XXX
 SG_ SCCM_a006_rawPosition m6 : 24|8@1+ (1,0) [0|0] "" Vector__XXX
 SG_ SCCM_a007_rawPosition m7 : 24|8@1+ (1,0) [0|0] "" Vector__XXX
 SG_ SCCM_a008_rawPosition m8 : 24|8@1+ (1,0) [0|0] "" Vector__XXX
 SG_ SCCM_a009_rawPosition m9 : 24|8@1+ (1,0) [0|0] "" Vector__XXX
 SG_ SCCM_a010_rawPosition m10 : 24|8@1+ (1,0) [0|0] "" Vector__XXX
 SG_ SCCM_a011_rawPosition m11 : 24|8@1+ (1,0) [0|0] "" Vector__XXX
 SG_ SCCM_a012_rawPosition m12 : 24|8@1+ (1,0) [0|0] "" Vector__XXX
 SG_ SCCM_a015_intSubIndex m15 : 24|8@1+ (1,0) [0|0] "" Vector__XXX
 SG_ SCCM_a016_wdtTest m16 : 24|4@1+ (1,0) [0|0] "" Vector__XXX
 SG_ SCCM_a017_stackHardLimitTest m17 : 24|4@1+ (1,0) [0|0] "" Vector__XXX
 SG_ SCCM_a021_adcValue2 m21 : 24|8@1+ (1,0) [0|0] "" Vector__XXX
 SG_ SCCM_a022_adcValue2 m22 : 24|8@1+ (1,0) [0|0] "" Vector__XXX
 SG_ SCCM_a023_adcValue2 m23 : 24|8@1+ (1,0) [0|0] "" Vector__XXX
 SG_ SCCM_a024_adcValue2 m24 : 24|8@1+ (1,0) [0|0] "" Vector__XXX
 SG_ SCCM_a026_rawPosition m26 : 24|8@1+ (1,0) [0|0] "" Vector__XXX
 SG_ SCCM_a027_rawPosition m27 : 24|8@1+ (1,0) [0|0] "" Vector__XXX
 SG_ SCCM_a028_rawPosition m28 : 24|8@1+ (1,0) [0|0] "" Vector__XXX
 SG_ SCCM_a029_rawPosition m29 : 24|8@1+ (1,0) [0|0] "" Vector__XXX
 SG_ SCCM_a016_subCpuTest m16 : 28|4@1+ (1,0) [0|0] "" Vector__XXX
 SG_ SCCM_a017_mainDataFlashTest m17 : 28|4@1+ (1,0) [0|0] "" Vector__XXX
 SG_ SCCM_a003_errorPosition m3 : 32|8@1+ (1,0) [0|0] "" Vector__XXX
 SG_ SCCM_a004_errorPosition m4 : 32|8@1+ (1,0) [0|0] "" Vector__XXX
 SG_ SCCM_a005_errorPosition m5 : 32|8@1+ (1,0) [0|0] "" Vector__XXX
 SG_ SCCM_a006_errorPosition m6 : 32|8@1+ (1,0) [0|0] "" Vector__XXX
 SG_ SCCM_a007_errorPosition m7 : 32|8@1+ (1,0) [0|0] "" Vector__XXX
 SG_ SCCM_a008_errorPosition m8 : 32|8@1+ (1,0) [0|0] "" Vector__XXX
 SG_ SCCM_a009_errorPosition m9 : 32|8@1+ (1,0) [0|0] "" Vector__XXX
 SG_ SCCM_a010_errorPosition m10 : 32|8@1+ (1,0) [0|0] "" Vector__XXX
 SG_ SCCM_a011_errorPosition m11 : 32|8@1+ (1,0) [0|0] "" Vector__XXX
 SG_ SCCM_a012_errorPosition m12 : 32|8@1+ (1,0) [0|0] "" Vector__XXX
 SG_ SCCM_a015_intMemIndex m15 : 32|8@1+ (1,0) [0|0] "" Vector__XXX
 SG_ SCCM_a016_subAdcTest m16 : 32|4@1+ (1,0) [0|0] "" Vector__XXX
 SG_ SCCM_a017_subRamTest m17 : 32|4@1+ (1,0) [0|0] "" Vector__XXX
 SG_ SCCM_a021_adcValue3 m21 : 32|8@1+ (1,0) [0|0] "" Vector__XXX
 SG_ SCCM_a022_adcValue3 m22 : 32|8@1+ (1,0) [0|0] "" Vector__XXX
 SG_ SCCM_a023_adcValue3 m23 : 32|8@1+ (1,0) [0|0] "" Vector__XXX
 SG_ SCCM_a024_adcValue3 m24 : 32|8@1+ (1,0) [0|0] "" Vector__XXX
 SG_ SCCM_a026_errorPosition m26 : 32|8@1+ (1,0) [0|0] "" Vector__XXX
 SG_ SCCM_a027_errorPosition m27 : 32|8@1+ (1,0) [0|0] "" Vector__XXX
 SG_ SCCM_a028_errorPosition m28 : 32|8@1+ (1,0) [0|0] "" Vector__XXX
 SG_ SCCM_a029_errorPosition m29 : 32|8@1+ (1,0) [0|0] "" Vector__XXX
 SG_ SCCM_a017_subRomTest m17 : 36|4@1+ (1,0) [0|0] "" Vector__XXX
 SG_ SCCM_a003_adcValue m3 : 40|8@1+ (1,0) [0|0] "" Vector__XXX
 SG_ SCCM_a004_adcValue m4 : 40|8@1+ (1,0) [0|0] "" Vector__XXX
 SG_ SCCM_a005_adcValue m5 : 40|8@1+ (1,0) [0|0] "" Vector__XXX
 SG_ SCCM_a006_adcValue m6 : 40|8@1+ (1,0) [0|0] "" Vector__XXX
 SG_ SCCM_a007_adcValue1 m7 : 40|8@1+ (1,0) [0|0] "" Vector__XXX
 SG_ SCCM_a008_adcValue1 m8 : 40|8@1+ (1,0) [0|0] "" Vector__XXX
 SG_ SCCM_a009_adcValue1 m9 : 40|8@1+ (1,0) [0|0] "" Vector__XXX
 SG_ SCCM_a010_adcValue1 m10 : 40|8@1+ (1,0) [0|0] "" Vector__XXX
 SG_ SCCM_a011_adcValue1 m11 : 40|8@1+ (1,0) [0|0] "" Vector__XXX
 SG_ SCCM_a012_adcValue1 m12 : 40|8@1+ (1,0) [0|0] "" Vector__XXX
 SG_ SCCM_a017_subStackHardLimitTest m17 : 40|4@1+ (1,0) [0|0] "" Vector__XXX
 SG_ SCCM_a021_adcValue4 m21 : 40|8@1+ (1,0) [0|0] "" Vector__XXX
 SG_ SCCM_a022_adcValue4 m22 : 40|8@1+ (1,0) [0|0] "" Vector__XXX
 SG_ SCCM_a023_adcValue4 m23 : 40|8@1+ (1,0) [0|0] "" Vector__XXX
 SG_ SCCM_a024_adcValue4 m24 : 40|8@1+ (1,0) [0|0] "" Vector__XXX
 SG_ SCCM_a026_adcValue1 m26 : 40|8@1+ (1,0) [0|0] "" Vector__XXX
 SG_ SCCM_a027_adcValue1 m27 : 40|8@1+ (1,0) [0|0] "" Vector__XXX
 SG_ SCCM_a028_adcValue1 m28 : 40|8@1+ (1,0) [0|0] "" Vector__XXX
 SG_ SCCM_a029_adcValue1 m29 : 40|8@1+ (1,0) [0|0] "" Vector__XXX
 SG_ SCCM_a017_svError m17 : 44|16@1+ (1,0) [0|0] "" Vector__XXX
 SG_ SCCM_a007_adcValue2 m7 : 48|8@1+ (1,0) [0|0] "" Vector__XXX
 SG_ SCCM_a008_adcValue2 m8 : 48|8@1+ (1,0) [0|0] "" Vector__XXX
 SG_ SCCM_a009_adcValue2 m9 : 48|8@1+ (1,0) [0|0] "" Vector__XXX
 SG_ SCCM_a010_adcValue2 m10 : 48|8@1+ (1,0) [0|0] "" Vector__XXX
 SG_ SCCM_a011_adcValue2 m11 : 48|8@1+ (1,0) [0|0] "" Vector__XXX
 SG_ SCCM_a012_adcValue2 m12 : 48|8@1+ (1,0) [0|0] "" Vector__XXX
 SG_ SCCM_a021_adcValue5 m21 : 48|8@1+ (1,0) [0|0] "" Vector__XXX
 SG_ SCCM_a022_adcValue5 m22 : 48|8@1+ (1,0) [0|0] "" Vector__XXX
 SG_ SCCM_a023_adcValue5 m23 : 48|8@1+ (1,0) [0|0] "" Vector__XXX
 SG_ SCCM_a024_adcValue5 m24 : 48|8@1+ (1,0) [0|0] "" Vector__XXX
 SG_ SCCM_a026_adcValue2 m26 : 48|8@1+ (1,0) [0|0] "" Vector__XXX
 SG_ SCCM_a027_adcValue2 m27 : 48|8@1+ (1,0) [0|0] "" Vector__XXX
 SG_ SCCM_a028_adcValue2 m28 : 48|8@1+ (1,0) [0|0] "" Vector__XXX
 SG_ SCCM_a029_adcValue2 m29 : 48|8@1+ (1,0) [0|0] "" Vector__XXX
 SG_ SCCM_a021_adcValue6 m21 : 56|8@1+ (1,0) [0|0] "" Vector__XXX
 SG_ SCCM_a022_adcValue6 m22 : 56|8@1+ (1,0) [0|0] "" Vector__XXX
 SG_ SCCM_a023_adcValue6 m23 : 56|8@1+ (1,0) [0|0] "" Vector__XXX
 SG_ SCCM_a024_adcValue6 m24 : 56|8@1+ (1,0) [0|0] "" Vector__XXX

BO_ 1345 FC_maxLimits: 8 Vector__XXX
 SG_ FC_maxPowerLimit : 0|13@1+ (0.062255859376,0) [0|0] "" Vector__XXX
 SG_ FC_maxCurrentLimit : 16|13@1+ (0.0732421875,0) [0|0] "" Vector__XXX

BO_ 1346 TAS_controlData0: 8 Vector__XXX
 SG_ TAS_feedbackVelocityError_FL : 0|8@1- (0.02,0) [0|0] "" Vector__XXX
 SG_ TAS_feedbackVelocityError_FR : 8|8@1- (0.02,0) [0|0] "" Vector__XXX
 SG_ TAS_feedbackVelocityError_RL : 16|8@1- (0.02,0) [0|0] "" Vector__XXX
 SG_ TAS_feedbackVelocityError_RR : 24|8@1- (0.02,0) [0|0] "" Vector__XXX
 SG_ TAS_feedbackVelocityErrorDelta : 32|8@1- (0.02,0) [0|0] "" Vector__XXX
 SG_ TAS_accelMagFiltered : 40|8@1+ (0.06,0) [0|0] "" Vector__XXX
 SG_ TAS_calConfig : 48|2@1+ (1,0) [0|0] "" Vector__XXX

VAL_ 1339 VCBATT1_alertID 0 "ALERT_DO_NOT_USE_ZERO" 1 "a001_DriverDoorOpen" 2 "a002_DoorOpen" 3 "a003_TrunkOpen" 4 "a004_FrunkOpen" 5 "a005_HeadlightsOnDoorOpen" 6 "a006_RemoteServiceAlert" 7 "a007_SoftPackConfigMismatch" 8 "a008_TouchScreenError" 9 "a009_SquashfsError" 10 "a010_MapsMissing" 11 "a011_IncorrectMap" 12 "a012_NotOnPrivateProperty" 13 "a013_TPMSHardWarning" 14 "a014_TPMSSoftWarning" 15 "a015_TPMSOverPressureWarning" 16 "a016_TPMSTemperatureWarning" 17 "a017_TPMSSystemFault" 18 "a018_SlipStartOn" 19 "a019_ParkBrakeFault" 20 "a020_SteeringReduced" 21 "a021_RearSeatbeltUnbuckled" 22 "a022_ApeFusesEtc" 23 "a023_CellInternetCheckFailed" 24 "a024_WifiInternetCheckFailed" 25 "a025_WifiOnlineCheckFailed" 26 "a026_ModemResetLoopDetected" 27 "a027_AutoSteerMIA" 28 "a028_FrontTrunkPopupClosed" 29 "a029_ModemMIA" 30 "a030_ModemVMCrash" 31 "a031_BrakeFluidLow" 32 "a032_CellModemRecoveryResets" 33 "a033_ApTrialExpired" 34 "a034_WakeupProblem" 35 "a035_AudioWatchdogKernelError" 36 "a036_AudioWatchdogHfpError" 37 "a037_AudioWatchdogXrunStormError" 38 "a038_AudioWatchdogA2bI2cLockupError" 39 "a039_AudioA2bNeedRediscovery" 40 "a040_HomelinkTransmit" 41 "a041_AudioDmesgXrun" 42 "a042_AudioDmesgRtThrottling" 43 "a043_InvalidMapDataOverride" 44 "a044_AudioDmesgDspException" 45 "a045_ECallNeedsService" 46 "a046_BackupCameraStreamError" 47 "a047_CellRoamingDisallowed" 48 "a048_AudioPremiumAmpCheckFailed" 49 "a049_BrakeShiftRequired" 50 "a050_BackupCameraIPUTimeout" 51 "a051_BackupCameraFrameTimeout" 52 "a052_KernelPanicReported" 53 "a053_QtCarExitError" 54 "a054_AudioBoostPowerBad" 55 "a055_ManualECallDisabled" 56 "a056_ManualECallButtonDisconnected" 57 "a057_CellAntennaDisconnected" 58 "a058_GPSAntennaDisconnected" 59 "a059_ECallSpeakerDisconnected" 60 "a060_ECallMicDisconnected" 61 "a061_SIMTestFailed" 62 "a062_ENSTestFailed" 63 "a063_CellularTestFailed" 64 "a064_ModemFirmwareTestFailed" 65 "a065_WiFiRecoveryReset" 66 "a066_GpuHangDetected" 67 "a067_WarnOnI915" 68 "a068_VideoUnexpectedExit" 69 "a069_VideoUDPTimeout" 70 "a070_VideoPipelineWarning" 71 "a071_VideoPipelineError" 72 "a072_ECallAnalogMicFailed" 73 "a073_ECallDigitalMicFailed" 74 "a074_EMMCHangDetected" 75 "a075_BackupCameraInitError" 76 "a076_NumFalseManualECalls" 77 "a077_AudioA2bMicChannelSwap" 78 "a078_DashcamUsbDriveUnmountable" 79 "a079_DashcamUsbDriveFull" 80 "a080_DashcamUsbDriveSlow" 81 "a081_CellModemSearchExpired" 82 "a082_NumModemRebootStuckInECall" 83 "a083_ECallProxyWatchdogTriggered" 84 "a084_SerializerError" 85 "a085_DeserializerError" 86 "a086_TouchEnumerationError" 87 "a087_BmpReset" 88 "a088_CellRemovableSimMissing" 89 "a089_RadioSoftResetError" 90 "a090_RadioPingFailError" 91 "a091_VehicleLinkStall" 92 "a092_updateStarted" 93 "a093_updateEnded" 94 "a094_ModemPowerOnFailure" 95 "a095_CidStorageRunningLow" 96 "a096_VideodPipelineIssueDetected" 97 "a097_AudiodRestarted" 98 "a098_DiskCheckFailure" 99 "a099_eMMCStatusError" 100 "a100_eMMCFTLError" 101 "a101_wifiStackProblem" 102 "a102_A2bDiscoveryFailed" 103 "a103_UsbHubNotEnumerating" 104 "a104_DashcamUsbDriveMissing" 105 "a105_firmwareReinstallRequested" 106 "a106_rebootBackstopTriggered" 107 "a107_DashcamUsbDriveTooBigForVfatFsck" 108 "a108_DashcamUsbDriveGettingFull" 109 "a109_DashcamUsbDriveTooSmall" 110 "a110_DashcamUsbDriveCorrupt" 111 "a111_DashcamUsbDriveWrongPort" 112 "a112_badUSBDevice" 113 "a113_DashcamHasOnboardSentryClips" ;
VAL_ 1339 VCBATT1_alertState 0 "CLEARED" 1 "SET" ;
VAL_ 1339 VCBATT1_a031_uds_bytes_0 0 "0" 1 "1" 2 "2" 3 "3" 4 "4" 5 "5" 6 "6" 7 "7" 8 "8" 9 "9" 10 "10" 11 "11" 12 "12" 13 "13" 14 "14" 15 "15" 16 "16" 17 "17" 18 "18" 19 "19" 20 "20" 21 "21" 22 "22" 23 "23" 24 "24" 25 "25" 26 "26" 27 "27" 28 "28" 29 "29" 30 "30" 31 "31" ;
VAL_ 1339 VCBATT1_a096_FRONTIPC_status 0 "DISABLED" 1 "ENABLED" 2 "TEMPORARY_FAILURE" 3 "SNA" ;
VAL_ 1339 VCBATT1_a108_FRONTIPC_status 0 "DISABLED" 1 "ENABLED" 2 "TEMPORARY_FAILURE" 3 "SNA" ;
VAL_ 1339 VCBATT1_a122_FRONTIPC_status 0 "DISABLED" 1 "ENABLED" 2 "TEMPORARY_FAILURE" 3 "SNA" ;
VAL_ 1339 VCBATT1_a124_FRONTIPC_status 0 "DISABLED" 1 "ENABLED" 2 "TEMPORARY_FAILURE" 3 "SNA" ;
VAL_ 1339 VCBATT1_a144_FRONTIPC_status 0 "DISABLED" 1 "ENABLED" 2 "TEMPORARY_FAILURE" 3 "SNA" ;
VAL_ 1339 VCBATT1_a180_vehiclePowerState 0 "OFF" 1 "CONDITIONING" 2 "ACCESSORY" 3 "DRIVE" ;
VAL_ 1339 VCBATT1_a191_vehiclePowerState 0 "OFF" 1 "CONDITIONING" 2 "ACCESSORY" 3 "DRIVE" ;
VAL_ 1339 VCBATT1_a196_factoryMode 0 "DISABLED" 1 "ENABLED" ;
VAL_ 1339 VCBATT1_a220_DI_gear 0 "INVALID" 1 "P" 2 "R" 3 "N" 4 "D" 7 "SNA" ;
VAL_ 1339 VCBATT1_a252_IBSVoltage 4095 "SNA" ;
VAL_ 1339 VCBATT1_a259_serviceMode 0 "DISABLED" 1 "ENABLED" ;
VAL_ 1339 VCBATT1_a446_cell1Voltage 65535 "SNA" ;
VAL_ 1339 VCBATT1_a477_cell1Voltage 65535 "SNA" ;
VAL_ 1339 VCBATT1_a497_serviceMode 0 "DISABLED" 1 "ENABLED" ;
VAL_ 1339 VCBATT1_a510_sumCellVoltage 65534 "INVALID" 65535 "SNA" ;
VAL_ 1339 VCBATT1_a513_packCurrent 4294934528 "SNA" ;
VAL_ 1339 VCBATT1_a514_cell1Voltage 65535 "SNA" ;
VAL_ 1339 VCBATT1_a515_cell1Voltage 65535 "SNA" ;
VAL_ 1339 VCBATT1_a518_packVoltage 65535 "SNA" ;
VAL_ 1339 VCBATT1_a525_GTW_twelveVBatteryType 0 "ATLASBX_B24_FLOODED" 1 "CLARIOS_B24_FLOODED" ;
VAL_ 1339 VCBATT1_a527_cell1Voltage 65535 "SNA" ;
VAL_ 1339 VCBATT1_a529_sumCellVoltage 65534 "INVALID" 65535 "SNA" ;
VAL_ 1339 VCBATT1_a544_serviceMode 0 "DISABLED" 1 "ENABLED" ;
VAL_ 1339 VCBATT1_a545_GTW_twelveVBatteryType 0 "ATLASBX_B24_FLOODED" 1 "CLARIOS_B24_FLOODED" ;
VAL_ 1339 VCBATT1_a548_vehiclePowerState 0 "OFF" 1 "CONDITIONING" 2 "ACCESSORY" 3 "DRIVE" ;
VAL_ 1339 VCBATT1_a555_cell1Voltage 65535 "SNA" ;
VAL_ 1339 VCBATT1_a556_factoryMode 0 "DISABLED" 1 "ENABLED" ;
VAL_ 1339 VCBATT1_a559_SOC 127 "SNA" ;
VAL_ 1339 VCBATT1_a582_batterySMState 0 "INIT" 1 "CHARGE" 2 "DISCHARGE" 3 "STANDBY" 4 "RESISTANCE_ESTIMATION" 5 "OTA_STANDBY" 6 "DISCONNECTED_BATTERY_TEST" 7 "SHORTED_CELL_TEST" 8 "FAULT" 9 "RECOVERY" ;
VAL_ 1339 VCBATT1_a587_factoryMode 0 "DISABLED" 1 "ENABLED" ;
VAL_ 1339 VCBATT1_a595_factoryMode 0 "DISABLED" 1 "ENABLED" ;
VAL_ 1339 VCBATT1_a599_GTW_twelveVBatteryType 0 "ATLASBX_B24_FLOODED" 1 "CLARIOS_B24_FLOODED" ;
VAL_ 1339 VCBATT1_a600_factoryMode 0 "DISABLED" 1 "ENABLED" ;
VAL_ 1339 VCBATT1_a670_packVoltage 65535 "SNA" ;
VAL_ 1339 VCBATT1_a090_FRONTIPC_state 0 "STANDBY" 1 "DRIVE" 2 "SUPPORT" 3 "CHARGE" 4 "FEIM" 5 "CLEAR_FAULT" 6 "FAULT" 7 "WELD" 8 "TEST" 9 "SNA" 10 "DIAG" ;
VAL_ 1339 VCBATT1_a091_FRONTIPC_state 0 "STANDBY" 1 "DRIVE" 2 "SUPPORT" 3 "CHARGE" 4 "FEIM" 5 "CLEAR_FAULT" 6 "FAULT" 7 "WELD" 8 "TEST" 9 "SNA" 10 "DIAG" ;
VAL_ 1339 VCBATT1_a103_FRONTIPC_status 0 "DISABLED" 1 "ENABLED" 2 "TEMPORARY_FAILURE" 3 "SNA" ;
VAL_ 1339 VCBATT1_a107_FRONTIPC_status 0 "DISABLED" 1 "ENABLED" 2 "TEMPORARY_FAILURE" 3 "SNA" ;
VAL_ 1339 VCBATT1_a111_FRONTIPC_status 0 "DISABLED" 1 "ENABLED" 2 "TEMPORARY_FAILURE" 3 "SNA" ;
VAL_ 1339 VCBATT1_a112_FRONTIPC_status 0 "DISABLED" 1 "ENABLED" 2 "TEMPORARY_FAILURE" 3 "SNA" ;
VAL_ 1339 VCBATT1_a124_BATTIPC_status 0 "DISABLED" 1 "ENABLED" 2 "TEMPORARY_FAILURE" 3 "SNA" ;
VAL_ 1339 VCBATT1_a144_BATTIPC_status 0 "DISABLED" 1 "ENABLED" 2 "TEMPORARY_FAILURE" 3 "SNA" ;
VAL_ 1339 VCBATT1_a196_serviceMode 0 "DISABLED" 1 "ENABLED" ;
VAL_ 1339 VCBATT1_a216_hvState 0 "DOWN" 1 "COMING_UP" 2 "GOING_DOWN" 3 "UP_FOR_DRIVE" 4 "UP_FOR_CHARGE" 5 "UP_FOR_DC_CHARGE" 6 "UP" ;
VAL_ 1339 VCBATT1_a479_ECPAState 0 "OPEN" 1 "CLOSED" 2 "INVALID" 3 "SNA" ;
VAL_ 1339 VCBATT1_a556_serviceMode 0 "DISABLED" 1 "ENABLED" ;
VAL_ 1339 VCBATT1_a587_serviceMode 0 "DISABLED" 1 "ENABLED" ;
VAL_ 1339 VCBATT1_a595_serviceMode 0 "DISABLED" 1 "ENABLED" ;
VAL_ 1339 VCBATT1_a600_serviceMode 0 "DISABLED" 1 "ENABLED" ;
VAL_ 1339 VCBATT1_a090_FRONTIPC_status 0 "DISABLED" 1 "ENABLED" 2 "TEMPORARY_FAILURE" 3 "SNA" ;
VAL_ 1339 VCBATT1_a111_BATTIPC_status 0 "DISABLED" 1 "ENABLED" 2 "TEMPORARY_FAILURE" 3 "SNA" ;
VAL_ 1339 VCBATT1_a112_BATTIPC_status 0 "DISABLED" 1 "ENABLED" 2 "TEMPORARY_FAILURE" 3 "SNA" ;
VAL_ 1339 VCBATT1_a120_FRONTIPC_systemStatus 0 "UNKNOWN" 1 "RELEASED" 2 "PARKED" 3 "DYNAMIC" 4 "PARKING" 5 "RELEASING" 6 "FAULT" 7 "FAULT_SECURE" 8 "MISMATCH" ;
VAL_ 1339 VCBATT1_a126_FRONTIPC_status 0 "DISABLED" 1 "ENABLED" 2 "TEMPORARY_FAILURE" 3 "SNA" ;
VAL_ 1339 VCBATT1_a180_hvState 0 "DOWN" 1 "COMING_UP" 2 "GOING_DOWN" 3 "UP_FOR_DRIVE" 4 "UP_FOR_CHARGE" 5 "UP_FOR_DC_CHARGE" 6 "UP" ;
VAL_ 1339 VCBATT1_a191_hvState 0 "DOWN" 1 "COMING_UP" 2 "GOING_DOWN" 3 "UP_FOR_DRIVE" 4 "UP_FOR_CHARGE" 5 "UP_FOR_DC_CHARGE" 6 "UP" ;
VAL_ 1339 VCBATT1_a196_transportMode 0 "DISABLED" 1 "ENABLED" ;
VAL_ 1339 VCBATT1_a496_MOSState 0 "OPEN" 1 "CLOSED" 2 "INVALID" 3 "SNA" ;
VAL_ 1339 VCBATT1_a556_transportMode 0 "DISABLED" 1 "ENABLED" ;
VAL_ 1339 VCBATT1_a587_transportMode 0 "DISABLED" 1 "ENABLED" ;
VAL_ 1339 VCBATT1_a595_transportMode 0 "DISABLED" 1 "ENABLED" ;
VAL_ 1339 VCBATT1_a600_transportMode 0 "DISABLED" 1 "ENABLED" ;
VAL_ 1339 VCBATT1_a617_FRONTIPC_status 0 "DISABLED" 1 "ENABLED" 2 "TEMPORARY_FAILURE" 3 "SNA" ;
VAL_ 1339 VCBATT1_a090_BATTIPC_state 0 "STANDBY" 1 "DRIVE" 2 "SUPPORT" 3 "CHARGE" 4 "FEIM" 5 "CLEAR_FAULT" 6 "FAULT" 7 "WELD" 8 "TEST" 9 "SNA" 10 "DIAG" ;
VAL_ 1339 VCBATT1_a107_BATTIPC_status 0 "DISABLED" 1 "ENABLED" 2 "TEMPORARY_FAILURE" 3 "SNA" ;
VAL_ 1339 VCBATT1_a120_BATTIPC_systemStatus 0 "UNKNOWN" 1 "RELEASED" 2 "PARKED" 3 "DYNAMIC" 4 "PARKING" 5 "RELEASING" 6 "FAULT" 7 "FAULT_SECURE" 8 "MISMATCH" ;
VAL_ 1339 VCBATT1_a126_BATTIPC_status 0 "DISABLED" 1 "ENABLED" 2 "TEMPORARY_FAILURE" 3 "SNA" ;
VAL_ 1339 VCBATT1_a479_factoryMode 0 "DISABLED" 1 "ENABLED" ;
VAL_ 1339 VCBATT1_a509_state 0 "STANDBY" 1 "DRIVE" 2 "SUPPORT" 3 "CHARGE" 4 "FEIM" 5 "CLEAR_FAULT" 6 "FAULT" 7 "WELD" 8 "TEST" 9 "SNA" 10 "DIAG" ;
VAL_ 1339 VCBATT1_a528_serviceMode 0 "DISABLED" 1 "ENABLED" ;
VAL_ 1339 VCBATT1_a617_BATTIPC_status 0 "DISABLED" 1 "ENABLED" 2 "TEMPORARY_FAILURE" 3 "SNA" ;
VAL_ 1339 VCBATT1_a113_BATTIPC_status 0 "DISABLED" 1 "ENABLED" 2 "TEMPORARY_FAILURE" 3 "SNA" ;
VAL_ 1339 VCBATT1_a196_vehiclePowerState 0 "OFF" 1 "CONDITIONING" 2 "ACCESSORY" 3 "DRIVE" ;
VAL_ 1339 VCBATT1_a220_vehicleSpeed 8191 "SNA" ;
VAL_ 1339 VCBATT1_a479_serviceMode 0 "DISABLED" 1 "ENABLED" ;
VAL_ 1339 VCBATT1_a496_serviceMode 0 "DISABLED" 1 "ENABLED" ;
VAL_ 1339 VCBATT1_a556_vehiclePowerState 0 "OFF" 1 "CONDITIONING" 2 "ACCESSORY" 3 "DRIVE" ;
VAL_ 1339 VCBATT1_a595_vehiclePowerState 0 "OFF" 1 "CONDITIONING" 2 "ACCESSORY" 3 "DRIVE" ;
VAL_ 1339 VCBATT1_a600_vehiclePowerState 0 "OFF" 1 "CONDITIONING" 2 "ACCESSORY" 3 "DRIVE" ;
VAL_ 1339 VCBATT1_a104_FRONTIPC_status 0 "DISABLED" 1 "ENABLED" 2 "TEMPORARY_FAILURE" 3 "SNA" ;
VAL_ 1339 VCBATT1_a116_FRONTIPC_status 0 "DISABLED" 1 "ENABLED" 2 "TEMPORARY_FAILURE" 3 "SNA" ;
VAL_ 1339 VCBATT1_a478_vehiclePowerState 0 "OFF" 1 "CONDITIONING" 2 "ACCESSORY" 3 "DRIVE" ;
VAL_ 1339 VCBATT1_a479_transportMode 0 "DISABLED" 1 "ENABLED" ;
VAL_ 1339 VCBATT1_a548_DI_gear 0 "INVALID" 1 "P" 2 "R" 3 "N" 4 "D" 7 "SNA" ;
VAL_ 1339 VCBATT1_a561_packTemperature 511 "SNA" ;
VAL_ 1339 VCBATT1_a562_packTemperature 511 "SNA" ;
VAL_ 1339 VCBATT1_a587_vehiclePowerState 0 "OFF" 1 "CONDITIONING" 2 "ACCESSORY" 3 "DRIVE" ;
VAL_ 1339 VCBATT1_a079_BATTIPC_systemStatus 0 "UNKNOWN" 1 "RELEASED" 2 "PARKED" 3 "DYNAMIC" 4 "PARKING" 5 "RELEASING" 6 "FAULT" 7 "FAULT_SECURE" 8 "MISMATCH" ;
VAL_ 1339 VCBATT1_a545_serviceMode 0 "DISABLED" 1 "ENABLED" ;
VAL_ 1339 VCBATT1_a079_FRONTIPC_systemStatus 0 "UNKNOWN" 1 "RELEASED" 2 "PARKED" 3 "DYNAMIC" 4 "PARKING" 5 "RELEASING" 6 "FAULT" 7 "FAULT_SECURE" 8 "MISMATCH" ;
VAL_ 1339 VCBATT1_a514_cell2Voltage 65535 "SNA" ;
VAL_ 1339 VCBATT1_a515_cell2Voltage 65535 "SNA" ;
VAL_ 1339 VCBATT1_a196_batterySMState 0 "INIT" 1 "CHARGE" 2 "DISCHARGE" 3 "STANDBY" 4 "RESISTANCE_ESTIMATION" 5 "OTA_STANDBY" 6 "DISCONNECTED_BATTERY_TEST" 7 "SHORTED_CELL_TEST" 8 "FAULT" 9 "RECOVERY" ;
VAL_ 1339 VCBATT1_a402_batterySMState 0 "INIT" 1 "CHARGE" 2 "DISCHARGE" 3 "STANDBY" 4 "RESISTANCE_ESTIMATION" 5 "OTA_STANDBY" 6 "DISCONNECTED_BATTERY_TEST" 7 "SHORTED_CELL_TEST" 8 "FAULT" 9 "RECOVERY" ;
VAL_ 1339 VCBATT1_a407_dcr12VThreshold 0 "OFF" 1 "40_MILLIOHMS" 2 "35_MILLIOHMS" 3 "30_MILLIOHMS" 4 "27_MILLIOHMS" 5 "24_MILLIOHMS" 6 "22_MILLIOHMS" 7 "20_MILLIOHMS" ;
VAL_ 1339 VCBATT1_a478_batterySMState 0 "INIT" 1 "CHARGE" 2 "DISCHARGE" 3 "STANDBY" 4 "RESISTANCE_ESTIMATION" 5 "OTA_STANDBY" 6 "DISCONNECTED_BATTERY_TEST" 7 "SHORTED_CELL_TEST" 8 "FAULT" 9 "RECOVERY" ;
VAL_ 1339 VCBATT1_a479_frunkLatchStatus 0 "SNA" 1 "OPENED" 2 "CLOSED" 3 "CLOSING" 4 "OPENING" 5 "AJAR" 6 "TIMEOUT" 7 "DEFAULT" 8 "FAULT" ;
VAL_ 1339 VCBATT1_a495_serviceMode 0 "DISABLED" 1 "ENABLED" ;
VAL_ 1339 VCBATT1_a497_SOC 127 "SNA" ;
VAL_ 1339 VCBATT1_a510_packVoltage 65535 "SNA" ;
VAL_ 1339 VCBATT1_a518_IBSVoltage 4095 "SNA" ;
VAL_ 1339 VCBATT1_a587_batterySMState 0 "INIT" 1 "CHARGE" 2 "DISCHARGE" 3 "STANDBY" 4 "RESISTANCE_ESTIMATION" 5 "OTA_STANDBY" 6 "DISCONNECTED_BATTERY_TEST" 7 "SHORTED_CELL_TEST" 8 "FAULT" 9 "RECOVERY" ;
VAL_ 1339 VCBATT1_a595_batterySMState 0 "INIT" 1 "CHARGE" 2 "DISCHARGE" 3 "STANDBY" 4 "RESISTANCE_ESTIMATION" 5 "OTA_STANDBY" 6 "DISCONNECTED_BATTERY_TEST" 7 "SHORTED_CELL_TEST" 8 "FAULT" 9 "RECOVERY" ;
VAL_ 1339 VCBATT1_a600_batterySMState 0 "INIT" 1 "CHARGE" 2 "DISCHARGE" 3 "STANDBY" 4 "RESISTANCE_ESTIMATION" 5 "OTA_STANDBY" 6 "DISCONNECTED_BATTERY_TEST" 7 "SHORTED_CELL_TEST" 8 "FAULT" 9 "RECOVERY" ;
VAL_ 1339 VCBATT1_a118_BATTIPC_status 0 "DISABLED" 1 "ENABLED" 2 "TEMPORARY_FAILURE" 3 "SNA" ;
VAL_ 1339 VCBATT1_a182_factoryMode 0 "DISABLED" 1 "ENABLED" ;
VAL_ 1339 VCBATT1_a183_factoryMode 0 "DISABLED" 1 "ENABLED" ;
VAL_ 1339 VCBATT1_a191_IBSVoltage 4095 "SNA" ;
VAL_ 1339 VCBATT1_a446_cell2Voltage 65535 "SNA" ;
VAL_ 1339 VCBATT1_a477_cell2Voltage 65535 "SNA" ;
VAL_ 1339 VCBATT1_a118_FRONTIPC_systemStatus 0 "UNKNOWN" 1 "RELEASED" 2 "PARKED" 3 "DYNAMIC" 4 "PARKING" 5 "RELEASING" 6 "FAULT" 7 "FAULT_SECURE" 8 "MISMATCH" ;
VAL_ 1339 VCBATT1_a182_serviceMode 0 "DISABLED" 1 "ENABLED" ;
VAL_ 1339 VCBATT1_a183_serviceMode 0 "DISABLED" 1 "ENABLED" ;
VAL_ 1339 VCBATT1_a527_cell2Voltage 65535 "SNA" ;
VAL_ 1339 VCBATT1_a555_cell2Voltage 65535 "SNA" ;
VAL_ 1339 VCBATT1_a104_BATTIPC_status 0 "DISABLED" 1 "ENABLED" 2 "TEMPORARY_FAILURE" 3 "SNA" ;
VAL_ 1339 VCBATT1_a118_BATTIPC_systemStatus 0 "UNKNOWN" 1 "RELEASED" 2 "PARKED" 3 "DYNAMIC" 4 "PARKING" 5 "RELEASING" 6 "FAULT" 7 "FAULT_SECURE" 8 "MISMATCH" ;
VAL_ 1339 VCBATT1_a182_transportMode 0 "DISABLED" 1 "ENABLED" ;
VAL_ 1339 VCBATT1_a183_transportMode 0 "DISABLED" 1 "ENABLED" ;
VAL_ 1339 VCBATT1_a525_serviceMode 0 "DISABLED" 1 "ENABLED" ;
VAL_ 1339 VCBATT1_a599_serviceMode 0 "DISABLED" 1 "ENABLED" ;
VAL_ 1339 VCBATT1_a476_factoryMode 0 "DISABLED" 1 "ENABLED" ;
VAL_ 1339 VCBATT1_a479_vehiclePowerState 0 "OFF" 1 "CONDITIONING" 2 "ACCESSORY" 3 "DRIVE" ;
VAL_ 1339 VCBATT1_a587_LVBMS_packCurrent 4294934528 "SNA" ;
VAL_ 1339 VCBATT1_a595_LVBMS_packVoltage 65535 "SNA" ;
VAL_ 1339 VCBATT1_a600_LVBMS_packCurrent 4294934528 "SNA" ;
VAL_ 1339 VCBATT1_a110_BATTIPC_status 0 "DISABLED" 1 "ENABLED" 2 "TEMPORARY_FAILURE" 3 "SNA" ;
VAL_ 1339 VCBATT1_a476_serviceMode 0 "DISABLED" 1 "ENABLED" ;
VAL_ 1339 VCBATT1_a548_hvState 0 "DOWN" 1 "COMING_UP" 2 "GOING_DOWN" 3 "UP_FOR_DRIVE" 4 "UP_FOR_CHARGE" 5 "UP_FOR_DC_CHARGE" 6 "UP" ;
VAL_ 1339 VCBATT1_a476_transportMode 0 "DISABLED" 1 "ENABLED" ;
VAL_ 1339 VCBATT1_a514_cell3Voltage 65535 "SNA" ;
VAL_ 1339 VCBATT1_a515_cell3Voltage 65535 "SNA" ;
VAL_ 1339 VCBATT1_a116_FRONTIPC_systemStatus 0 "UNKNOWN" 1 "RELEASED" 2 "PARKED" 3 "DYNAMIC" 4 "PARKING" 5 "RELEASING" 6 "FAULT" 7 "FAULT_SECURE" 8 "MISMATCH" ;
VAL_ 1339 VCBATT1_a182_ambientTemp 4294966273 "SNA" ;
VAL_ 1339 VCBATT1_a183_ambientTemp 4294966273 "SNA" ;
VAL_ 1339 VCBATT1_a432_packCurrent 4294934528 "SNA" ;
VAL_ 1339 VCBATT1_a476_vehiclePowerState 0 "OFF" 1 "CONDITIONING" 2 "ACCESSORY" 3 "DRIVE" ;
VAL_ 1339 VCBATT1_a479_batterySMState 0 "INIT" 1 "CHARGE" 2 "DISCHARGE" 3 "STANDBY" 4 "RESISTANCE_ESTIMATION" 5 "OTA_STANDBY" 6 "DISCONNECTED_BATTERY_TEST" 7 "SHORTED_CELL_TEST" 8 "FAULT" 9 "RECOVERY" ;
VAL_ 1339 VCBATT1_a512_packTemperature 511 "SNA" ;
VAL_ 1339 VCBATT1_a513_packTemperature 511 "SNA" ;
VAL_ 1339 VCBATT1_a561_cell1Voltage 65535 "SNA" ;
VAL_ 1339 VCBATT1_a562_cell1Voltage 65535 "SNA" ;
VAL_ 1339 VCBATT1_a113_FRONTIPC_status 0 "DISABLED" 1 "ENABLED" 2 "TEMPORARY_FAILURE" 3 "SNA" ;
VAL_ 1339 VCBATT1_a116_BATTIPC_systemStatus 0 "UNKNOWN" 1 "RELEASED" 2 "PARKED" 3 "DYNAMIC" 4 "PARKING" 5 "RELEASING" 6 "FAULT" 7 "FAULT_SECURE" 8 "MISMATCH" ;
VAL_ 1339 VCBATT1_a402_serviceMode 0 "DISABLED" 1 "ENABLED" ;
VAL_ 1339 VCBATT1_a117_BATTIPC_status 0 "DISABLED" 1 "ENABLED" 2 "TEMPORARY_FAILURE" 3 "SNA" ;
VAL_ 1339 VCBATT1_a191_MOSState 0 "OPEN" 1 "CLOSED" 2 "INVALID" 3 "SNA" ;
VAL_ 1339 VCBATT1_a446_cell3Voltage 65535 "SNA" ;
VAL_ 1339 VCBATT1_a476_batterySMState 0 "INIT" 1 "CHARGE" 2 "DISCHARGE" 3 "STANDBY" 4 "RESISTANCE_ESTIMATION" 5 "OTA_STANDBY" 6 "DISCONNECTED_BATTERY_TEST" 7 "SHORTED_CELL_TEST" 8 "FAULT" 9 "RECOVERY" ;
VAL_ 1339 VCBATT1_a477_cell3Voltage 65535 "SNA" ;
VAL_ 1339 VCBATT1_a478_factoryMode 0 "DISABLED" 1 "ENABLED" ;
VAL_ 1339 VCBATT1_a188_bridgeEFuseState 0 "UNKNOWN" 1 "STANDBY" 2 "WAKEUP" 3 "CONFIGURATION" 4 "UNLOCKED" 5 "LOCKED" 6 "SELF_TEST_PREP" 7 "SELF_TEST" ;
VAL_ 1339 VCBATT1_a220_factoryMode 0 "DISABLED" 1 "ENABLED" ;
VAL_ 1339 VCBATT1_a478_serviceMode 0 "DISABLED" 1 "ENABLED" ;
VAL_ 1339 VCBATT1_a220_serviceMode 0 "DISABLED" 1 "ENABLED" ;
VAL_ 1339 VCBATT1_a401_IBSVoltage 4095 "SNA" ;
VAL_ 1339 VCBATT1_a410_IBSVoltage 4095 "SNA" ;
VAL_ 1339 VCBATT1_a411_IBSVoltage 4095 "SNA" ;
VAL_ 1339 VCBATT1_a416_packCurrent 4294934528 "SNA" ;
VAL_ 1339 VCBATT1_a417_packCurrent 4294934528 "SNA" ;
VAL_ 1339 VCBATT1_a418_packCurrent 4294934528 "SNA" ;
VAL_ 1339 VCBATT1_a419_packCurrent 4294934528 "SNA" ;
VAL_ 1339 VCBATT1_a423_packCurrent 4294934528 "SNA" ;
VAL_ 1339 VCBATT1_a424_packCurrent 4294934528 "SNA" ;
VAL_ 1339 VCBATT1_a478_transportMode 0 "DISABLED" 1 "ENABLED" ;
VAL_ 1339 VCBATT1_a503_packCurrent 4294934528 "SNA" ;
VAL_ 1339 VCBATT1_a527_cell3Voltage 65535 "SNA" ;
VAL_ 1339 VCBATT1_a555_cell3Voltage 65535 "SNA" ;
VAL_ 1339 VCBATT1_a559_vehiclePowerState 0 "OFF" 1 "CONDITIONING" 2 "ACCESSORY" 3 "DRIVE" ;
VAL_ 1339 VCBATT1_a180_serviceMode 0 "DISABLED" 1 "ENABLED" ;
VAL_ 1339 VCBATT1_a514_cell4Voltage 65535 "SNA" ;
VAL_ 1339 VCBATT1_a515_cell4Voltage 65535 "SNA" ;
VAL_ 1339 VCBATT1_a180_transportMode 0 "DISABLED" 1 "ENABLED" ;
VAL_ 1339 VCBATT1_a476_ECPAState 0 "OPEN" 1 "CLOSED" 2 "INVALID" 3 "SNA" ;
VAL_ 1339 VCBATT1_a595_IBSVoltage 4095 "SNA" ;
VAL_ 1339 VCBATT1_a117_BATTIPC_systemStatus 0 "UNKNOWN" 1 "RELEASED" 2 "PARKED" 3 "DYNAMIC" 4 "PARKING" 5 "RELEASING" 6 "FAULT" 7 "FAULT_SECURE" 8 "MISMATCH" ;
VAL_ 1339 VCBATT1_a462_serviceMode 0 "DISABLED" 1 "ENABLED" ;
VAL_ 1339 VCBATT1_a561_cell2Voltage 65535 "SNA" ;
VAL_ 1339 VCBATT1_a562_cell2Voltage 65535 "SNA" ;
VAL_ 1339 VCBATT1_a221_serviceMode 0 "DISABLED" 1 "ENABLED" ;
VAL_ 1339 VCBATT1_a260_vehiclePowerState 0 "OFF" 1 "CONDITIONING" 2 "ACCESSORY" 3 "DRIVE" ;
VAL_ 1339 VCBATT1_a359_vehiclePowerState 0 "OFF" 1 "CONDITIONING" 2 "ACCESSORY" 3 "DRIVE" ;
VAL_ 1339 VCBATT1_a510_serviceMode 0 "DISABLED" 1 "ENABLED" ;
VAL_ 1339 VCBATT1_a512_sumCellVoltage 65534 "INVALID" 65535 "SNA" ;
VAL_ 1339 VCBATT1_a513_packVoltage 65535 "SNA" ;
VAL_ 1339 VCBATT1_a521_ambientTemp 4294966273 "SNA" ;
VAL_ 1339 VCBATT1_a559_batterySMState 0 "INIT" 1 "CHARGE" 2 "DISCHARGE" 3 "STANDBY" 4 "RESISTANCE_ESTIMATION" 5 "OTA_STANDBY" 6 "DISCONNECTED_BATTERY_TEST" 7 "SHORTED_CELL_TEST" 8 "FAULT" 9 "RECOVERY" ;
VAL_ 1339 VCBATT1_a370_serviceMode 0 "DISABLED" 1 "ENABLED" ;
VAL_ 1339 VCBATT1_a260_batterySMState 0 "INIT" 1 "CHARGE" 2 "DISCHARGE" 3 "STANDBY" 4 "RESISTANCE_ESTIMATION" 5 "OTA_STANDBY" 6 "DISCONNECTED_BATTERY_TEST" 7 "SHORTED_CELL_TEST" 8 "FAULT" 9 "RECOVERY" ;
VAL_ 1339 VCBATT1_a359_batterySMState 0 "INIT" 1 "CHARGE" 2 "DISCHARGE" 3 "STANDBY" 4 "RESISTANCE_ESTIMATION" 5 "OTA_STANDBY" 6 "DISCONNECTED_BATTERY_TEST" 7 "SHORTED_CELL_TEST" 8 "FAULT" 9 "RECOVERY" ;
VAL_ 1339 VCBATT1_a370_sleepCurrent 4095 "SNA" ;
VAL_ 1339 VCBATT1_a446_cell4Voltage 65535 "SNA" ;
VAL_ 1339 VCBATT1_a477_cell4Voltage 65535 "SNA" ;
VAL_ 1339 VCBATT1_a191_ECPAState 0 "OPEN" 1 "CLOSED" 2 "INVALID" 3 "SNA" ;
VAL_ 1339 VCBATT1_a514_packVoltage 65535 "SNA" ;
VAL_ 1339 VCBATT1_a515_packVoltage 65535 "SNA" ;
VAL_ 1339 VCBATT1_a548_serviceMode 0 "DISABLED" 1 "ENABLED" ;
VAL_ 1339 VCBATT1_a527_cell4Voltage 65535 "SNA" ;
VAL_ 1339 VCBATT1_a555_cell4Voltage 65535 "SNA" ;
VAL_ 1339 VCBATT1_a561_cell3Voltage 65535 "SNA" ;
VAL_ 1339 VCBATT1_a562_cell3Voltage 65535 "SNA" ;
VAL_ 1339 VCBATT1_a180_IBSVoltage 4095 "SNA" ;
VAL_ 1339 VCBATT1_a188_vehiclePowerState 0 "OFF" 1 "CONDITIONING" 2 "ACCESSORY" 3 "DRIVE" ;
VAL_ 1339 VCBATT1_a191_serviceMode 0 "DISABLED" 1 "ENABLED" ;
VAL_ 1339 VCBATT1_a359_hvState 0 "DOWN" 1 "COMING_UP" 2 "GOING_DOWN" 3 "UP_FOR_DRIVE" 4 "UP_FOR_CHARGE" 5 "UP_FOR_DC_CHARGE" 6 "UP" ;
VAL_ 1339 VCBATT1_a521_serviceMode 0 "DISABLED" 1 "ENABLED" ;
VAL_ 1339 VCBATT1_a420_vehicleSpeed 8191 "SNA" ;
VAL_ 1339 VCBATT1_a191_vehicleLoadShedStage 0 "IDLE_OR_UNDEFINED" 1 "1" 2 "2" 3 "3" ;
VAL_ 1339 VCBATT1_a512_serviceMode 0 "DISABLED" 1 "ENABLED" ;
VAL_ 1339 VCBATT1_a559_factoryMode 0 "DISABLED" 1 "ENABLED" ;
VAL_ 1339 VCBATT1_a559_serviceMode 0 "DISABLED" 1 "ENABLED" ;
VAL_ 1339 VCBATT1_a370_SOC 127 "SNA" ;
VAL_ 1339 VCBATT1_a407_IBSTemperature 32767 "IBS_TEMPERATURE_SNA" ;
VAL_ 1339 VCBATT1_a446_sumCellVoltage 65534 "INVALID" 65535 "SNA" ;
VAL_ 1339 VCBATT1_a477_sumCellVoltage 65534 "INVALID" 65535 "SNA" ;
VAL_ 1339 VCBATT1_a512_vehiclePowerState 0 "OFF" 1 "CONDITIONING" 2 "ACCESSORY" 3 "DRIVE" ;
VAL_ 1339 VCBATT1_a559_transportMode 0 "DISABLED" 1 "ENABLED" ;
VAL_ 1339 VCBATT1_a600_version 254 "LOCAL_BUILD" 255 "SNA" ;
VAL_ 1339 VCBATT1_a406_IBSTemperature 32767 "IBS_TEMPERATURE_SNA" ;
VAL_ 1339 VCBATT1_a561_cell4Voltage 65535 "SNA" ;
VAL_ 1339 VCBATT1_a562_cell4Voltage 65535 "SNA" ;
VAL_ 1339 VCBATT1_a260_serviceMode 0 "DISABLED" 1 "ENABLED" ;
VAL_ 1339 VCBATT1_a359_serviceMode 0 "DISABLED" 1 "ENABLED" ;
VAL_ 1339 VCBATT1_a196_ECPAState 0 "OPEN" 1 "CLOSED" 2 "INVALID" 3 "SNA" ;
VAL_ 1339 VCBATT1_a527_serviceMode 0 "DISABLED" 1 "ENABLED" ;
VAL_ 1339 VCBATT1_a541_SOC 127 "SNA" ;
VAL_ 1339 VCBATT1_a253_serviceMode 0 "DISABLED" 1 "ENABLED" ;
VAL_ 1339 VCBATT1_a513_serviceMode 0 "DISABLED" 1 "ENABLED" ;
VAL_ 1339 VCBATT1_a518_serviceMode 0 "DISABLED" 1 "ENABLED" ;
VAL_ 1339 VCBATT1_a513_vehiclePowerState 0 "OFF" 1 "CONDITIONING" 2 "ACCESSORY" 3 "DRIVE" ;
VAL_ 1339 VCBATT1_a514_serviceMode 0 "DISABLED" 1 "ENABLED" ;
VAL_ 1339 VCBATT1_a515_serviceMode 0 "DISABLED" 1 "ENABLED" ;
VAL_ 1339 VCBATT1_a561_factoryMode 0 "DISABLED" 1 "ENABLED" ;
VAL_ 1339 VCBATT1_a562_factoryMode 0 "DISABLED" 1 "ENABLED" ;
VAL_ 1339 VCBATT1_a420_DI_gear 0 "INVALID" 1 "P" 2 "R" 3 "N" 4 "D" 7 "SNA" ;
VAL_ 1339 VCBATT1_a446_serviceMode 0 "DISABLED" 1 "ENABLED" ;
VAL_ 1339 VCBATT1_a477_serviceMode 0 "DISABLED" 1 "ENABLED" ;
VAL_ 1339 VCBATT1_a518_vehiclePowerState 0 "OFF" 1 "CONDITIONING" 2 "ACCESSORY" 3 "DRIVE" ;
VAL_ 1339 VCBATT1_a561_serviceMode 0 "DISABLED" 1 "ENABLED" ;
VAL_ 1339 VCBATT1_a562_serviceMode 0 "DISABLED" 1 "ENABLED" ;
VAL_ 1339 VCBATT1_a412_serviceMode 0 "DISABLED" 1 "ENABLED" ;
VAL_ 1339 VCBATT1_a514_vehiclePowerState 0 "OFF" 1 "CONDITIONING" 2 "ACCESSORY" 3 "DRIVE" ;
VAL_ 1339 VCBATT1_a515_vehiclePowerState 0 "OFF" 1 "CONDITIONING" 2 "ACCESSORY" 3 "DRIVE" ;
VAL_ 1342 CP_infoIndex 0 "DEPRECATED_0" 1 "DEPRECATED_1" 2 "DEPRECATED_2" 3 "DEPRECATED_3" 4 "DEPRECATED_4" 5 "DEPRECATED_5" 6 "DEPRECATED_6" 7 "DEPRECATED_7" 8 "DEPRECATED_8" 9 "DEPRECATED_9" 10 "BUILD_HWID_COMPONENTID" 11 "PCBAID_ASSYID_USAGEID" 13 "APP_CRC" 14 "BOOTLOADER_SVN" 15 "BOOTLOADER_CRC" 16 "SUBCOMPONENT" 17 "APP_GITHASH" 18 "BOOTLOADER_GITHASH" 19 "VERSION_DEPRECATED" 20 "UDS_PROTOCOL_BOOTCRC" 22 "VARIANTCRC" 25 "PACKAGE_PN_1_7" 26 "PACKAGE_PN_8_14" 27 "PACKAGE_PN_15_20" 29 "PACKAGE_SN_1_7" 30 "PACKAGE_SN_8_14" 31 "SUBCOMPONENT_GITHASH" 255 "END" ;
VAL_ 1342 CP_buildType 0 "UNKNOWN_BUILD" 1 "PLATFORM_BUILD" 2 "LOCAL_BUILD" 3 "TRACEABLE_CI_BUILD" 4 "MFG_BUILD" ;
VAL_ 1342 CP_platformType 0 "UNKNOWN" 3 "MODEL3" 255 "END" ;
VAL_ 1342 CP_hardwareId 252 "CONFIGURABLE_HWID_PLACEHOLDER" ;
VAL_ 1343 BMS_alertID 0 "ALERT_DO_NOT_USE_ZERO" 1 "a001_DriverDoorOpen" 2 "a002_DoorOpen" 3 "a003_TrunkOpen" 4 "a004_FrunkOpen" 5 "a005_HeadlightsOnDoorOpen" 6 "a006_RemoteServiceAlert" 7 "a007_SoftPackConfigMismatch" 8 "a008_TouchScreenError" 9 "a009_SquashfsError" 10 "a010_MapsMissing" 11 "a011_IncorrectMap" 12 "a012_NotOnPrivateProperty" 13 "a013_TPMSHardWarning" 14 "a014_TPMSSoftWarning" 15 "a015_TPMSOverPressureWarning" 16 "a016_TPMSTemperatureWarning" 17 "a017_TPMSSystemFault" 18 "a018_SlipStartOn" 19 "a019_ParkBrakeFault" 20 "a020_SteeringReduced" 21 "a021_RearSeatbeltUnbuckled" 22 "a022_ApeFusesEtc" 23 "a023_CellInternetCheckFailed" 24 "a024_WifiInternetCheckFailed" 25 "a025_WifiOnlineCheckFailed" 26 "a026_ModemResetLoopDetected" 27 "a027_AutoSteerMIA" 28 "a028_FrontTrunkPopupClosed" 29 "a029_ModemMIA" 30 "a030_ModemVMCrash" 31 "a031_BrakeFluidLow" 32 "a032_CellModemRecoveryResets" 33 "a033_ApTrialExpired" 34 "a034_WakeupProblem" 35 "a035_AudioWatchdogKernelError" 36 "a036_AudioWatchdogHfpError" 37 "a037_AudioWatchdogXrunStormError" 38 "a038_AudioWatchdogA2bI2cLockupError" 39 "a039_AudioA2bNeedRediscovery" 40 "a040_HomelinkTransmit" 41 "a041_AudioDmesgXrun" 42 "a042_AudioDmesgRtThrottling" 43 "a043_InvalidMapDataOverride" 44 "a044_AudioDmesgDspException" 45 "a045_ECallNeedsService" 46 "a046_BackupCameraStreamError" 47 "a047_CellRoamingDisallowed" 48 "a048_AudioPremiumAmpCheckFailed" 49 "a049_BrakeShiftRequired" 50 "a050_BackupCameraIPUTimeout" 51 "a051_BackupCameraFrameTimeout" 52 "a052_KernelPanicReported" 53 "a053_QtCarExitError" 54 "a054_AudioBoostPowerBad" 55 "a055_ManualECallDisabled" 56 "a056_ManualECallButtonDisconnected" 57 "a057_CellAntennaDisconnected" 58 "a058_GPSAntennaDisconnected" 59 "a059_ECallSpeakerDisconnected" 60 "a060_ECallMicDisconnected" 61 "a061_SIMTestFailed" 62 "a062_ENSTestFailed" 63 "a063_CellularTestFailed" 64 "a064_ModemFirmwareTestFailed" 65 "a065_WiFiRecoveryReset" 66 "a066_GpuHangDetected" 67 "a067_WarnOnI915" 68 "a068_VideoUnexpectedExit" 69 "a069_VideoUDPTimeout" 70 "a070_VideoPipelineWarning" 71 "a071_VideoPipelineError" 72 "a072_ECallAnalogMicFailed" 73 "a073_ECallDigitalMicFailed" 74 "a074_EMMCHangDetected" 75 "a075_BackupCameraInitError" 76 "a076_NumFalseManualECalls" 77 "a077_AudioA2bMicChannelSwap" 78 "a078_DashcamUsbDriveUnmountable" 79 "a079_DashcamUsbDriveFull" 80 "a080_DashcamUsbDriveSlow" 81 "a081_CellModemSearchExpired" 82 "a082_NumModemRebootStuckInECall" 83 "a083_ECallProxyWatchdogTriggered" 84 "a084_SerializerError" 85 "a085_DeserializerError" 86 "a086_TouchEnumerationError" 87 "a087_BmpReset" 88 "a088_CellRemovableSimMissing" 89 "a089_RadioSoftResetError" 90 "a090_RadioPingFailError" 91 "a091_VehicleLinkStall" 92 "a092_updateStarted" 93 "a093_updateEnded" 94 "a094_ModemPowerOnFailure" 95 "a095_CidStorageRunningLow" 96 "a096_VideodPipelineIssueDetected" 97 "a097_AudiodRestarted" 98 "a098_DiskCheckFailure" 99 "a099_eMMCStatusError" 100 "a100_eMMCFTLError" 101 "a101_wifiStackProblem" 102 "a102_A2bDiscoveryFailed" 103 "a103_UsbHubNotEnumerating" 104 "a104_DashcamUsbDriveMissing" 105 "a105_firmwareReinstallRequested" 106 "a106_rebootBackstopTriggered" 107 "a107_DashcamUsbDriveTooBigForVfatFsck" 108 "a108_DashcamUsbDriveGettingFull" 109 "a109_DashcamUsbDriveTooSmall" 110 "a110_DashcamUsbDriveCorrupt" 111 "a111_DashcamUsbDriveWrongPort" 112 "a112_badUSBDevice" 113 "a113_DashcamHasOnboardSentryClips" ;
VAL_ 1343 BMS_a003_calBlockData_0 0 "0" 1 "1" 2 "2" 3 "3" 4 "4" 5 "5" 6 "6" 7 "7" 8 "8" 9 "9" 10 "10" 11 "11" 12 "12" 13 "13" 14 "14" 15 "15" 16 "16" 17 "17" 18 "18" 19 "19" 20 "20" 21 "21" 22 "22" 23 "23" 24 "24" 25 "25" 26 "26" 27 "27" 28 "28" 29 "29" 30 "30" 31 "31" ;
VAL_ 1343 BMS_a017_packCurrent 4294934528 "SNA" ;
VAL_ 1343 BMS_a018_packCurrent 4294934528 "SNA" ;
VAL_ 1343 BMS_a020_packCurrent 4294934528 "SNA" ;
VAL_ 1343 BMS_a026_packCurrent 4294934528 "SNA" ;
VAL_ 1343 BMS_a034_packVoltage 65535 "SNA" ;
VAL_ 1343 BMS_a062_state 0 "STANDBY" 1 "DRIVE" 2 "SUPPORT" 3 "CHARGE" 4 "FEIM" 5 "CLEAR_FAULT" 6 "FAULT" 7 "WELD" 8 "TEST" 9 "SNA" 10 "DIAG" ;
VAL_ 1343 BMS_a070_state 0 "STANDBY" 1 "DRIVE" 2 "SUPPORT" 3 "CHARGE" 4 "FEIM" 5 "CLEAR_FAULT" 6 "FAULT" 7 "WELD" 8 "TEST" 9 "SNA" 10 "DIAG" ;
VAL_ 1343 BMS_a075_chargeType 0 "UNDEFINED" 1 "CONSTANT_CURRENT" 2 "CONSTANT_VOLTAGE" 3 "COMPLETE" 4 "SNA" ;
VAL_ 1343 BMS_a084_sleepState 0 "IDLE" 1 "WAIT_FOR_BUS_SILENCE" 2 "READY" 3 "GOING_TO_SLEEP" 4 "SLEEPING" 5 "ABORT" 6 "FAULT" 7 "MIA" 8 "UNKNOWN" 9 "COUNT" ;
VAL_ 1343 BMS_a134_packCurrent 4294934528 "SNA" ;
VAL_ 1343 BMS_a137_SOC 127 "SNA" ;
VAL_ 1343 BMS_a138_SOC 127 "SNA" ;
VAL_ 1343 BMS_a139_packVoltage 65535 "SNA" ;
VAL_ 1343 BMS_a142_isolationResistance 1023 "SNA" ;
VAL_ 1343 BMS_a144_HVP_major_version 254 "LOCAL_BUILD" 255 "SNA" ;
VAL_ 1343 BMS_a154_packCurrent 4294934528 "SNA" ;
VAL_ 1343 BMS_a196_packVoltage 65535 "SNA" ;
VAL_ 1343 BMS_a071_state 0 "STANDBY" 1 "DRIVE" 2 "SUPPORT" 3 "CHARGE" 4 "FEIM" 5 "CLEAR_FAULT" 6 "FAULT" 7 "WELD" 8 "TEST" 9 "SNA" 10 "DIAG" ;
VAL_ 1343 BMS_a085_packContactorSetState 0 "SNA" 1 "OPEN" 2 "CLOSING" 3 "BLOCKED" 4 "OPENING" 5 "CLOSED" 6 "PARTIAL_WELD" 7 "WELDED" 8 "POSITIVE_CLOSED" 9 "NEGATIVE_CLOSED" ;
VAL_ 1343 BMS_a086_fcContactorSetState 0 "SNA" 1 "OPEN" 2 "CLOSING" 3 "BLOCKED" 4 "OPENING" 5 "CLOSED" 6 "PARTIAL_WELD" 7 "WELDED" 8 "POSITIVE_CLOSED" 9 "NEGATIVE_CLOSED" ;
VAL_ 1343 BMS_a021_currentLimit 8191 "SNA" ;
VAL_ 1343 BMS_a134_SOC 127 "SNA" ;
VAL_ 1343 BMS_a146_state 0 "STANDBY" 1 "DRIVE" 2 "SUPPORT" 3 "CHARGE" 4 "FEIM" 5 "CLEAR_FAULT" 6 "FAULT" 7 "WELD" 8 "TEST" 9 "SNA" 10 "DIAG" ;
VAL_ 1343 BMS_a034_packContactorSetState 0 "SNA" 1 "OPEN" 2 "CLOSING" 3 "BLOCKED" 4 "OPENING" 5 "CLOSED" 6 "PARTIAL_WELD" 7 "WELDED" 8 "POSITIVE_CLOSED" 9 "NEGATIVE_CLOSED" ;
VAL_ 1343 BMS_a039_packVoltage 65535 "SNA" ;
VAL_ 1343 BMS_a177_energyBuffer 255 "SNA" ;
VAL_ 1343 BMS_a056_packVoltage 65535 "SNA" ;
VAL_ 1343 BMS_a021_packCurrent 4294934528 "SNA" ;
VAL_ 1343 BMS_a059_packVoltage 65535 "SNA" ;
VAL_ 1343 BMS_a069_SOC 127 "SNA" ;
VAL_ 1343 BMS_a137_packCurrent 4294934528 "SNA" ;
VAL_ 1343 BMS_a138_packCurrent 4294934528 "SNA" ;
VAL_ 1343 BMS_a144_HVP_minor_version 254 "LOCAL_BUILD" 255 "SNA" ;
VAL_ 1343 BMS_a146_packCurrent 4294934528 "SNA" ;
VAL_ 1343 BMS_a032_packCurrent 4294934528 "SNA" ;
VAL_ 1343 BMS_a033_packCurrent 4294934528 "SNA" ;
VAL_ 1343 BMS_a039_packCurrent 4294934528 "SNA" ;
VAL_ 1343 BMS_a077_packCurrent 4294934528 "SNA" ;
VAL_ 1343 BMS_a144_BMS_minor_version 254 "LOCAL_BUILD" 255 "SNA" ;
VAL_ 1343 BMS_a024_packCurrent 4294934528 "SNA" ;
VAL_ 1343 BMS_a039_state 0 "STANDBY" 1 "DRIVE" 2 "SUPPORT" 3 "CHARGE" 4 "FEIM" 5 "CLEAR_FAULT" 6 "FAULT" 7 "WELD" 8 "TEST" 9 "SNA" 10 "DIAG" ;
VAL_ 1344 SCCM_alertID 0 "ALERT_DO_NOT_USE_ZERO" 1 "a001_DriverDoorOpen" 2 "a002_DoorOpen" 3 "a003_TrunkOpen" 4 "a004_FrunkOpen" 5 "a005_HeadlightsOnDoorOpen" 6 "a006_RemoteServiceAlert" 7 "a007_SoftPackConfigMismatch" 8 "a008_TouchScreenError" 9 "a009_SquashfsError" 10 "a010_MapsMissing" 11 "a011_IncorrectMap" 12 "a012_NotOnPrivateProperty" 13 "a013_TPMSHardWarning" 14 "a014_TPMSSoftWarning" 15 "a015_TPMSOverPressureWarning" 16 "a016_TPMSTemperatureWarning" 17 "a017_TPMSSystemFault" 18 "a018_SlipStartOn" 19 "a019_ParkBrakeFault" 20 "a020_SteeringReduced" 21 "a021_RearSeatbeltUnbuckled" 22 "a022_ApeFusesEtc" 23 "a023_CellInternetCheckFailed" 24 "a024_WifiInternetCheckFailed" 25 "a025_WifiOnlineCheckFailed" 26 "a026_ModemResetLoopDetected" 27 "a027_AutoSteerMIA" 28 "a028_FrontTrunkPopupClosed" 29 "a029_ModemMIA" 30 "a030_ModemVMCrash" 31 "a031_BrakeFluidLow" 32 "a032_CellModemRecoveryResets" 33 "a033_ApTrialExpired" 34 "a034_WakeupProblem" 35 "a035_AudioWatchdogKernelError" 36 "a036_AudioWatchdogHfpError" 37 "a037_AudioWatchdogXrunStormError" 38 "a038_AudioWatchdogA2bI2cLockupError" 39 "a039_AudioA2bNeedRediscovery" 40 "a040_HomelinkTransmit" 41 "a041_AudioDmesgXrun" 42 "a042_AudioDmesgRtThrottling" 43 "a043_InvalidMapDataOverride" 44 "a044_AudioDmesgDspException" 45 "a045_ECallNeedsService" 46 "a046_BackupCameraStreamError" 47 "a047_CellRoamingDisallowed" 48 "a048_AudioPremiumAmpCheckFailed" 49 "a049_BrakeShiftRequired" 50 "a050_BackupCameraIPUTimeout" 51 "a051_BackupCameraFrameTimeout" 52 "a052_KernelPanicReported" 53 "a053_QtCarExitError" 54 "a054_AudioBoostPowerBad" 55 "a055_ManualECallDisabled" 56 "a056_ManualECallButtonDisconnected" 57 "a057_CellAntennaDisconnected" 58 "a058_GPSAntennaDisconnected" 59 "a059_ECallSpeakerDisconnected" 60 "a060_ECallMicDisconnected" 61 "a061_SIMTestFailed" 62 "a062_ENSTestFailed" 63 "a063_CellularTestFailed" 64 "a064_ModemFirmwareTestFailed" 65 "a065_WiFiRecoveryReset" 66 "a066_GpuHangDetected" 67 "a067_WarnOnI915" 68 "a068_VideoUnexpectedExit" 69 "a069_VideoUDPTimeout" 70 "a070_VideoPipelineWarning" 71 "a071_VideoPipelineError" 72 "a072_ECallAnalogMicFailed" 73 "a073_ECallDigitalMicFailed" 74 "a074_EMMCHangDetected" 75 "a075_BackupCameraInitError" 76 "a076_NumFalseManualECalls" 77 "a077_AudioA2bMicChannelSwap" 78 "a078_DashcamUsbDriveUnmountable" 79 "a079_DashcamUsbDriveFull" 80 "a080_DashcamUsbDriveSlow" 81 "a081_CellModemSearchExpired" 82 "a082_NumModemRebootStuckInECall" 83 "a083_ECallProxyWatchdogTriggered" 84 "a084_SerializerError" 85 "a085_DeserializerError" 86 "a086_TouchEnumerationError" 87 "a087_BmpReset" 88 "a088_CellRemovableSimMissing" 89 "a089_RadioSoftResetError" 90 "a090_RadioPingFailError" 91 "a091_VehicleLinkStall" 92 "a092_updateStarted" 93 "a093_updateEnded" 94 "a094_ModemPowerOnFailure" 95 "a095_CidStorageRunningLow" 96 "a096_VideodPipelineIssueDetected" 97 "a097_AudiodRestarted" 98 "a098_DiskCheckFailure" 99 "a099_eMMCStatusError" 100 "a100_eMMCFTLError" 101 "a101_wifiStackProblem" 102 "a102_A2bDiscoveryFailed" 103 "a103_UsbHubNotEnumerating" 104 "a104_DashcamUsbDriveMissing" 105 "a105_firmwareReinstallRequested" 106 "a106_rebootBackstopTriggered" 107 "a107_DashcamUsbDriveTooBigForVfatFsck" 108 "a108_DashcamUsbDriveGettingFull" 109 "a109_DashcamUsbDriveTooSmall" 110 "a110_DashcamUsbDriveCorrupt" 111 "a111_DashcamUsbDriveWrongPort" 112 "a112_badUSBDevice" 113 "a113_DashcamHasOnboardSentryClips" ;
VAL_ 1344 SCCM_alertState 0 "CLEARED" 1 "SET" ;
VAL_ 1345 FC_maxPowerLimit 8191 "SNA" ;
VAL_ 1345 FC_maxCurrentLimit 8191 "SNA" ;
